VERSION "Generated from PQ35_46 ACAN KMatrix"

NS_ :

BS_:

BU_: XXX AFS Airbag Allrad AppGW_SK BAP_Tester BMS_Hybrid Bremse_ESP_AU714 Bremse_ESP_EPB_EBC460Vi Bremse_MK100_ESC Bremse_MK60EC Bremse_MK70MABS Bremse_TRW_EBC450M Bremse_TRW_ESP Daempfer EPB_TRW EPB_TRW_VW411CS ESP_AU316 FLA Gateway_PQ35 Getriebe_AG6 Getriebe_DL800_R8 Getriebe_DL800_ZSG_R8 Getriebe_DQ Getriebe_DQ_Hyb Getriebe_Sele Gurtmikro_PQ35 HCA LEH_Hybrid LH_EPS_APA LH_EPS_ZF_2G LH_EPS_ZF_3G LPG_Interface_Box LWR LWS Magne_Ride Motor_Diesel Motor_Hybrid Motor_Otto Motor_Slave PDC_PLA Quersperre_VAQ RKA_Plus SAK Waehlhebel Waehlhebel_Sele

BO_ 1494 mPLA_Status: 5 XXX
 SG_ PLS_Bremsleuchte : 30|1@1+ (1,0) [0|1] "" Bremse_MK60EC,Bremse_TRW_ESP,Gateway_PQ35
 SG_ PLS_Anf_Anz : 0|1@1+ (1,0) [0|1] "" Gateway_PQ35
 SG_ PLS_Akustik1 : 1|1@1+ (1,0) [0|1] "" Gateway_PQ35
 SG_ PLS_PL_Exist : 2|1@1+ (1,0) [0|1] "" Gateway_PQ35
 SG_ PLS_Akustik2 : 3|1@1+ (1,0) [0|1] "" Gateway_PQ35
 SG_ PLS_Mehrzg_Aktiv : 4|1@1+ (1,0) [0|1] "" Gateway_PQ35
 SG_ PLS_Pos_OK : 5|1@1+ (1,0) [0|1] "" Gateway_PQ35
 SG_ PLS_PL_Seite : 6|1@1+ (1,0) [0|1] "" Gateway_PQ35
 SG_ PLS_Lenk_Aktiv_Hinweis : 7|1@1+ (1,0) [0|1] "" Gateway_PQ35
 SG_ PLS_Meldungen : 8|5@1+ (1,0) [0|0] "" Gateway_PQ35
 SG_ PLS_Fahrtrichtg_Mehrzg : 13|1@1+ (1,0) [0|1] "" Gateway_PQ35
 SG_ PLS_Text_Multiplexer : 14|2@1+ (1,0) [0|3] "" Gateway_PQ35
 SG_ PLS_Schwellpfeil_rel : 16|4@1+ (1,0) [0|15] "" Gateway_PQ35
 SG_ PLS_Anf_Anz_Schwellpfeil : 20|1@1+ (1,0) [0|1] "" Gateway_PQ35
 SG_ PLS_Laengs_Querluecke : 21|1@1+ (1,0) [0|1] "" Gateway_PQ35
 SG_ PLS_Standby : 22|1@1+ (1,0) [0|1] "" Gateway_PQ35
 SG_ PLS_Bremssymbol : 23|1@1+ (1,0) [0|1] "" Gateway_PQ35
 SG_ PLS_Kurze_Luecke : 24|1@1+ (1,0) [0|1] "" Gateway_PQ35
 SG_ PLS_Schwellpfeil_abs : 25|2@1+ (1,0) [0|3] "" Gateway_PQ35
 SG_ PLS_Akustik : 27|2@1+ (1,0) [0|3] "" Gateway_PQ35
 SG_ PLS_Ausparken_Aktiv : 29|1@1+ (1,0) [0|1] "" Gateway_PQ35
 SG_ PLS_Texte : 31|7@1+ (1,0) [0|32] "" Gateway_PQ35

BO_ 1500 mSoll_Verbauliste_neu: 8 XXX
 SG_ VL1_Motor_SG : 0|1@1+ (1,0) [0|1] "" Bremse_TRW_ESP
 SG_ VL1_Getr_SG : 1|1@1+ (1,0) [0|1] "" Bremse_TRW_ESP
 SG_ VL1_LSM : 4|1@1+ (1,0) [0|1] "" Bremse_TRW_ESP,Motor_Hybrid,Motor_Otto
 SG_ VL1_Airbag : 5|1@1+ (1,0) [0|1] "" Bremse_MK100_ESC,Bremse_TRW_ESP,Motor_Hybrid,Motor_Otto
 SG_ VL1_Allrad : 9|1@1+ (1,0) [0|1] "" Bremse_ESP_EPB_EBC460Vi,Bremse_MK100_ESC,Bremse_MK60EC,Bremse_MK70MABS,Bremse_TRW_EBC450M,Bremse_TRW_ESP,ESP_AU316
 SG_ VL1_ADR : 10|1@1+ (1,0) [0|1] "" Bremse_ESP_EPB_EBC460Vi,Bremse_MK60EC,Bremse_TRW_EBC450M,Bremse_TRW_ESP
 SG_ VL1_Anhaenger : 44|1@1+ (1,0) [0|1] "" Bremse_ESP_EPB_EBC460Vi,Bremse_TRW_EBC450M,Bremse_TRW_ESP,ESP_AU316
 SG_ VL1_ABS : 2|1@1+ (1,0) [0|1] "" Bremse_MK100_ESC,Motor_Hybrid,Motor_Otto
 SG_ VL1_Kombi : 3|1@1+ (1,0) [0|1] "" XXX
 SG_ VL1_Lenkhilfe : 6|1@1+ (1,0) [0|1] "" Bremse_MK60EC
 SG_ VL1_dyn_LWR : 7|1@1+ (1,0) [0|1] "" XXX
 SG_ VL1_res_08 : 8|1@1+ (1,0) [0|1] "" XXX
 SG_ VL1_ADR_getrennt : 11|1@1+ (1,0) [0|1] "" XXX
 SG_ VL1_EPB : 12|1@1+ (1,0) [0|1] "" XXX
 SG_ VL1_res_13 : 13|1@1+ (1,0) [0|1] "" XXX
 SG_ VL1_Daempfer : 14|1@1+ (1,0) [0|1] "" Bremse_MK100_ESC,Bremse_MK60EC
 SG_ VL1_Quersperre : 15|1@1+ (1,0) [0|1] "" Bremse_MK60EC
 SG_ VL1_MotorSlave : 16|1@1+ (1,0) [0|1] "" XXX
 SG_ VL1_SWA : 17|1@1+ (1,0) [0|1] "" XXX
 SG_ VL1_HCA : 18|1@1+ (1,0) [0|1] "" HCA
 SG_ VL1_RKA_Plus : 19|1@1+ (1,0) [0|1] "" XXX
 SG_ VL1_PLA : 20|1@1+ (1,0) [0|1] "" XXX
 SG_ VL1_WFS_KBI : 21|1@1+ (1,0) [0|1] "" XXX
 SG_ VL1_Kombi_KBI : 22|1@1+ (1,0) [0|1] "" XXX
 SG_ VL1_Soll_eq_Ist : 23|1@1+ (1,0) [0|1] "" Bremse_MK60EC,Motor_Hybrid,Motor_Otto
 SG_ VL1_BSG_Komf : 24|1@1+ (1,0) [0|1] "" Motor_Hybrid,Motor_Otto
 SG_ VL1_ZKE : 25|1@1+ (1,0) [0|1] "" XXX
 SG_ VL1_TSG_FT : 26|1@1+ (1,0) [0|1] "" XXX
 SG_ VL1_TSG_BT : 27|1@1+ (1,0) [0|1] "" XXX
 SG_ VL1_TSG_HL : 28|1@1+ (1,0) [0|1] "" XXX
 SG_ VL1_TSG_HR : 29|1@1+ (1,0) [0|1] "" XXX
 SG_ VL1_Memory : 30|1@1+ (1,0) [0|1] "" XXX
 SG_ VL1_Dachmodul_K : 31|1@1+ (1,0) [0|1] "" XXX
 SG_ VL1_Zentralelektrik_II : 32|1@1+ (1,0) [0|1] "" XXX
 SG_ VL1_RDK : 33|1@1+ (1,0) [0|1] "" XXX
 SG_ VL1_Lenksaeule : 34|1@1+ (1,0) [0|1] "" Motor_Hybrid,Motor_Otto
 SG_ VL1_Gateway : 35|1@1+ (1,0) [0|1] "" Motor_Hybrid,Motor_Otto
 SG_ VL1_Clima_Komf : 36|1@1+ (1,0) [0|1] "" Motor_Diesel,Motor_Hybrid,Motor_Otto
 SG_ VL1_Einparkhilfe : 37|1@1+ (1,0) [0|1] "" XXX
 SG_ VL1_PTC_Heizung : 38|1@1+ (1,0) [0|1] "" XXX
 SG_ VL1_Standheiz : 39|1@1+ (1,0) [0|1] "" XXX
 SG_ VL1_Verdeck : 40|1@1+ (1,0) [0|1] "" XXX
 SG_ VL1_RSE_I : 41|1@1+ (1,0) [0|1] "" XXX
 SG_ VL1_res_42 : 42|1@1+ (1,0) [0|1] "" XXX
 SG_ VL1_MDI_I : 43|1@1+ (1,0) [0|1] "" XXX
 SG_ VL1_Memory_BF : 45|1@1+ (1,0) [0|1] "" XXX
 SG_ VL1_Easy_Entry_VF : 46|1@1+ (1,0) [0|1] "" XXX
 SG_ VL1_Easy_Entry_VB : 47|1@1+ (1,0) [0|1] "" XXX
 SG_ VL1_Heckdeckel : 48|1@1+ (1,0) [0|1] "" XXX
 SG_ VL1_Rearview : 49|1@1+ (1,0) [0|1] "" XXX
 SG_ VL1_Sonderfzg_SG : 50|1@1+ (1,0) [0|1] "" XXX
 SG_ VL1_Tastenmodul : 51|1@1+ (1,0) [0|1] "" XXX
 SG_ VL1_Kompass : 52|1@1+ (1,0) [0|1] "" XXX
 SG_ VL1_WFS_K : 53|1@1+ (1,0) [0|1] "" XXX
 SG_ VL1_GSM_Pager : 54|1@1+ (1,0) [0|1] "" XXX
 SG_ VL1_InfoElektronik : 55|1@1+ (1,0) [0|1] "" XXX
 SG_ VL1_DSP : 56|1@1+ (1,0) [0|1] "" XXX
 SG_ VL1_DAB : 57|1@1+ (1,0) [0|1] "" XXX
 SG_ VL1_Telematik : 58|1@1+ (1,0) [0|1] "" XXX
 SG_ VL1_Navigation : 59|1@1+ (1,0) [0|1] "" XXX
 SG_ VL1_TV_Tuner : 60|1@1+ (1,0) [0|1] "" XXX
 SG_ VL1_Neigungsmodul_I : 61|1@1+ (1,0) [0|1] "" XXX
 SG_ VL1_Radio : 62|1@1+ (1,0) [0|1] "" XXX
 SG_ VL1_Telefon : 63|1@1+ (1,0) [0|1] "" XXX

BO_ 1936 mTP_Dyn_ABS_1: 8 XXX
 SG_ TPDyn_ABS_1 : 0|64@1+ (1,0) [0|0] "" Bremse_ESP_AU714,Bremse_MK60EC,Bremse_MK70MABS,Bremse_TRW_EBC450M,Bremse_TRW_ESP,ESP_AU316

BO_ 512 mTP_Er_Tester: 7 XXX
 SG_ Tester_TP_Er : 0|56@1+ (1,0) [0|0] "" AFS,Airbag,Allrad,Bremse_ESP_AU714,Bremse_MK60EC,Bremse_MK70MABS,Bremse_TRW_EBC450M,Bremse_TRW_ESP,Daempfer,EPB_TRW,ESP_AU316,FLA,Getriebe_AG6,Getriebe_DQ,Getriebe_DQ_Hyb,Getriebe_Sele,HCA,LH_EPS_APA,LH_EPS_ZF_2G,LWR,Magne_Ride,Motor_Diesel,Motor_Hybrid,Motor_Otto,Motor_Slave,PDC_PLA,Quersperre_VAQ,RKA_Plus

BO_ 80 mAirbag_1: 4 XXX
 SG_ AB1_Front : 0|1@1+ (1,0) [0|1] "" Bremse_ESP_AU714,Bremse_ESP_EPB_EBC460Vi,Bremse_TRW_EBC450M,Bremse_TRW_ESP,EPB_TRW,ESP_AU316,Gateway_PQ35,HCA,LEH_Hybrid
 SG_ AB1_Heck : 1|1@1+ (1,0) [0|1] "" Bremse_ESP_AU714,Bremse_ESP_EPB_EBC460Vi,Bremse_MK60EC,Bremse_TRW_EBC450M,Bremse_TRW_ESP,EPB_TRW,ESP_AU316,Gateway_PQ35,HCA,LEH_Hybrid
 SG_ AB1_Fa_Seite : 2|1@1+ (1,0) [0|1] "" Bremse_ESP_AU714,Bremse_ESP_EPB_EBC460Vi,Bremse_TRW_EBC450M,Bremse_TRW_ESP,EPB_TRW,ESP_AU316,Gateway_PQ35,HCA,LEH_Hybrid
 SG_ AB1_Bf_Seite : 3|1@1+ (1,0) [0|1] "" Bremse_ESP_AU714,Bremse_ESP_EPB_EBC460Vi,Bremse_TRW_EBC450M,Bremse_TRW_ESP,EPB_TRW,ESP_AU316,Gateway_PQ35,HCA,LEH_Hybrid
 SG_ AB1_Rollover : 4|1@1+ (1,0) [0|1] "" Bremse_ESP_AU714,Bremse_ESP_EPB_EBC460Vi,Bremse_MK100_ESC,Bremse_MK60EC,Bremse_MK70MABS,Bremse_TRW_EBC450M,Bremse_TRW_ESP,EPB_TRW,ESP_AU316,Gateway_PQ35
 SG_ AB1_Gurt_Fa : 12|2@1+ (1,0) [0|3] "" AppGW_SK,Bremse_ESP_AU714,Bremse_ESP_EPB_EBC460Vi,Bremse_MK100_ESC,Bremse_MK60EC,Bremse_TRW_EBC450M,Bremse_TRW_ESP,EPB_TRW,EPB_TRW_VW411CS,ESP_AU316,Gateway_PQ35,Getriebe_DL800_R8,Gurtmikro_PQ35,Motor_Diesel,Motor_Hybrid,Motor_Otto
 SG_ AB1_Zaehler : 20|4@1+ (1,0) [0|15] "" BMS_Hybrid,Bremse_ESP_AU714,Bremse_ESP_EPB_EBC460Vi,Bremse_MK100_ESC,Bremse_MK60EC,Bremse_TRW_EBC450M,Bremse_TRW_ESP,EPB_TRW,EPB_TRW_VW411CS,ESP_AU316,Gateway_PQ35,HCA,LEH_Hybrid,Motor_Diesel,Motor_Hybrid,Motor_Otto
 SG_ AB1_Checksumme : 24|8@1+ (1,0) [0|255] "" BMS_Hybrid,Bremse_ESP_AU714,Bremse_ESP_EPB_EBC460Vi,Bremse_MK100_ESC,Bremse_MK60EC,Bremse_TRW_EBC450M,Bremse_TRW_ESP,EPB_TRW,EPB_TRW_VW411CS,ESP_AU316,Gateway_PQ35,HCA,LEH_Hybrid,Motor_Diesel,Motor_Hybrid,Motor_Otto
 SG_ AB1_Intens : 5|3@1+ (1,0) [0|7] "" BMS_Hybrid,Bremse_ESP_AU714,Bremse_MK100_ESC,Bremse_MK60EC,Bremse_MK70MABS,Gateway_PQ35,Gurtmikro_PQ35,LEH_Hybrid,Motor_Diesel,Motor_Hybrid,Motor_Otto
 SG_ AB1_Lampe : 8|1@1+ (1,0) [0|1] "" AppGW_SK,Gateway_PQ35
 SG_ AB1_Status : 9|1@1+ (1,0) [0|1] "" Gateway_PQ35
 SG_ AB1_Beifahrer : 10|1@1+ (1,0) [0|1] "" Gateway_PQ35
 SG_ AB1_System : 11|1@1+ (1,0) [0|1] "" Bremse_ESP_AU714,Gateway_PQ35,HCA,LEH_Hybrid
 SG_ AB1_Gurt_Bf : 14|2@1+ (1,0) [0|3] "" AppGW_SK,Gateway_PQ35,Gurtmikro_PQ35
 SG_ AB1_Diagnose : 16|1@1+ (1,0) [0|1] "" EPB_TRW,ESP_AU316,Gateway_PQ35
 SG_ AB1_Stellglied : 17|1@1+ (1,0) [0|1] "" BMS_Hybrid,Gateway_PQ35,LEH_Hybrid,Motor_Diesel,Motor_Otto
 SG_ AB1_BF_Warnung : 18|1@1+ (1,0) [0|1] "" Gateway_PQ35
 SG_ AB1_Fehlereintr : 19|1@1+ (1,0) [0|1] "" Gateway_PQ35

BO_ 704 mAllrad_1: 8 XXX
 SG_ AL1_Fehler : 0|1@1+ (1,0) [0|1] "" Bremse_ESP_EPB_EBC460Vi,Bremse_MK60EC,Bremse_TRW_EBC450M,Bremse_TRW_ESP,ESP_AU316,Gateway_PQ35,RKA_Plus
 SG_ AL1_Uebertemp : 1|1@1+ (1,0) [0|1] "" Bremse_ESP_EPB_EBC460Vi,Bremse_TRW_EBC450M,Bremse_TRW_ESP,ESP_AU316,Gateway_PQ35
 SG_ AL1_Sta_Kup : 2|1@1+ (1,0) [0|1] "" Bremse_ESP_EPB_EBC460Vi,Bremse_MK100_ESC,Bremse_MK60EC,Bremse_TRW_EBC450M,Bremse_TRW_ESP,ESP_AU316,Gateway_PQ35
 SG_ AL1_Kup_offen : 3|1@1+ (1,0) [0|1] "" Bremse_ESP_EPB_EBC460Vi,Bremse_TRW_EBC450M,Bremse_TRW_ESP,ESP_AU316,Gateway_PQ35,RKA_Plus
 SG_ AL1_Notlauf : 4|1@1+ (1,0) [0|1] "" Bremse_ESP_EPB_EBC460Vi,Bremse_TRW_EBC450M,Bremse_TRW_ESP,ESP_AU316,Gateway_PQ35
 SG_ AL1_Warnlampe : 5|1@1+ (1,0) [0|1] "" Bremse_ESP_EPB_EBC460Vi,Bremse_TRW_EBC450M,Bremse_TRW_ESP,ESP_AU316,Gateway_PQ35
 SG_ AL1_Einheit : 7|1@1+ (1,0) [0|1] "" Bremse_ESP_EPB_EBC460Vi,Bremse_MK60EC,Bremse_TRW_EBC450M,Bremse_TRW_ESP,ESP_AU316,Gateway_PQ35,RKA_Plus
 SG_ AL1_Ist_Nm : 8|8@1+ (7,-896) [-896|882] "Unit_NewtoMeter" Bremse_ESP_EPB_EBC460Vi,Bremse_MK100_ESC,Bremse_MK60EC,Bremse_TRW_EBC450M,Bremse_TRW_ESP,ESP_AU316,Gateway_PQ35,RKA_Plus
 SG_ AL1_Ist_Proz : 8|8@1+ (0.794,-101.632) [0|100.044] "Unit_PerCent" Bremse_ESP_EPB_EBC460Vi,Bremse_MK100_ESC,Bremse_MK60EC,Bremse_TRW_EBC450M,Bremse_TRW_ESP,ESP_AU316,Gateway_PQ35,RKA_Plus
 SG_ AL1_Zaehler : 60|4@1+ (1,0) [0|15] "" Bremse_ESP_EPB_EBC460Vi,Bremse_MK100_ESC,Bremse_MK60EC,Bremse_TRW_EBC450M,Bremse_TRW_ESP,ESP_AU316,Gateway_PQ35
 SG_ AL1_Limiter : 6|1@1+ (1,0) [0|1] "" Gateway_PQ35
 SG_ AL1_Sta_PNG : 16|3@1+ (1,0) [0|7] "" Bremse_MK100_ESC,Bremse_MK60EC,Gateway_PQ35,Getriebe_DL800_R8,Getriebe_DQ,Getriebe_DQ_Hyb
 SG_ AL1_Anz_blinken : 19|1@1+ (1,0) [0|1] "" Gateway_PQ35
 SG_ AL1_Sta_Laengssp : 20|2@1+ (1,0) [0|3] "" Gateway_PQ35
 SG_ AL1_Sta_Quersp : 22|2@1+ (1,0) [0|3] "" Gateway_PQ35
 SG_ AL1_Schalten : 24|1@1+ (1,0) [0|1] "" Gateway_PQ35
 SG_ AL1_Vorwarnung : 25|1@1+ (1,0) [0|1] "" Gateway_PQ35,Getriebe_DL800_R8,Getriebe_DQ,Getriebe_DQ_Hyb
 SG_ AL1_Stellung_Getr : 26|1@1+ (1,0) [0|1] "" Bremse_MK100_ESC,Bremse_MK60EC,Gateway_PQ35
 SG_ AL1_AnfVerteiler : 27|1@1+ (1,0) [0|1] "" Bremse_MK100_ESC,Gateway_PQ35
 SG_ AL1_Sta_VA : 28|2@1+ (1,0) [0|3] "" Gateway_PQ35
 SG_ AL1_KupSteifig_F : 30|1@1+ (1,0) [0|1] "" Gateway_PQ35
 SG_ AL1_Fehlereintr : 31|1@1+ (1,0) [0|1] "" Gateway_PQ35
 SG_ AL1_KupplTemp : 32|8@1+ (1,-60) [-60|193] "Unit_DegreCelsi" Bremse_MK100_ESC,Gateway_PQ35
 SG_ AL1_FaWu_Laengs : 40|2@1+ (1,0) [0|3] "" Gateway_PQ35
 SG_ AL1_FaWu_HA : 42|2@1+ (1,0) [0|3] "" Gateway_PQ35
 SG_ AL1_FaWu_VA : 44|2@1+ (1,0) [0|3] "" Gateway_PQ35
 SG_ AL1_Quersp_Sta : 46|2@1+ (1,0) [0|3] "" Gateway_PQ35
 SG_ AL1_Limit_maxkmh : 48|8@1+ (1,0) [0|254] "" Gateway_PQ35
 SG_ AL1_Diff_Verbau : 56|1@1+ (1,0) [0|1] "" Gateway_PQ35
 SG_ AL1_Diff_Lampe : 57|1@1+ (1,0) [0|1] "" Gateway_PQ35
 SG_ AL1_Diff_Gong : 58|1@1+ (1,0) [0|1] "" Gateway_PQ35
 SG_ AL1_Warnton : 59|1@1+ (1,0) [0|1] "" Gateway_PQ35

BO_ 870 mAWV: 8 XXX
 SG_ AWV_Checksumme : 0|8@1+ (1,0) [0|255] "" Bremse_ESP_EPB_EBC460Vi,Bremse_MK100_ESC,Bremse_MK60EC,Bremse_TRW_EBC450M,Bremse_TRW_ESP,Daempfer,HCA
 SG_ AWV_Zaehler : 8|4@1+ (1,0) [0|15] "" Bremse_ESP_EPB_EBC460Vi,Bremse_MK100_ESC,Bremse_MK60EC,Bremse_TRW_EBC450M,Bremse_TRW_ESP,Daempfer,HCA
 SG_ AWV_1_Freigabe : 16|1@1+ (1,0) [0|1] "" Bremse_ESP_EPB_EBC460Vi,Bremse_MK100_ESC,Bremse_MK60EC,Bremse_TRW_EBC450M,Bremse_TRW_ESP
 SG_ AWV_1_Prefill : 17|1@1+ (1,0) [0|1] "" Bremse_ESP_EPB_EBC460Vi,Bremse_MK100_ESC,Bremse_MK60EC,Bremse_TRW_EBC450M,Bremse_TRW_ESP
 SG_ AWV_1_Parameter : 18|2@1+ (1,0) [0|3] "" Bremse_ESP_EPB_EBC460Vi,Bremse_MK100_ESC,Bremse_MK60EC,Bremse_TRW_EBC450M,Bremse_TRW_ESP
 SG_ AWV_2_Freigabe : 32|1@1+ (1,0) [0|1] "" Bremse_ESP_EPB_EBC460Vi,Bremse_MK100_ESC,Bremse_MK60EC,Bremse_TRW_EBC450M,Bremse_TRW_ESP,HCA
 SG_ AWV_2_Ruckprofil : 33|3@1+ (1,0) [0|7] "" Bremse_ESP_EPB_EBC460Vi,Bremse_MK100_ESC,Bremse_MK60EC,Bremse_TRW_EBC450M,Bremse_TRW_ESP
 SG_ AWV_Text : 12|4@1+ (1,0) [0|14] "" XXX
 SG_ AWV_CityANB_Auspraegung : 21|1@1+ (1,0) [0|1] "" XXX
 SG_ AWV_2_Status : 24|1@1+ (1,0) [0|1] "" XXX
 SG_ AWV_2_Fehler : 25|1@1+ (1,0) [0|1] "" XXX
 SG_ AWV_2_SU_Warnzeit : 26|2@1+ (1,0) [0|3] "" XXX
 SG_ AWV_2_SU_Bremsruck : 28|1@1+ (1,0) [0|1] "" XXX
 SG_ AWV_2_SU_Gong : 29|1@1+ (1,0) [0|1] "" XXX
 SG_ AWV_2_SU_Lampe : 30|1@1+ (1,0) [0|1] "" XXX
 SG_ AWV_2_Umfeldwarn : 31|1@1+ (1,0) [0|1] "" XXX
 SG_ AWV_2_Warnton : 36|1@1+ (1,0) [0|1] "" XXX
 SG_ AWV_2_Warnsymbol : 37|1@1+ (1,0) [0|1] "" XXX
 SG_ AWV_Infoton : 38|1@1+ (1,0) [0|1] "" XXX
 SG_ AWV_2_Gurtstraffer : 39|1@1+ (1,0) [0|1] "" XXX
 SG_ AWV_Konfiguration_Menueanf : 40|1@1+ (1,0) [0|1] "" XXX
 SG_ AWV_Konfiguration_Vorw_Menueanf : 41|1@1+ (1,0) [0|1] "" XXX
 SG_ AWV_Konfiguration_Status : 42|1@1+ (1,0) [0|1] "" XXX
 SG_ AWV_Konfiguration_Vorw_Status : 43|1@1+ (1,0) [0|1] "" XXX
 SG_ AWV_2_Abstandswarnung : 51|1@1+ (1,0) [0|1] "" XXX
 SG_ AWV_only : 20|1@1+ (1,0) [0|1] "" Bremse_ESP_EPB_EBC460Vi,Bremse_MK100_ESC,Bremse_MK60EC
 SG_ AWV_Halten : 22|1@1+ (1,0) [0|1] "" Bremse_ESP_EPB_EBC460Vi,Bremse_MK100_ESC,Bremse_MK60EC,Bremse_TRW_EBC450M
 SG_ ANB_Teilbremsung_Freigabe : 23|1@1+ (1,0) [0|1] "" Bremse_ESP_EPB_EBC460Vi,Bremse_MK100_ESC,Bremse_MK60EC,Bremse_TRW_EBC450M,Daempfer
 SG_ ANB_Zielbremsung_Freigabe : 52|1@1+ (1,0) [0|1] "" Bremse_ESP_EPB_EBC460Vi,Bremse_MK100_ESC,Bremse_MK60EC,Bremse_TRW_EBC450M,Daempfer
 SG_ ANB_CM_Anforderung : 53|1@1+ (1,0) [0|1] "" Bremse_ESP_EPB_EBC460Vi,Bremse_MK100_ESC,Bremse_MK60EC,Bremse_TRW_EBC450M
 SG_ ANB_Ziel_Teilbrems_Verz_Anf : 54|10@1+ (0.024,-20.016) [-20.016|4.536] "Unit_MeterPerSeconSquar" Bremse_ESP_EPB_EBC460Vi,Bremse_MK100_ESC,Bremse_MK60EC,Bremse_TRW_EBC450M,Daempfer

BO_ 1392 mBSG_Last: 5 XXX
 SG_ BSL_ZAS_Kl_15 : 1|1@1+ (1,0) [0|1] "" Airbag,AppGW_SK,BMS_Hybrid,Bremse_ESP_EPB_EBC460Vi,Bremse_MK60EC,Bremse_TRW_EBC450M,Bremse_TRW_ESP,EPB_TRW,EPB_TRW_VW411CS,ESP_AU316,FLA,Gurtmikro_PQ35,Motor_Diesel,Motor_Hybrid,Motor_Otto,PDC_PLA
 SG_ BSL_BSG_3_alt : 33|1@1+ (1,0) [0|1] "" Airbag,BMS_Hybrid,Bremse_ESP_EPB_EBC460Vi,Bremse_MK60EC,Bremse_TRW_EBC450M,Bremse_TRW_ESP,EPB_TRW_VW411CS,ESP_AU316,FLA,Gurtmikro_PQ35,HCA,LH_EPS_APA,Motor_Diesel,Motor_Hybrid,Motor_Otto,PDC_PLA
 SG_ BSL_Starterlaubnis : 39|1@1+ (1,0) [0|1] "" Bremse_ESP_EPB_EBC460Vi,Bremse_MK60EC,Bremse_TRW_EBC450M,Bremse_TRW_ESP,ESP_AU316,Motor_Diesel,Motor_Otto
 SG_ BSL_Parklicht : 4|1@1+ (1,0) [0|1] "" AppGW_SK
 SG_ BSL_LL_Anheb2 : 5|1@1+ (1,0) [0|1] "" Motor_Diesel,Motor_Hybrid,Motor_Otto
 SG_ BSL_Kl_15_Motor : 6|1@1+ (1,0) [0|1] "" XXX
 SG_ BSL_Kl_L : 7|1@1+ (1,0) [0|1] "" XXX
 SG_ BSL_LL_Anheb : 8|1@1+ (1,0) [0|1] "" Motor_Diesel,Motor_Hybrid,Motor_Otto
 SG_ BSL_Sta_StBat : 11|2@1+ (1,0) [0|3] "" XXX
 SG_ BSL_Fehlereintr : 13|1@1+ (1,0) [0|1] "" XXX
 SG_ BSL_Sta_LWR : 14|1@1+ (1,0) [0|1] "" XXX
 SG_ BSL_Motor_Haube : 15|1@1+ (1,0) [0|1] "" Motor_Diesel,Motor_Hybrid,Motor_Otto
 SG_ BSL_Hecksch : 24|1@1+ (1,0) [0|1] "" XXX
 SG_ BSL_Frontsch : 25|1@1+ (1,0) [0|1] "" XXX
 SG_ BSL_Aussensp : 26|1@1+ (1,0) [0|1] "" XXX
 SG_ BSL_Sitzheiz : 27|1@1+ (1,0) [0|1] "" XXX
 SG_ BSL_Lenkradheiz : 28|1@1+ (1,0) [0|1] "" XXX
 SG_ BSL_Wasserheiz : 29|1@1+ (1,0) [0|1] "" XXX
 SG_ BSL_Sitzbelueft : 30|1@1+ (1,0) [0|1] "" XXX
 SG_ BSL_Clima : 31|1@1+ (1,0) [0|1] "" Motor_Diesel,Motor_Hybrid,Motor_Otto
 SG_ BSL_BSG_2_alt : 32|1@1+ (1,0) [0|1] "" Motor_Diesel,Motor_Hybrid,Motor_Otto
 SG_ BSL_Kuehlerlueft : 34|1@1+ (1,0) [0|1] "" LH_EPS_ZF_2G,LH_EPS_ZF_3G,Motor_Diesel,Motor_Hybrid,Motor_Otto
 SG_ BSL_Ab_Batterie : 35|1@1+ (1,0) [0|1] "" LH_EPS_APA,LH_EPS_ZF_2G,LH_EPS_ZF_3G,Motor_Diesel,Motor_Hybrid,Motor_Otto
 SG_ BSL_Weckursache_ACAN : 36|2@1+ (1,0) [0|3] "" Motor_Hybrid,Motor_Otto
 SG_ BSL_Wake_Up_ACAN : 38|1@1+ (1,0) [0|1] "" Motor_Hybrid,Motor_Otto
 SG_ BSL_ZAS_Kl_S : 0|1@1+ (1,0) [0|1] "" AppGW_SK,Bremse_ESP_EPB_EBC460Vi,EPB_TRW,EPB_TRW_VW411CS,ESP_AU316,Gurtmikro_PQ35
 SG_ BSL_ZAS_Kl_X : 2|1@1+ (1,0) [0|1] "" AFS,Bremse_ESP_EPB_EBC460Vi,EPB_TRW,EPB_TRW_VW411CS,ESP_AU316,FLA,Getriebe_AG6,HCA,LWR,Motor_Diesel,Motor_Hybrid,Motor_Otto,PDC_PLA
 SG_ BSL_ZAS_Kl_50 : 3|1@1+ (1,0) [0|1] "" AFS,Bremse_ESP_EPB_EBC460Vi,Bremse_TRW_EBC450M,EPB_TRW,EPB_TRW_VW411CS,ESP_AU316,LH_EPS_APA,LWR,Magne_Ride,Motor_Diesel,Motor_Hybrid,Motor_Otto
 SG_ BSL_Sta_UBat : 9|2@1+ (1,0) [0|3] "" Bremse_ESP_EPB_EBC460Vi,EPB_TRW,ESP_AU316
 SG_ BSL_UBat : 16|8@1+ (0.05,5) [5|17.7] "Unit_Volt" AppGW_SK,Bremse_ESP_EPB_EBC460Vi,EPB_TRW,ESP_AU316

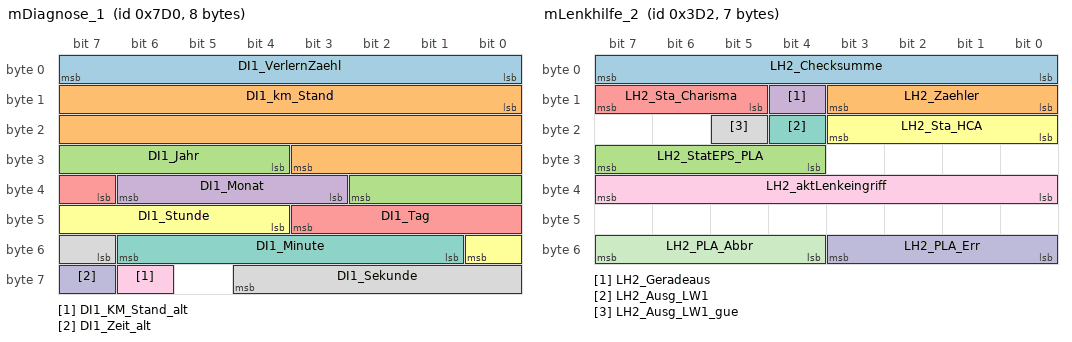
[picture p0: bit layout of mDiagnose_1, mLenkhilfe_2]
BO_ 2000 mDiagnose_1: 8 XXX
 SG_ DI1_VerlernZaehl : 0|8@1+ (1,0) [0|254] "" AFS,Airbag,Allrad,BMS_Hybrid,Bremse_ESP_AU714,Bremse_ESP_EPB_EBC460Vi,Bremse_MK100_ESC,Bremse_MK60EC,Bremse_TRW_EBC450M,Bremse_TRW_ESP,Daempfer,EPB_TRW,EPB_TRW_VW411CS,ESP_AU316,FLA,Getriebe_AG6,Getriebe_DL800_R8,Getriebe_DL800_ZSG_R8,Getriebe_DQ,Getriebe_DQ_Hyb,Gurtmikro_PQ35,HCA,LEH_Hybrid,LH_EPS_APA,LWR,Magne_Ride,PDC_PLA,Quersperre_VAQ,RKA_Plus
 SG_ DI1_km_Stand : 8|20@1+ (1,0) [0|1048575] "Unit_KiloMeter" AFS,Airbag,Allrad,BMS_Hybrid,Bremse_ESP_AU714,Bremse_ESP_EPB_EBC460Vi,Bremse_MK100_ESC,Bremse_TRW_EBC450M,Bremse_TRW_ESP,Daempfer,EPB_TRW,EPB_TRW_VW411CS,ESP_AU316,FLA,Getriebe_AG6,Getriebe_DL800_R8,Getriebe_DL800_ZSG_R8,Getriebe_DQ,Getriebe_DQ_Hyb,Gurtmikro_PQ35,HCA,LEH_Hybrid,LH_EPS_APA,LWR,Magne_Ride,Motor_Diesel,Motor_Hybrid,Motor_Otto,PDC_PLA,Quersperre_VAQ,RKA_Plus
 SG_ DI1_Jahr : 28|7@1+ (1,2000) [2000|2127] "Unit_Year" AFS,Airbag,Allrad,BMS_Hybrid,Bremse_ESP_AU714,Bremse_ESP_EPB_EBC460Vi,Bremse_MK100_ESC,Bremse_MK60EC,Bremse_MK70MABS,Bremse_TRW_EBC450M,Bremse_TRW_ESP,Daempfer,EPB_TRW,EPB_TRW_VW411CS,ESP_AU316,FLA,Getriebe_AG6,Getriebe_DL800_R8,Getriebe_DL800_ZSG_R8,Getriebe_DQ,Getriebe_DQ_Hyb,Gurtmikro_PQ35,HCA,LEH_Hybrid,LH_EPS_APA,LH_EPS_ZF_2G,LH_EPS_ZF_3G,LWR,Magne_Ride,Motor_Diesel,Motor_Hybrid,Motor_Otto,PDC_PLA,Quersperre_VAQ,RKA_Plus
 SG_ DI1_Monat : 35|4@1+ (1,0) [1|12] "Unit_Month" AFS,Airbag,Allrad,BMS_Hybrid,Bremse_ESP_AU714,Bremse_ESP_EPB_EBC460Vi,Bremse_MK100_ESC,Bremse_MK60EC,Bremse_MK70MABS,Bremse_TRW_EBC450M,Bremse_TRW_ESP,Daempfer,EPB_TRW,EPB_TRW_VW411CS,ESP_AU316,FLA,Getriebe_AG6,Getriebe_DL800_R8,Getriebe_DL800_ZSG_R8,Getriebe_DQ,Getriebe_DQ_Hyb,Gurtmikro_PQ35,HCA,LEH_Hybrid,LH_EPS_APA,LH_EPS_ZF_2G,LH_EPS_ZF_3G,LWR,Magne_Ride,Motor_Diesel,Motor_Hybrid,Motor_Otto,PDC_PLA,Quersperre_VAQ,RKA_Plus
 SG_ DI1_Tag : 39|5@1+ (1,0) [0|31] "Unit_Day" AFS,Airbag,Allrad,BMS_Hybrid,Bremse_ESP_AU714,Bremse_ESP_EPB_EBC460Vi,Bremse_MK100_ESC,Bremse_MK60EC,Bremse_MK70MABS,Bremse_TRW_EBC450M,Bremse_TRW_ESP,Daempfer,EPB_TRW,EPB_TRW_VW411CS,ESP_AU316,FLA,Getriebe_AG6,Getriebe_DL800_R8,Getriebe_DL800_ZSG_R8,Getriebe_DQ,Getriebe_DQ_Hyb,Gurtmikro_PQ35,HCA,LEH_Hybrid,LH_EPS_APA,LH_EPS_ZF_2G,LH_EPS_ZF_3G,LWR,Magne_Ride,Motor_Diesel,Motor_Hybrid,Motor_Otto,PDC_PLA,Quersperre_VAQ,RKA_Plus
 SG_ DI1_Stunde : 44|5@1+ (1,0) [0|23] "Unit_Hours" AFS,Airbag,Allrad,BMS_Hybrid,Bremse_ESP_AU714,Bremse_ESP_EPB_EBC460Vi,Bremse_MK100_ESC,Bremse_MK60EC,Bremse_TRW_EBC450M,Bremse_TRW_ESP,Daempfer,EPB_TRW,EPB_TRW_VW411CS,ESP_AU316,FLA,Getriebe_AG6,Getriebe_DL800_R8,Getriebe_DL800_ZSG_R8,Getriebe_DQ,Getriebe_DQ_Hyb,Gurtmikro_PQ35,HCA,LEH_Hybrid,LH_EPS_APA,LH_EPS_ZF_2G,LH_EPS_ZF_3G,LWR,Magne_Ride,Motor_Diesel,Motor_Hybrid,Motor_Otto,PDC_PLA,Quersperre_VAQ,RKA_Plus
 SG_ DI1_Minute : 49|6@1+ (1,0) [0|59] "Unit_Minut" AFS,Airbag,Allrad,BMS_Hybrid,Bremse_ESP_AU714,Bremse_ESP_EPB_EBC460Vi,Bremse_MK100_ESC,Bremse_MK60EC,Bremse_TRW_EBC450M,Bremse_TRW_ESP,Daempfer,EPB_TRW,EPB_TRW_VW411CS,ESP_AU316,FLA,Getriebe_AG6,Getriebe_DL800_R8,Getriebe_DL800_ZSG_R8,Getriebe_DQ,Getriebe_DQ_Hyb,Gurtmikro_PQ35,HCA,LEH_Hybrid,LH_EPS_APA,LH_EPS_ZF_2G,LH_EPS_ZF_3G,LWR,Magne_Ride,Motor_Diesel,Motor_Hybrid,Motor_Otto,PDC_PLA,Quersperre_VAQ,RKA_Plus
 SG_ DI1_Sekunde : 55|6@1+ (1,0) [0|59] "Unit_Secon" AFS,Airbag,Allrad,BMS_Hybrid,Bremse_ESP_AU714,Bremse_ESP_EPB_EBC460Vi,Bremse_MK100_ESC,Bremse_MK60EC,Bremse_TRW_EBC450M,Bremse_TRW_ESP,Daempfer,EPB_TRW,EPB_TRW_VW411CS,ESP_AU316,FLA,Getriebe_AG6,Getriebe_DL800_R8,Getriebe_DL800_ZSG_R8,Getriebe_DQ,Getriebe_DQ_Hyb,Gurtmikro_PQ35,HCA,LEH_Hybrid,LH_EPS_APA,LH_EPS_ZF_2G,LH_EPS_ZF_3G,LWR,Magne_Ride,Motor_Diesel,Motor_Hybrid,Motor_Otto,PDC_PLA,Quersperre_VAQ,RKA_Plus
 SG_ DI1_KM_Stand_alt : 62|1@1+ (1,0) [0|1] "" AFS,Airbag,Allrad,BMS_Hybrid,Bremse_ESP_AU714,Bremse_MK100_ESC,Daempfer,EPB_TRW_VW411CS,FLA,Getriebe_DL800_R8,Getriebe_DL800_ZSG_R8,Gurtmikro_PQ35,HCA,LEH_Hybrid,LH_EPS_APA,LWR,Magne_Ride,Motor_Diesel,Motor_Hybrid,Motor_Otto,PDC_PLA,Quersperre_VAQ,RKA_Plus
 SG_ DI1_Zeit_alt : 63|1@1+ (1,0) [0|1] "" AFS,Airbag,Allrad,BMS_Hybrid,Bremse_ESP_AU714,Bremse_MK100_ESC,Bremse_MK60EC,Daempfer,EPB_TRW_VW411CS,FLA,Getriebe_DL800_R8,Getriebe_DL800_ZSG_R8,Gurtmikro_PQ35,HCA,LEH_Hybrid,LH_EPS_APA,LH_EPS_ZF_2G,LH_EPS_ZF_3G,LWR,Magne_Ride,Motor_Diesel,Motor_Hybrid,Motor_Otto,PDC_PLA,Quersperre_VAQ,RKA_Plus

BO_ 1088 mGetriebe_1: 8 XXX
 SG_ GE1_Schaltung : 0|1@1+ (1,0) [0|1] "" Bremse_ESP_AU714,Bremse_ESP_EPB_EBC460Vi,Bremse_MK100_ESC,Bremse_MK60EC,Bremse_MK70MABS,Bremse_TRW_EBC450M,Bremse_TRW_ESP,ESP_AU316,Gateway_PQ35,Motor_Diesel,Motor_Hybrid,Motor_Otto,RKA_Plus
 SG_ GE1_Zielgang : 8|4@1+ (1,0) [0|15] "" Allrad,Bremse_ESP_AU714,Bremse_ESP_EPB_EBC460Vi,Bremse_MK100_ESC,Bremse_MK60EC,Bremse_MK70MABS,Bremse_TRW_EBC450M,Bremse_TRW_ESP,ESP_AU316,Gateway_PQ35,Motor_Diesel,Motor_Hybrid,Motor_Otto,RKA_Plus
 SG_ GE1_Wahl_Pos : 12|4@1+ (1,0) [0|15] "" AppGW_SK,Bremse_ESP_AU714,Bremse_ESP_EPB_EBC460Vi,Bremse_MK100_ESC,Bremse_MK60EC,Bremse_MK70MABS,Bremse_TRW_EBC450M,Bremse_TRW_ESP,EPB_TRW,EPB_TRW_VW411CS,ESP_AU316,Gateway_PQ35,Motor_Diesel,Motor_Hybrid,Motor_Otto,PDC_PLA,RKA_Plus
 SG_ GE1_Mrad_Mkurb : 16|8@1+ (0.1,0) [0|25.4] "" Bremse_ESP_EPB_EBC460Vi,Bremse_MK100_ESC,Bremse_MK60EC,Bremse_MK70MABS,Bremse_TRW_EBC450M,Bremse_TRW_ESP,EPB_TRW,EPB_TRW_VW411CS,ESP_AU316,Gateway_PQ35,Motor_Diesel,Motor_Hybrid,Motor_Otto
 SG_ GE1_Notlauf : 40|4@1+ (1,0) [1|15] "" Bremse_ESP_EPB_EBC460Vi,Bremse_TRW_EBC450M,Bremse_TRW_ESP,Gateway_PQ35,Motor_Diesel,Motor_Hybrid,Motor_Otto
 SG_ GE1_Zaehler : 51|4@1+ (1,0) [0|15] "" Bremse_ESP_AU714,Bremse_ESP_EPB_EBC460Vi,Bremse_MK100_ESC,Bremse_MK60EC,Bremse_TRW_EBC450M,Bremse_TRW_ESP,EPB_TRW,EPB_TRW_VW411CS,ESP_AU316,Gateway_PQ35,Motor_Diesel,Motor_Hybrid,Motor_Otto
 SG_ GE1_Sta_Schutz : 1|1@1+ (1,0) [0|1] "" Gateway_PQ35,Motor_Diesel,Motor_Hybrid,Motor_Otto
 SG_ GE1_Klimakompr : 2|1@1+ (1,0) [0|1] "" Gateway_PQ35,Motor_Diesel,Motor_Hybrid,Motor_Otto
 SG_ GE1_WK : 3|2@1+ (1,0) [0|3] "" Allrad,Gateway_PQ35,Motor_Diesel,Motor_Hybrid,Motor_Otto,RKA_Plus
 SG_ GE1_StSt_Info : 5|2@1+ (1,0) [0|3] "" Bremse_ESP_AU714,Gateway_PQ35,Motor_Diesel,Motor_Otto
 SG_ GE1_EGS_Anf : 7|1@1+ (1,0) [0|1] "" Gateway_PQ35,Motor_Diesel,Motor_Hybrid,Motor_Otto
 SG_ GE1_Soll_Mo : 24|8@1+ (0.39,0) [0|99.06] "Unit_PerCent" Gateway_PQ35,Motor_Diesel,Motor_Hybrid,Motor_Otto
 SG_ GE1_Fahrwistd : 32|8@1+ (0.249,-31.623) [-31.623|31.623] "" Gateway_PQ35,Motor_Diesel,Motor_Hybrid,Motor_Otto
 SG_ GE1_Kuehlung : 44|2@1+ (1,0) [0|3] "" Gateway_PQ35,Motor_Diesel,Motor_Hybrid,Motor_Otto
 SG_ GE1_Sta_OBD : 47|1@1+ (1,0) [0|1] "" Gateway_PQ35,Motor_Diesel,Motor_Hybrid,Motor_Otto
 SG_ GE1_LaunchControl : 48|1@1+ (1,0) [0|1] "" Bremse_ESP_AU714,Bremse_MK100_ESC,Bremse_MK60EC,Bremse_MK70MABS,Gateway_PQ35,Motor_Diesel,Motor_Hybrid,Motor_Otto
 SG_ GE1_Infobit : 49|1@1+ (1,0) [0|1] "" Gateway_PQ35
 SG_ GE1_SleepInd : 50|1@1+ (1,0) [0|1] "" Gateway_PQ35
 SG_ GE1_Fehlereintr : 55|1@1+ (1,0) [0|1] "" Gateway_PQ35
 SG_ GE1_WaVerl_Mo : 56|8@1+ (0.39,0) [0|99.06] "Unit_PerCent" Gateway_PQ35,Motor_Diesel,Motor_Hybrid,Motor_Otto

BO_ 1490 mIdent: 8 XXX
 SG_ IDT_Mux : 0|2@1+ (1,0) [0|2] "" Airbag,AppGW_SK,Bremse_ESP_EPB_EBC460Vi,Bremse_MK100_ESC,Bremse_MK60EC,Bremse_MK70MABS,Bremse_TRW_EBC450M,Bremse_TRW_ESP,Daempfer,EPB_TRW,EPB_TRW_VW411CS,ESP_AU316,LH_EPS_APA,LH_EPS_ZF_2G,LH_EPS_ZF_3G,LWS,Magne_Ride
 SG_ IDT_VIN_13 : 24|8@1+ (1,0) [0|255] "" Airbag,AppGW_SK,Bremse_ESP_EPB_EBC460Vi,Bremse_MK100_ESC,Bremse_MK60EC,Bremse_TRW_EBC450M,Bremse_TRW_ESP,Daempfer,EPB_TRW,EPB_TRW_VW411CS,ESP_AU316,LWS,Magne_Ride
 SG_ IDT_VIN_14 : 32|8@1+ (1,0) [0|255] "" Airbag,AppGW_SK,Bremse_ESP_EPB_EBC460Vi,Bremse_MK100_ESC,Bremse_MK60EC,Bremse_MK70MABS,Bremse_TRW_EBC450M,Bremse_TRW_ESP,Daempfer,EPB_TRW,EPB_TRW_VW411CS,ESP_AU316,LH_EPS_APA,LH_EPS_ZF_2G,LH_EPS_ZF_3G,LWS,Magne_Ride
 SG_ IDT_VIN_15 : 40|8@1+ (1,0) [0|255] "" Airbag,AppGW_SK,Bremse_ESP_EPB_EBC460Vi,Bremse_MK100_ESC,Bremse_MK60EC,Bremse_MK70MABS,Bremse_TRW_EBC450M,Bremse_TRW_ESP,Daempfer,EPB_TRW,EPB_TRW_VW411CS,ESP_AU316,LH_EPS_APA,LH_EPS_ZF_2G,LH_EPS_ZF_3G,LWS,Magne_Ride
 SG_ IDT_VIN_16 : 48|8@1+ (1,0) [0|255] "" Airbag,AppGW_SK,Bremse_ESP_EPB_EBC460Vi,Bremse_MK100_ESC,Bremse_MK60EC,Bremse_MK70MABS,Bremse_TRW_EBC450M,Bremse_TRW_ESP,Daempfer,EPB_TRW,EPB_TRW_VW411CS,ESP_AU316,LH_EPS_APA,LH_EPS_ZF_2G,LH_EPS_ZF_3G,LWS,Magne_Ride
 SG_ IDT_VIN_17 : 56|8@1+ (1,0) [0|255] "" Airbag,AppGW_SK,Bremse_ESP_EPB_EBC460Vi,Bremse_MK100_ESC,Bremse_MK60EC,Bremse_MK70MABS,Bremse_TRW_EBC450M,Bremse_TRW_ESP,Daempfer,EPB_TRW,EPB_TRW_VW411CS,ESP_AU316,LH_EPS_APA,LH_EPS_ZF_2G,LH_EPS_ZF_3G,LWS,Magne_Ride
 SG_ IDT_Geheimnis_1 : 8|8@1+ (1,0) [0|255] "" XXX
 SG_ IDT_VIN_4 : 8|8@1+ (1,0) [0|255] "" Airbag,AppGW_SK,Daempfer,LWS,Magne_Ride
 SG_ IDT_VIN_11 : 8|8@1+ (1,0) [0|255] "" Airbag,AppGW_SK,Daempfer,LWS,Magne_Ride
 SG_ IDT_Geheimnis_2 : 16|8@1+ (1,0) [0|255] "" XXX
 SG_ IDT_VIN_5 : 16|8@1+ (1,0) [0|255] "" Airbag,AppGW_SK,Daempfer,LWS,Magne_Ride
 SG_ IDT_VIN_12 : 16|8@1+ (1,0) [0|255] "" Airbag,AppGW_SK,Daempfer,LWS,Magne_Ride
 SG_ IDT_Geheimnis_3 : 24|8@1+ (1,0) [0|255] "" XXX
 SG_ IDT_VIN_6 : 24|8@1+ (1,0) [0|255] "" Airbag,AppGW_SK,Daempfer,LWS,Magne_Ride
 SG_ IDT_Geheimnis_4 : 32|8@1+ (1,0) [0|255] "" XXX
 SG_ IDT_VIN_1 : 40|8@1+ (1,0) [0|255] "" Airbag,AppGW_SK,Daempfer,LWS,Magne_Ride
 SG_ IDT_VIN_2 : 48|8@1+ (1,0) [0|255] "" Airbag,AppGW_SK,Daempfer,LWS,Magne_Ride
 SG_ IDT_VIN_9 : 48|8@1+ (1,0) [0|255] "" Airbag,AppGW_SK,Daempfer,LWS,Magne_Ride
 SG_ IDT_VIN_3 : 56|8@1+ (1,0) [0|255] "" Airbag,AppGW_SK,Daempfer,LWS,Magne_Ride
 SG_ IDT_VIN_10 : 56|8@1+ (1,0) [0|255] "" Airbag,AppGW_SK,Daempfer,LWS,Magne_Ride
 SG_ IDT_VIN_7 : 32|8@1+ (1,0) [0|255] "" Airbag,AppGW_SK,Bremse_ESP_EPB_EBC460Vi,Bremse_MK100_ESC,Bremse_MK60EC,Bremse_TRW_EBC450M,Daempfer,EPB_TRW,EPB_TRW_VW411CS,ESP_AU316,LWS,Magne_Ride
 SG_ IDT_VIN_8 : 40|8@1+ (1,0) [0|255] "" Airbag,AppGW_SK,Bremse_ESP_EPB_EBC460Vi,Bremse_MK100_ESC,Bremse_MK60EC,Bremse_TRW_EBC450M,Daempfer,EPB_TRW,EPB_TRW_VW411CS,ESP_AU316,LWS,Magne_Ride

BO_ 1056 mKombi_2: 8 XXX
 SG_ KO2_gef_Auss_T : 8|8@1+ (0.5,-50) [-50|77] "Unit_DegreCelsi" AFS,BMS_Hybrid,Bremse_ESP_AU714,Bremse_ESP_EPB_EBC460Vi,Bremse_MK100_ESC,Bremse_MK60EC,Bremse_TRW_EBC450M,Bremse_TRW_ESP,EPB_TRW_VW411CS,ESP_AU316,Getriebe_DL800_R8,Getriebe_DQ,Getriebe_DQ_Hyb,Getriebe_Sele,HCA,LWR,Magne_Ride,Motor_Hybrid,Motor_Otto,PDC_PLA,RKA_Plus
 SG_ KO2_Verb_TOG : 1|1@1+ (1,0) [0|1] "" Motor_Diesel,Motor_Hybrid,Motor_Otto
 SG_ KO2_Oelwarn : 2|1@1+ (1,0) [0|1] "" XXX
 SG_ KO2_GRA_High : 3|1@1+ (1,0) [0|1] "" Motor_Diesel,Motor_Otto
 SG_ KO2_Temp_Einheit : 4|1@1+ (1,0) [0|1] "" XXX
 SG_ KO2_Wischwasser : 5|1@1+ (1,0) [0|1] "" XXX
 SG_ KO2_PLA_Displaystatus : 6|1@1+ (1,0) [0|1] "" PDC_PLA
 SG_ KO2_Fehlereintr : 7|1@1+ (1,0) [0|1] "" XXX
 SG_ KO2_Aussen_T : 16|8@1+ (0.5,-50) [-50|77] "Unit_DegreCelsi" BMS_Hybrid,Bremse_MK60EC,Bremse_MK70MABS,Magne_Ride,Motor_Diesel,Motor_Otto,PDC_PLA
 SG_ KBI_Anzeigestatus_LIM : 24|2@1+ (1,0) [0|3] "" Motor_Diesel,Motor_Otto
 SG_ KO_AWV_Zustandswechsel : 26|1@1+ (1,0) [0|1] "" XXX
 SG_ KO_AWV_Vorw_Zustandswechsel : 27|1@1+ (1,0) [0|1] "" XXX
 SG_ KO_Aussensound_Zustandswechsel : 33|1@1+ (1,0) [0|1] "" XXX
 SG_ KB2_EasyEntry : 34|1@1+ (1,0) [0|1] "" XXX
 SG_ KO_Segeln_Menuestatus : 36|1@1+ (1,0) [0|1] "" Getriebe_AG6,Getriebe_DL800_R8,Getriebe_DQ
 SG_ KO_Segeln_Zustandswechsel : 37|1@1+ (1,0) [0|1] "" Getriebe_AG6,Getriebe_DL800_R8,Getriebe_DQ
 SG_ KB2_Auto_eKiSi : 38|1@1+ (1,0) [0|1] "" XXX
 SG_ KO2_Bel_Displ : 40|7@1+ (1,0) [0|100] "Unit_PerCent" Airbag,Daempfer,FLA,Magne_Ride,PDC_PLA,Waehlhebel_Sele
 SG_ KO2_Sta_Displ : 47|1@1+ (1,0) [0|1] "" Airbag,Daempfer,Magne_Ride,PDC_PLA,Waehlhebel_Sele
 SG_ KO2_Bel_Schalt : 48|7@1+ (1,0) [0|100] "Unit_PerCent" XXX
 SG_ KO2_Sta_Schalt : 55|1@1+ (1,0) [0|1] "" XXX
 SG_ KO2_MFA_v_Einheit : 56|1@1+ (1,0) [0|1] "" Motor_Diesel,Motor_Hybrid,Motor_Otto
 SG_ KO2_Passiv_Autolock : 57|1@1+ (1,0) [0|1] "" XXX
 SG_ KO2_WFS_Schl_Ort : 58|1@1+ (1,0) [0|1] "" XXX
 SG_ KB2_MFA_Strecke_Einheit : 59|1@1+ (1,0) [0|1] "" XXX
 SG_ KO2_OBD_Nib_Temp : 60|4@1+ (1,0) [0|15] "" BMS_Hybrid,Motor_Diesel,Motor_Hybrid,Motor_Otto
 SG_ KO2_Sta_Auss_T : 0|1@1+ (1,0) [0|1] "" Bremse_ESP_AU714,Bremse_ESP_EPB_EBC460Vi,Bremse_MK100_ESC,Bremse_MK60EC,Bremse_MK70MABS,EPB_TRW_VW411CS,HCA,Magne_Ride,Motor_Diesel,Motor_Hybrid,Motor_Otto,RKA_Plus
 SG_ KBI_rotes_P_verbaut : 35|1@1+ (1,0) [0|1] "" Bremse_ESP_EPB_EBC460Vi,Bremse_TRW_EBC450M,EPB_TRW_VW411CS
 SG_ KB2_Req_IstZu_Solldruecke : 39|1@1+ (1,0) [0|1] "" Bremse_ESP_EPB_EBC460Vi,Bremse_MK100_ESC,Bremse_MK60EC,Bremse_TRW_EBC450M,RKA_Plus

BO_ 1312 mKombi_3: 8 XXX
 SG_ KO3_Radumfang : 0|12@1+ (1,0) [0|4095] "" Allrad,AppGW_SK,Bremse_ESP_AU714,Bremse_ESP_EPB_EBC460Vi,Bremse_MK100_ESC,Bremse_MK60EC,Bremse_MK70MABS,Bremse_TRW_EBC450M,Bremse_TRW_ESP,ESP_AU316,Getriebe_DL800_R8,Getriebe_DQ,Getriebe_DQ_Hyb,Motor_Diesel,Motor_Hybrid,Motor_Otto,PDC_PLA
 SG_ KO3_Land : 8|6@1+ (1,0) [0|7] "" Bremse_ESP_EPB_EBC460Vi,Bremse_TRW_EBC450M,Bremse_TRW_ESP,ESP_AU316
 SG_ KO3_Mp_Code : 14|2@1+ (1,0) [0|3] "" Airbag,Allrad,AppGW_SK,Bremse_ESP_AU714,Bremse_ESP_EPB_EBC460Vi,Bremse_MK100_ESC,Bremse_MK60EC,Bremse_MK70MABS,Bremse_TRW_EBC450M,Bremse_TRW_ESP,ESP_AU316,Getriebe_DL800_R8,Getriebe_DQ,Getriebe_DQ_Hyb,Motor_Diesel,Motor_Hybrid,Motor_Otto,PDC_PLA
 SG_ KO3_Um_AutoHold : 22|1@1+ (1,0) [0|1] "" Bremse_ESP_EPB_EBC460Vi,Bremse_TRW_EBC450M,Bremse_TRW_ESP
 SG_ KO3_Standzeit : 24|15@1+ (4,0) [0|131068] "Unit_Secon" AFS,Allrad,Bremse_ESP_AU714,Bremse_ESP_EPB_EBC460Vi,Bremse_MK100_ESC,Bremse_MK60EC,Bremse_TRW_EBC450M,Bremse_TRW_ESP,ESP_AU316,Getriebe_DL800_R8,Getriebe_DQ,Getriebe_DQ_Hyb,Magne_Ride,Motor_Diesel,Motor_Hybrid,Motor_Otto
 SG_ KO3_Sprache : 0|8@1+ (1,0) [0|39] "" XXX
 SG_ KO3_Derivat : 0|4@1+ (1,0) [0|9] "" Allrad,Bremse_MK60EC
 SG_ KO3_Verbau_Mot : 0|1@1+ (1,0) [0|1] "" XXX
 SG_ KO3_Verbau_Get : 1|1@1+ (1,0) [0|1] "" XXX
 SG_ KO3_Verbau_Br : 2|1@1+ (1,0) [0|1] "" Bremse_MK100_ESC,Bremse_MK60EC
 SG_ KO3_Verbau_Kl : 3|1@1+ (1,0) [0|1] "" XXX
 SG_ KO3_Generation : 4|4@1+ (1,0) [0|15] "" Allrad,Bremse_MK60EC
 SG_ KO3_Verbau_Air : 4|1@1+ (1,0) [0|1] "" Airbag
 SG_ KO3_Verbau_ADR : 5|1@1+ (1,0) [0|1] "" XXX
 SG_ KO3_Verbau_BN : 6|1@1+ (1,0) [0|1] "" XXX
 SG_ KO3_Verbau_Syn : 7|1@1+ (1,0) [0|1] "" XXX
 SG_ KO3_Baureihe : 8|3@1+ (1,0) [0|7] "" Allrad,Bremse_MK60EC
 SG_ KO3_Verbau_LWS : 8|1@1+ (1,0) [0|1] "" XXX
 SG_ KO3_Verbau_DP : 9|1@1+ (1,0) [0|1] "" XXX
 SG_ KO3_Verbau_LH : 10|1@1+ (1,0) [0|1] "" XXX
 SG_ KO3_Marke : 11|3@1+ (1,0) [0|7] "" Allrad,Bremse_ESP_AU714,Bremse_MK100_ESC,Bremse_MK60EC
 SG_ KO3_Verbau_Niveau : 11|1@1+ (1,0) [0|1] "" XXX
 SG_ KBI_Oelwechsel_durchgefuehrt : 13|1@1+ (1,0) [0|1] "" Motor_Otto
 SG_ KO3_Schluessel : 16|4@1+ (1,0) [0|0] "" XXX
 SG_ KO3_Um_AFS2 : 20|1@1+ (1,0) [0|1] "" AFS
 SG_ KO3_Um_Tourist : 21|1@1+ (1,0) [0|1] "" AFS,LWR
 SG_ KO3_SWA_AnzFeh : 23|1@1+ (1,0) [0|1] "" XXX
 SG_ KO3_Sta_Standz : 39|1@1+ (1,0) [0|1] "" AFS,Bremse_ESP_AU714,Bremse_MK100_ESC,Bremse_MK60EC,Getriebe_DL800_R8,Getriebe_DQ,Getriebe_DQ_Hyb,Magne_Ride,Motor_Diesel,Motor_Hybrid,Motor_Otto
 SG_ KO3_Kilometer : 40|20@1+ (1,0) [0|1048575] "Unit_KiloMeter" AppGW_SK,Bremse_MK60EC,Bremse_MK70MABS,Getriebe_AG6,LH_EPS_ZF_2G,LH_EPS_ZF_3G

BO_ 978 mLenkhilfe_2: 7 XXX
 SG_ LH2_Checksumme : 0|8@1+ (1,0) [0|255] "" Bremse_ESP_EPB_EBC460Vi,Bremse_MK100_ESC,Bremse_MK60EC,Bremse_TRW_EBC450M,Bremse_TRW_ESP,Gateway_PQ35,HCA,PDC_PLA
 SG_ LH2_Zaehler : 8|4@1+ (1,0) [0|15] "" Bremse_ESP_EPB_EBC460Vi,Bremse_MK100_ESC,Bremse_MK60EC,Bremse_TRW_EBC450M,Bremse_TRW_ESP,Gateway_PQ35,HCA,PDC_PLA
 SG_ LH2_StatEPS_PLA : 28|4@1+ (1,0) [0|15] "" Bremse_ESP_EPB_EBC460Vi,Bremse_MK100_ESC,Bremse_MK60EC,Bremse_TRW_EBC450M,Bremse_TRW_ESP,Gateway_PQ35,PDC_PLA
 SG_ LH2_Geradeaus : 12|1@1+ (1,0) [0|1] "" Gateway_PQ35,LWS,Magne_Ride
 SG_ LH2_Sta_Charisma : 13|3@1+ (1,0) [0|3] "" Gateway_PQ35
 SG_ LH2_Sta_HCA : 16|4@1+ (1,0) [0|7] "" Gateway_PQ35,HCA
 SG_ LH2_Ausg_LW1 : 20|1@1+ (1,0) [0|1] "" Gateway_PQ35
 SG_ LH2_Ausg_LW1_gue : 21|1@1+ (1,0) [0|1] "" Gateway_PQ35
 SG_ LH2_aktLenkeingriff : 32|8@1+ (1,0) [0|64] "" Gateway_PQ35,PDC_PLA
 SG_ LH2_PLA_Err : 48|4@1+ (1,0) [0|15] "" Gateway_PQ35,PDC_PLA
 SG_ LH2_PLA_Abbr : 52|4@1+ (1,0) [0|15] "" Gateway_PQ35,PDC_PLA

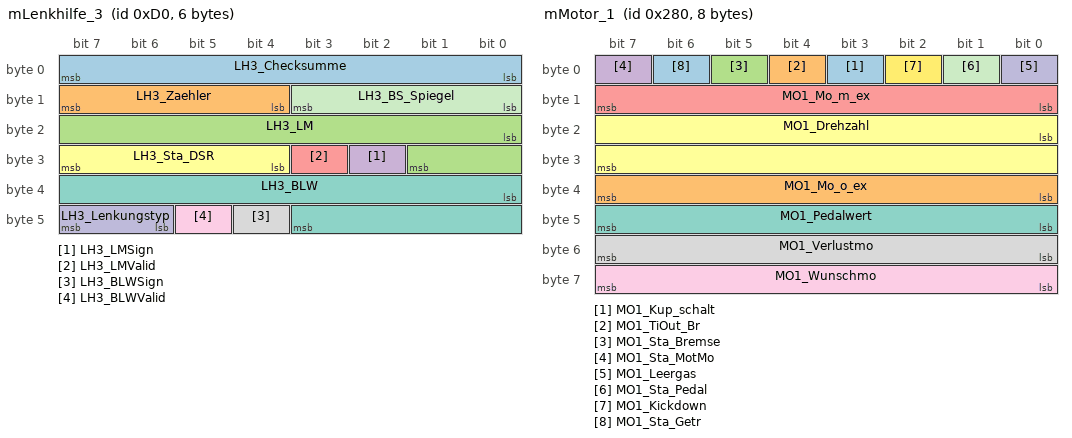
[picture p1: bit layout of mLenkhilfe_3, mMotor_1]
BO_ 208 mLenkhilfe_3: 6 XXX
 SG_ LH3_Checksumme : 0|8@1+ (1,0) [0|255] "" Bremse_ESP_EPB_EBC460Vi,Bremse_MK100_ESC,Bremse_MK60EC,Bremse_MK70MABS,Bremse_TRW_EBC450M,Bremse_TRW_ESP,ESP_AU316,Gateway_PQ35,HCA,PDC_PLA
 SG_ LH3_Zaehler : 12|4@1+ (1,0) [0|15] "" Bremse_ESP_EPB_EBC460Vi,Bremse_MK100_ESC,Bremse_MK60EC,Bremse_MK70MABS,Bremse_TRW_EBC450M,Bremse_TRW_ESP,ESP_AU316,Gateway_PQ35,HCA,PDC_PLA
 SG_ LH3_LM : 16|10@1+ (0.0147,0) [0|15.0381] "Unit_NewtoMeter" Bremse_ESP_EPB_EBC460Vi,Bremse_MK100_ESC,Bremse_MK60EC,Bremse_MK70MABS,Bremse_TRW_EBC450M,Bremse_TRW_ESP,ESP_AU316,Gateway_PQ35,HCA,Motor_Diesel,Motor_Otto,PDC_PLA
 SG_ LH3_LMSign : 26|1@1+ (1,0) [0|1] "" Bremse_ESP_EPB_EBC460Vi,Bremse_MK100_ESC,Bremse_MK60EC,Bremse_MK70MABS,Bremse_TRW_EBC450M,Bremse_TRW_ESP,ESP_AU316,Gateway_PQ35,HCA,Motor_Diesel,Motor_Otto,PDC_PLA
 SG_ LH3_LMValid : 27|1@1+ (1,0) [0|1] "" Bremse_ESP_EPB_EBC460Vi,Bremse_MK100_ESC,Bremse_MK60EC,Bremse_MK70MABS,Bremse_TRW_EBC450M,Bremse_TRW_ESP,ESP_AU316,Gateway_PQ35,HCA,Motor_Diesel,Motor_Otto,PDC_PLA
 SG_ LH3_Sta_DSR : 28|4@1+ (1,0) [0|7] "" Bremse_ESP_EPB_EBC460Vi,Bremse_MK100_ESC,Bremse_MK60EC,Bremse_MK70MABS,Bremse_TRW_EBC450M,Bremse_TRW_ESP,ESP_AU316,Gateway_PQ35
 SG_ LH3_BLW : 32|12@1+ (0.15,0) [0|614.25] "Unit_DegreOfArc" Bremse_ESP_EPB_EBC460Vi,Bremse_MK100_ESC,Bremse_MK60EC,Bremse_MK70MABS,Bremse_TRW_EBC450M,Bremse_TRW_ESP,ESP_AU316,Gateway_PQ35,HCA,PDC_PLA
 SG_ LH3_BLWSign : 44|1@1+ (1,0) [0|1] "" Bremse_ESP_EPB_EBC460Vi,Bremse_MK100_ESC,Bremse_MK60EC,Bremse_MK70MABS,Bremse_TRW_EBC450M,Bremse_TRW_ESP,ESP_AU316,Gateway_PQ35,HCA,PDC_PLA
 SG_ LH3_BLWValid : 45|1@1+ (1,0) [0|1] "" Bremse_ESP_EPB_EBC460Vi,Bremse_MK100_ESC,Bremse_MK60EC,Bremse_MK70MABS,Bremse_TRW_EBC450M,Bremse_TRW_ESP,ESP_AU316,Gateway_PQ35,HCA,PDC_PLA
 SG_ LH3_Lenkungstyp : 46|2@1+ (1,0) [0|3] "" Bremse_ESP_EPB_EBC460Vi,Bremse_MK100_ESC,Bremse_MK60EC,Bremse_MK70MABS,Bremse_TRW_EBC450M,Bremse_TRW_ESP,ESP_AU316,Gateway_PQ35,HCA,PDC_PLA
 SG_ LH3_BS_Spiegel : 8|4@1+ (1,0) [0|15] "" Bremse_MK100_ESC,Gateway_PQ35

BO_ 640 mMotor_1: 8 XXX
 SG_ MO1_Kup_schalt : 3|1@1+ (1,0) [0|1] "" Allrad,Bremse_ESP_AU714,Bremse_ESP_EPB_EBC460Vi,Bremse_MK100_ESC,Bremse_MK60EC,Bremse_MK70MABS,Bremse_TRW_EBC450M,Bremse_TRW_ESP,ESP_AU316,Gateway_PQ35,PDC_PLA,RKA_Plus
 SG_ MO1_TiOut_Br : 4|1@1+ (1,0) [0|1] "" Bremse_ESP_AU714,Bremse_ESP_EPB_EBC460Vi,Bremse_MK60EC,Bremse_TRW_EBC450M,Bremse_TRW_ESP,ESP_AU316,Gateway_PQ35
 SG_ MO1_Sta_Bremse : 5|1@1+ (1,0) [0|1] "" Bremse_ESP_EPB_EBC460Vi,Bremse_MK100_ESC,Bremse_MK60EC,Bremse_MK70MABS,Bremse_TRW_EBC450M,Bremse_TRW_ESP,EPB_TRW,ESP_AU316,Gateway_PQ35
 SG_ MO1_Sta_MotMo : 7|1@1+ (1,0) [0|1] "" Bremse_ESP_AU714,Bremse_ESP_EPB_EBC460Vi,Bremse_MK100_ESC,Bremse_MK60EC,Bremse_MK70MABS,Bremse_TRW_EBC450M,Bremse_TRW_ESP,ESP_AU316,Gateway_PQ35,Getriebe_AG6,Getriebe_DL800_R8,Getriebe_DQ,Getriebe_DQ_Hyb,Getriebe_Sele,RKA_Plus
 SG_ MO1_Mo_m_ex : 8|8@1+ (0.39,0) [0|99.06] "Unit_PerCent" Allrad,Bremse_ESP_AU714,Bremse_ESP_EPB_EBC460Vi,Bremse_MK100_ESC,Bremse_MK60EC,Bremse_MK70MABS,Bremse_TRW_EBC450M,Bremse_TRW_ESP,EPB_TRW_VW411CS,ESP_AU316,Gateway_PQ35,Getriebe_AG6,Getriebe_DL800_R8,Getriebe_DL800_ZSG_R8,Getriebe_DQ,Getriebe_DQ_Hyb,Getriebe_Sele,Magne_Ride,RKA_Plus,SAK
 SG_ MO1_Drehzahl : 16|16@1+ (0.25,0) [0|16256] "Unit_MinutInver" AFS,Airbag,Allrad,Bremse_ESP_AU714,Bremse_ESP_EPB_EBC460Vi,Bremse_MK100_ESC,Bremse_MK60EC,Bremse_MK70MABS,Bremse_TRW_EBC450M,Bremse_TRW_ESP,EPB_TRW,EPB_TRW_VW411CS,ESP_AU316,Gateway_PQ35,Getriebe_AG6,Getriebe_DL800_R8,Getriebe_DL800_ZSG_R8,Getriebe_DQ,Getriebe_DQ_Hyb,Getriebe_Sele,HCA,LEH_Hybrid,LH_EPS_APA,LH_EPS_ZF_2G,LH_EPS_ZF_3G,LWR,Magne_Ride,PDC_PLA,RKA_Plus,SAK
 SG_ MO1_Pedalwert : 40|8@1+ (0.4,0) [0|101.6] "Unit_PerCent" AFS,Allrad,AppGW_SK,Bremse_ESP_AU714,Bremse_ESP_EPB_EBC460Vi,Bremse_MK100_ESC,Bremse_MK60EC,Bremse_MK70MABS,Bremse_TRW_EBC450M,Bremse_TRW_ESP,ESP_AU316,Gateway_PQ35,Getriebe_AG6,Getriebe_DL800_R8,Getriebe_DL800_ZSG_R8,Getriebe_DQ,Getriebe_DQ_Hyb,Getriebe_Sele,LH_EPS_APA,LH_EPS_ZF_2G,LH_EPS_ZF_3G,LWR
 SG_ MO1_Verlustmo : 48|8@1+ (0.39,0) [0|99.06] "Unit_PerCent" Allrad,Bremse_ESP_AU714,Bremse_ESP_EPB_EBC460Vi,Bremse_MK100_ESC,Bremse_MK60EC,Bremse_MK70MABS,Bremse_TRW_EBC450M,Bremse_TRW_ESP,EPB_TRW,EPB_TRW_VW411CS,ESP_AU316,Gateway_PQ35,Getriebe_AG6,Getriebe_DL800_R8,Getriebe_DQ,Getriebe_DQ_Hyb,Getriebe_Sele,Magne_Ride,RKA_Plus,SAK
 SG_ MO1_Wunschmo : 56|8@1+ (0.39,0) [0|99.06] "Unit_PerCent" Allrad,Bremse_ESP_AU714,Bremse_ESP_EPB_EBC460Vi,Bremse_MK100_ESC,Bremse_MK60EC,Bremse_MK70MABS,Bremse_TRW_EBC450M,Bremse_TRW_ESP,Daempfer,ESP_AU316,Gateway_PQ35,Getriebe_AG6,Getriebe_DL800_R8,Getriebe_DQ,Getriebe_DQ_Hyb,Getriebe_Sele,Magne_Ride
 SG_ MO1_Leergas : 0|1@1+ (1,0) [0|1] "" Bremse_ESP_AU714,Bremse_MK100_ESC,Bremse_MK60EC,Bremse_MK70MABS,Gateway_PQ35,Getriebe_AG6,Getriebe_DL800_R8,Getriebe_DQ,Getriebe_DQ_Hyb
 SG_ MO1_Sta_Pedal : 1|1@1+ (1,0) [0|1] "" Bremse_ESP_AU714,Bremse_MK100_ESC,Bremse_MK60EC,Bremse_MK70MABS,Gateway_PQ35,Getriebe_AG6,LH_EPS_APA
 SG_ MO1_Kickdown : 2|1@1+ (1,0) [0|1] "" Gateway_PQ35,Getriebe_AG6,Getriebe_DL800_R8,Getriebe_DQ,Getriebe_DQ_Hyb,Getriebe_Sele
 SG_ MO1_Sta_Getr : 6|1@1+ (1,0) [0|1] "" Gateway_PQ35,Getriebe_AG6,Getriebe_DL800_R8,Getriebe_DQ,Getriebe_DQ_Hyb
 SG_ MO1_Mo_o_ex : 32|8@1+ (0.39,0) [0|99.06] "Unit_PerCent" Bremse_ESP_AU714,Bremse_MK100_ESC,Bremse_MK60EC,Bremse_MK70MABS,Gateway_PQ35,Getriebe_AG6,Getriebe_DL800_R8,Getriebe_DQ,Getriebe_DQ_Hyb

BO_ 648 mMotor_2: 8 XXX
 SG_ MO2_Getr_Code : 0|6@1+ (1,0) [0|17] "" Bremse_ESP_AU714,Bremse_ESP_EPB_EBC460Vi,Bremse_MK100_ESC,Bremse_MK60EC,Bremse_MK70MABS,Bremse_TRW_EBC450M,Bremse_TRW_ESP,EPB_TRW,EPB_TRW_VW411CS,ESP_AU316,Gateway_PQ35,Getriebe_AG6,Getriebe_DL800_R8,Getriebe_DQ,Getriebe_DQ_Hyb,Getriebe_Sele,RKA_Plus
 SG_ MO2_max_Mo : 0|6@1+ (10,0) [0|630] "Unit_NewtoMeter" Allrad,Bremse_ESP_AU714,Bremse_ESP_EPB_EBC460Vi,Bremse_MK100_ESC,Bremse_MK60EC,Bremse_TRW_EBC450M,Bremse_TRW_ESP,EPB_TRW,EPB_TRW_VW411CS,ESP_AU316,Gateway_PQ35,Getriebe_AG6,Getriebe_DL800_R8,Getriebe_DQ,Getriebe_DQ_Hyb,Getriebe_Sele,RKA_Plus
 SG_ MO2_Mp_Code : 6|2@1+ (1,0) [0|3] "" Allrad,Bremse_ESP_AU714,Bremse_ESP_EPB_EBC460Vi,Bremse_MK100_ESC,Bremse_MK60EC,Bremse_MK70MABS,Bremse_TRW_EBC450M,Bremse_TRW_ESP,EPB_TRW,EPB_TRW_VW411CS,ESP_AU316,Gateway_PQ35,Getriebe_AG6,Getriebe_DL800_R8,Getriebe_DQ,Getriebe_DQ_Hyb,Getriebe_Sele,RKA_Plus,SAK
 SG_ MO2_BLS : 16|1@1+ (1,0) [0|1] "" Airbag,Allrad,AppGW_SK,Bremse_ESP_AU714,Bremse_ESP_EPB_EBC460Vi,Bremse_TRW_EBC450M,Bremse_TRW_ESP,Daempfer,EPB_TRW,EPB_TRW_VW411CS,ESP_AU316,Gateway_PQ35,Getriebe_AG6,Getriebe_DL800_R8,Getriebe_DQ,Getriebe_DQ_Hyb,Getriebe_Sele,Magne_Ride,PDC_PLA
 SG_ MO2_Sta_No_Bet : 20|1@1+ (1,0) [0|1] "" Allrad,Bremse_ESP_AU714,Bremse_ESP_EPB_EBC460Vi,Bremse_MK100_ESC,Bremse_MK60EC,Bremse_MK70MABS,Bremse_TRW_EBC450M,Bremse_TRW_ESP,ESP_AU316,Gateway_PQ35,Getriebe_AG6,Getriebe_DL800_R8,Getriebe_DL800_ZSG_R8,Getriebe_DQ,Getriebe_DQ_Hyb
 SG_ MO2_Sta_GRA : 22|2@1+ (1,0) [0|3] "" Bremse_ESP_EPB_EBC460Vi,Bremse_MK100_ESC,Bremse_MK60EC,Bremse_TRW_EBC450M,Bremse_TRW_ESP,ESP_AU316,Gateway_PQ35,Getriebe_AG6,Getriebe_DL800_R8,Getriebe_DQ,Getriebe_DQ_Hyb,Getriebe_Sele,RKA_Plus
 SG_ MO2_OffRoad : 28|1@1+ (1,0) [0|1] "" Bremse_ESP_EPB_EBC460Vi,Bremse_MK100_ESC,Bremse_TRW_EBC450M,Bremse_TRW_ESP,ESP_AU316,Gateway_PQ35,Getriebe_AG6,Getriebe_DL800_R8,Getriebe_DQ,Getriebe_DQ_Hyb
 SG_ MO2_LL_Solldz : 40|8@1+ (10,0) [0|2540] "Unit_MinutInver" Bremse_ESP_EPB_EBC460Vi,Bremse_MK100_ESC,Bremse_TRW_EBC450M,Bremse_TRW_ESP,ESP_AU316,Gateway_PQ35,Getriebe_AG6,Getriebe_DL800_R8,Getriebe_DQ,Getriebe_DQ_Hyb,Getriebe_Sele
 SG_ MO2_CAN_Vers : 0|6@1+ (1,0) [17|54] "" Gateway_PQ35,Getriebe_DL800_R8,Getriebe_DQ,Getriebe_DQ_Hyb,Getriebe_Sele
 SG_ MO2_Kuehlm_T : 8|8@1+ (0.75,-48) [-47.25|142.5] "Unit_DegreCelsi" Gateway_PQ35,Getriebe_AG6,Getriebe_DL800_R8,Getriebe_DQ,Getriebe_DQ_Hyb,Getriebe_Sele,LEH_Hybrid,Magne_Ride,RKA_Plus
 SG_ MO2_BTS : 17|1@1+ (1,0) [0|1] "" Airbag,Allrad,Bremse_ESP_AU714,Bremse_MK100_ESC,Gateway_PQ35,Getriebe_AG6,Getriebe_DL800_R8,Getriebe_DQ,Getriebe_DQ_Hyb,Getriebe_Sele,Magne_Ride,PDC_PLA
 SG_ MO2_Sta_Kuehlm : 18|1@1+ (1,0) [0|1] "" Gateway_PQ35,Getriebe_AG6,Getriebe_DL800_R8,Getriebe_DQ,Getriebe_DQ_Hyb,LEH_Hybrid
 SG_ MO2_Sta_Klima : 19|1@1+ (1,0) [0|1] "" Gateway_PQ35,Getriebe_AG6,Getriebe_DL800_R8,Getriebe_DQ,Getriebe_DQ_Hyb
 SG_ MO2_Status_TSK : 21|1@1+ (1,0) [0|1] "" Gateway_PQ35,Getriebe_DL800_R8,Getriebe_DQ
 SG_ TSK_Limiter_ausgewaehlt : 25|1@1+ (1,0) [0|1] "" Gateway_PQ35
 SG_ MO2_GRAregelt : 26|1@1+ (1,0) [0|1] "" Gateway_PQ35,Getriebe_DL800_R8,Getriebe_DQ,Getriebe_DQ_Hyb
 SG_ MO2_Sport_Error : 27|1@1+ (1,0) [0|1] "" Gateway_PQ35
 SG_ MO2_RME_Gehalt : 29|3@1+ (12.5,0) [0|75] "Unit_PerCent" Gateway_PQ35
 SG_ MO2_GRA_Soll : 32|8@1+ (1.28,0) [0|325.12] "Unit_KiloMeterPerHour" Gateway_PQ35,Getriebe_AG6,Getriebe_DL800_R8,Getriebe_DQ,Getriebe_DQ_Hyb
 SG_ MO2_Begr_Mo : 48|8@1+ (0.39,0) [0|99.06] "Unit_PerCent" Gateway_PQ35,Getriebe_AG6,Getriebe_DL800_R8,Getriebe_DQ,Getriebe_DQ_Hyb
 SG_ MO2_Mo_ZWR : 56|8@1+ (0.39,0) [0|99.06] "Unit_PerCent" Bremse_ESP_AU714,Gateway_PQ35,Getriebe_DL800_R8,Getriebe_DQ,Getriebe_DQ_Hyb
 SG_ MO2_Motor_Code : 0|6@1+ (1,0) [0|63] "" Bremse_ESP_EPB_EBC460Vi,Bremse_MK100_ESC,Bremse_MK60EC,Bremse_MK70MABS,EPB_TRW,EPB_TRW_VW411CS,ESP_AU316,Gateway_PQ35,Getriebe_DL800_R8,Getriebe_DQ,Getriebe_DQ_Hyb,Getriebe_Sele,SAK

BO_ 896 mMotor_3: 8 XXX
 SG_ MO3_Pedalwert : 16|8@1+ (0.4,0) [0|101.6] "Unit_PerCent" Airbag,Bremse_ESP_EPB_EBC460Vi,Bremse_MK100_ESC,Bremse_MK60EC,Bremse_TRW_EBC450M,Bremse_TRW_ESP,EPB_TRW,EPB_TRW_VW411CS,ESP_AU316,Gateway_PQ35,Getriebe_AG6,Getriebe_DL800_R8,Getriebe_DQ,Getriebe_DQ_Hyb,HCA,Magne_Ride,PDC_PLA
 SG_ MO3_Vorgluehen : 0|1@1+ (1,0) [0|1] "" Gateway_PQ35,Getriebe_DL800_R8,Getriebe_DQ,Getriebe_DQ_Hyb
 SG_ MO3_Prio_Dz : 1|1@1+ (1,0) [0|1] "" Gateway_PQ35,Getriebe_AG6,Getriebe_DL800_R8,Getriebe_DQ,Getriebe_DQ_Hyb
 SG_ MO_Schalter_StartStopp : 2|1@1+ (1,0) [0|1] "" Gateway_PQ35,Getriebe_DL800_R8,Getriebe_DQ,Getriebe_DQ_Hyb
 SG_ MO3_Winterprg : 3|1@1+ (1,0) [0|1] "" Gateway_PQ35,Getriebe_DL800_R8,Getriebe_DQ,Getriebe_DQ_Hyb
 SG_ MO3_Sta_FPG : 5|1@1+ (1,0) [0|1] "" Bremse_MK100_ESC,Bremse_MK60EC,Gateway_PQ35
 SG_ MO3_Sign_FPG : 6|1@1+ (1,0) [0|1] "" Bremse_MK100_ESC,Bremse_MK60EC,Gateway_PQ35
 SG_ MO3_Sta_Temp : 7|1@1+ (1,0) [0|1] "" Gateway_PQ35,Getriebe_DL800_R8,Getriebe_DQ,Getriebe_DQ_Hyb
 SG_ MO3_Aussentemp : 8|8@1+ (0.75,-48) [-48|142.5] "Unit_DegreCelsi" Gateway_PQ35,Getriebe_AG6,Getriebe_DL800_R8,Getriebe_DQ,Getriebe_DQ_Hyb,Magne_Ride
 SG_ MO3_Rad_Wu_Mo : 24|12@1+ (0.39,0) [0|1596.66] "Unit_PerCent" Gateway_PQ35,Getriebe_AG6,Getriebe_DL800_R8
 SG_ MO3_Vorz_RadWu : 36|1@1+ (1,0) [0|1] "" Gateway_PQ35,Getriebe_AG6,Getriebe_DL800_R8
 SG_ MO3_Freigabe_Segeln : 37|1@1+ (1,0) [0|1] "" Gateway_PQ35,Getriebe_AG6,Getriebe_DL800_R8,Getriebe_DQ,Getriebe_DQ_Hyb
 SG_ MO_StartStopp_StoppVorbereitung : 38|1@1+ (1,0) [0|1] "" Gateway_PQ35,Getriebe_DQ
 SG_ MO3_Dz_Beeinfl : 40|8@1+ (0.39,0) [0|99.45] "Unit_PerCent" Gateway_PQ35
 SG_ MO3_WunschDz : 48|8@1+ (25,0) [0|6350] "Unit_MinutInver" Gateway_PQ35,Getriebe_AG6,Getriebe_DL800_R8,Getriebe_DQ,Getriebe_DQ_Hyb
 SG_ MO3_DKW : 56|8@1+ (0.4,0) [0|101.6] "Unit_PerCent" Gateway_PQ35
 SG_ MO3_FPGradient : 56|8@1+ (25,0) [0|6350] "Unit_PerCentPerSecon" Bremse_MK100_ESC,Bremse_MK60EC,Gateway_PQ35
 SG_ MO3_Sta_Pedal : 4|1@1+ (1,0) [0|1] "" Bremse_ESP_EPB_EBC460Vi,Bremse_MK60EC,EPB_TRW,EPB_TRW_VW411CS,ESP_AU316,Gateway_PQ35,Getriebe_DL800_R8,Getriebe_DQ,Getriebe_DQ_Hyb

CM_ SG_ 1494 PLS_Bremsleuchte "Bei einer durch PLA initiierten Bremsung des Fahrzeugs muss Bremsleuchte angesteuert werden. Dieses Signal ist der Befehl, die Bremsleuchte einzuschalten, an dasjenige Steuergeraet, das sie schaltet.";
CM_ SG_ 1494 PLS_Anf_Anz "Anforderung der Anzeige entsprechender Symbolik gem. HMI-Spezifikation im Kombiinstrument in Abhaengigkeit des Signals \"Parkluecke links/rechts\", nachdem die PLA-Funktion ueber Tastendruck aktiviert wurde. | Alle weiteren Signale des Bytes 1 werden nur zur Anzeige gebracht, wenn dieses Signal gesetzt ist.";
CM_ SG_ 1494 PLS_Akustik1 "Ausgabe bei Funktionsdeaktivierung oder Systemstoerung";
CM_ SG_ 1494 PLS_PL_Exist "Anzeige entsprechender Symbolik gem. HMI-Spezifikation im Kombiinstrument";
CM_ SG_ 1494 PLS_Akustik2 "Nur Audi: Das Signal dient der akustischen Signalisierung von PLA-Fehlerinformationen";
CM_ SG_ 1494 PLS_Mehrzg_Aktiv "Anzeige der Bedienbildschirme 'Mehrzuegiges Einparken' | Mehrzuegiges Einparken aktiv";
CM_ SG_ 1494 PLS_Pos_OK "Anzeige der Parklueckeninformationen gemaess HMI-Spezifikation. | Position Egofahrzeug";
CM_ SG_ 1494 PLS_PL_Seite "Anzeige der Parklueckeninformationen gemaess HMI-Spezifikation. | Parkluecke links/rechts";
CM_ SG_ 1494 PLS_Lenk_Aktiv_Hinweis "Anzeige des Symbols, das fuer Aktiv-Lenkung verwendet wird. Das Signal steuert den Anzeigebildschirm fuer den Hinweis und liegt nicht waehrend des gesammten aktiven automatischen Lenkeigriffs an.";
CM_ SG_ 1494 PLS_Meldungen "Anzeige gemaess HMI-Spezifikation | Meldungen PLA. Textmeldung ist abhaengig vom Text-Multiplexer-Bit.";
CM_ SG_ 1494 PLS_Fahrtrichtg_Mehrzg "In Kombination mit Bit \"Mehrzuegiges Einparken aktiv\" und Bit \"Parkluecke links/rechts\" | Auswahl des Bildschirms | Fahrtrichtung mehrzuegig";
CM_ SG_ 1494 PLS_Text_Multiplexer "Dient als Multiplexer-Bit fuer zusaetzliche Textmeldungen gemaess HMI-Spezifikation (PLS_Meldungen). | | Anmerkung: Jeder Anzeigewunsch eines Piktogramms oder einer Meldung ist mit diesem Bit verknuepft. Bei Wert gleich 0 ist keine Anzeige einer Textmeldung moeglich. | | Alter Signalname: PLS_Anzeige_Prio";
CM_ SG_ 1494 PLS_Schwellpfeil_rel "Anzeige eines Schwellpfeils waehrend Vorwaerts- oder Rueckwaertsfahrt in einer Parkluecke, der den relativen Abstand in gewuenschter Richtung bis zum tatsaechlichen Wendepunkt anzeigt. Der Pfeil laeuft bis zur Aufforderung zum Fahrtrichtungswechsel leer.";
CM_ SG_ 1494 PLS_Anf_Anz_Schwellpfeil "Schalter, mit dem die Anzeige eines Schwellpfeiles ein- bzw. ausgeschaltet wird.";
CM_ SG_ 1494 PLS_Laengs_Querluecke "Anzeige gemaess Auswahl der Parkfunktion fuer Laengs- oder Querparkluecke.";
CM_ SG_ 1494 PLS_Standby "Anzeige des Symbols, das fuer Standby-Anzeige verwendet wird. Standby-Zustand zeigt an, dass die Fzg.-Geschwindigkeit zu hoch zum Vermessen von Parkluecken ist, das System sich bei Unterschreiten einer Geschwindigkeitsschwelle wieder selbstaendig zur Anzeige bringt. Signal wird ist in Verbindung mit PLS_PL_Seite und PLS_Laengs_Querluecke auszuwerten.";
CM_ SG_ 1494 PLS_Bremssymbol "Dient der Anzeige zur Aufforderung, das Bremspedal getreten zu halten, solange im Stillstand die Raeder eingelenkt werden.";
CM_ SG_ 1494 PLS_Kurze_Luecke "Schalter, mit dem eine kurze Luecke erkannt wird, damit die Anzeige eines Schwellpfeiles ein- bzw. ausgeschaltet wird.";
CM_ SG_ 1494 PLS_Schwellpfeil_abs "Anzeige eines Schwellpfeils waehrend Vorwaerts- oder Rueckwaertsfahrt in einer Parkluecke, der den absoluten Abstand in gewuenschter Richtung bis zum tatsaechlichen Wendepunkt anzeigt. (Pfeil laeuft leer).";
CM_ SG_ 1494 PLS_Akustik "Dient der akustischen Signalisierung von PLA-Funktionsdeaktivierungen oder Funktionsstoerungen";
CM_ SG_ 1494 PLS_Ausparken_Aktiv "Vorhalt fuer moegliche Unterscheidungen in der Anzeige. Kennzeichnet einen aktiven Ausparkvorgang und dient der Anzeige geeigneter Informationen im Kombiinstrument, die sich von der Anzeige waehrende des Einparkvorganges unterscheiden.";
CM_ SG_ 1494 PLS_Texte "Anzeige gemaess HMI-Spezifikation | Nur Audi: neue Texte ersetzen Textmultiplexer und Meldungen";
CM_ SG_ 1500 VL1_Motor_SG "immer 1! (Motorsteuergeraet immer verbaut)";
CM_ SG_ 1500 VL1_Getr_SG "Sollverbau Getriebesteuergeraet";
CM_ SG_ 1500 VL1_LSM "Sollverbau Lenkwinkel";
CM_ SG_ 1500 VL1_Airbag "Airbag-Steuergeraet im CAN-Antrieb-Netzwerk | Anmerkungen: Bit auf 0 heisst nicht verbaut (Sollzustand) | Initwert 'const' bedeutet, dass der kodierte Zustand gesendet wird";
CM_ SG_ 1500 VL1_Allrad "Sollverbau Allrad";
CM_ SG_ 1500 VL1_ADR "Sollverbau ADR-Steuergeraet";
CM_ SG_ 1500 VL1_Anhaenger "Sollverbau Anhaengermodul";
CM_ SG_ 1500 VL1_ABS "Sollverbau ABS fuer Schlechtweginformation";
CM_ SG_ 1500 VL1_Kombi "1 = Kombi am Antriebs-CAN verbaut";
CM_ SG_ 1500 VL1_Lenkhilfe "Lenkhilfe (Elektrohydraulische Servolenkung) im CAN-Antrieb-Netzwerk | Anmerkungen: Bit auf 0 heisst nicht verbaut (Sollzustand) | Initwert 'alt' bedeutet, dass der letzte erkannte Zustand gesendet wird (ggfs. 0 nach Klemme 30 Reset) | Clima_VW: Zur Unterscheidung von Lenkhilfe und hydraulischer Lenkung im VN357 zur Ansteuerung eines ext. geregelten Kompressors bei verbauter Lenkhilfe u. int. geregeltem Kompressor durch Climatic/Climatronic bei hydraulischer Lenkung.";
CM_ SG_ 1500 VL1_dyn_LWR "Dynamische Leuchtweitenregulierung / AFS";
CM_ SG_ 1500 VL1_res_08 "Niveauregulierung am CAN Antrieb";
CM_ SG_ 1500 VL1_ADR_getrennt "ADR-Sensor kann vom CAN-Antrieb abgetrennt werden: | aktueller Zustand dieses Relais wird uebertragen | T5 GP mit Rekuperation / Start-Stopp: Bei einmal erkanntem Bus Off wird das Bit gesetzt u. nach 5 Sek stabilem Bus wieder zurueckgesetzt. | Initwert 0: Hardware ohne Abtrennmoeglichkeit (z. Zt. PQ35, VW47x) | Initwert 1: Hardware mit bestueckbarer Abtrennmoeglichkeit (z. Zt. alle PQ46)";
CM_ SG_ 1500 VL1_EPB "Parkbremse am CAN-Antrieb, bzw. Bremsen-SUB-CAN";
CM_ SG_ 1500 VL1_res_13 "EZS Steuergeraet";
CM_ SG_ 1500 VL1_Daempfer "Daempfer-SG am CAN Antrieb";
CM_ SG_ 1500 VL1_Quersperre "Quersperre im CAN-Antrieb-Netzwerk";
CM_ SG_ 1500 VL1_MotorSlave "Motor Slave im CAN-Antrieb-Netzwerk";
CM_ SG_ 1500 VL1_SWA "SWA Spurwechselassistent oder Heckradar-Entry";
CM_ SG_ 1500 VL1_HCA "LDW / Heading Control am Antriebs-CAN oder Kamera am Extended-CAN verbaut";
CM_ SG_ 1500 VL1_RKA_Plus "RKA-SG (RKA_Plus) am CAN Antrieb | oder RKA-Plus-Funktion (Senden der CAN-ID 0x443 durch die Bremse!) im Bremsen-SG umgesetzt.";
CM_ SG_ 1500 VL1_PLA "PDC / Park Lenk Assistent am Antiebsstrang";
CM_ SG_ 1500 VL1_WFS_KBI "1 = Wegfahrsperre am Kombi-CAN oder Antriebs-CAN";
CM_ SG_ 1500 VL1_Kombi_KBI "1 = Kombi am Kombi-CAN verbaut";
CM_ SG_ 1500 VL1_Soll_eq_Ist "1 = Sollverbau = Istverbau | 0 = Sollverbau ungleich Istverbau";
CM_ SG_ 1500 VL1_BSG_Komf "Sollverbau BSG_Komfort bzw. ILM_Komfort";
CM_ SG_ 1500 VL1_ZKE "Sollverbau ZKE";
CM_ SG_ 1500 VL1_TSG_FT "Sollverbau TSG_FT";
CM_ SG_ 1500 VL1_TSG_BT "Sollverbau TSG_BT";
CM_ SG_ 1500 VL1_TSG_HL "Sollverbau TSG_HL, in der PQ25/T5GP elektrische Schiebetuer HL";
CM_ SG_ 1500 VL1_TSG_HR "Sollverbau TSG_HR, in der PQ25/T5GP elektrische Schiebetuer HR";
CM_ SG_ 1500 VL1_Memory "Sollverbau Memory";
CM_ SG_ 1500 VL1_Dachmodul_K "Reserviert fuer Dachmodul / Dachdisplay im CAN-Komfort-Netzwerk | Anmerkungen: Bit auf 0 heisst nicht verbaut (Sollzustand) | Initwert 'const' bedeutet, dass der kodierte Zustand gesendet wird";
CM_ SG_ 1500 VL1_Zentralelektrik_II "Sollverbau Zentralelektrik 2 am CAN-Komfort";
CM_ SG_ 1500 VL1_RDK "Sollverbau Reifendruck";
CM_ SG_ 1500 VL1_Lenksaeule "Sollverbau Lenksaeulenmodul/Multifunktionslenkrad";
CM_ SG_ 1500 VL1_Gateway "Sollverbau Gatewaymodul am CAN-Komfort";
CM_ SG_ 1500 VL1_Clima_Komf "Sollverbau Climasteuerung am CAN-Komfort";
CM_ SG_ 1500 VL1_Einparkhilfe "Sollverbau Einparkhilfe";
CM_ SG_ 1500 VL1_PTC_Heizung "1 = PTC-Heizung verbaut";
CM_ SG_ 1500 VL1_Standheiz "Sollverbau, Standheizung am Komfort oder Infotainment";
CM_ SG_ 1500 VL1_Verdeck "Sollverbau Verdecksteuergeraet";
CM_ SG_ 1500 VL1_RSE_I "Sollverbau Rearseatentertainment";
CM_ SG_ 1500 VL1_res_42 "Reserviert fuer Wischermodul im CAN-Komfort / CAN-Infotainment-Netzwerk | Anmerkungen: Bit auf 0 heisst nicht verbaut (Sollzustand) | Initwert 'const' bedeutet, dass der kodierte Zustand gesendet wird";
CM_ SG_ 1500 VL1_MDI_I "Sollverbau Mobil Device Interface";
CM_ SG_ 1500 VL1_Memory_BF "Sollverbau Sitzmemory_BF";
CM_ SG_ 1500 VL1_Easy_Entry_VF "Sollverbau Easy Entry Fahrer";
CM_ SG_ 1500 VL1_Easy_Entry_VB "Easy Entry Beifahrer";
CM_ SG_ 1500 VL1_Heckdeckel "Verbau des Heckdeckel-Steuergeraetes";
CM_ SG_ 1500 VL1_Rearview "Sollverbau, Rearview am Infotainment";
CM_ SG_ 1500 VL1_Sonderfzg_SG "Sonderfahrzeug-SG";
CM_ SG_ 1500 VL1_Tastenmodul "Sollverbau 10-er Tastatur am CAN-Infotainment";
CM_ SG_ 1500 VL1_Kompass "Sollverbau Kompass am CAN-Infotainment";
CM_ SG_ 1500 VL1_WFS_K "1 = Wegfahrsperre am CAN-Komfort verbaut";
CM_ SG_ 1500 VL1_GSM_Pager "Sollverbau GSM-Pager am CAN-Infotainment";
CM_ SG_ 1500 VL1_InfoElektronik "Sollverbau Informationselektronik";
CM_ SG_ 1500 VL1_DSP "Sollverbau DSP am CAN-Infotainment";
CM_ SG_ 1500 VL1_DAB "Sollverbau auch fuer SDARS Tuner";
CM_ SG_ 1500 VL1_Telematik "Sollverbau Telematik am CAN-Infotainment";
CM_ SG_ 1500 VL1_Navigation "Sollverbau; Fuer RNS werden die BITs Radio und Navigation gesetzt (Logische Komponenten) | Navigation am CAN-Infotainment";
CM_ SG_ 1500 VL1_TV_Tuner "Sollverbau TV_Tuner am CAN-Infotainment";
CM_ SG_ 1500 VL1_Neigungsmodul_I "Sollverbau Neigungsmodul am CAN-Infotainment";
CM_ SG_ 1500 VL1_Radio "Sollverbau; Fuer RNS werden die BITs Radio und Navigation gesetzt (Logische Komponenten) | Radio am CAN-Infotainment";
CM_ SG_ 1500 VL1_Telefon "Sollverbau Telefon am CAN-Infotainment";
CM_ SG_ 1936 TPDyn_ABS_1 "ABS | TP 2.0 Empfangskanal 1 fuer ABS_SG";
CM_ SG_ 512 Tester_TP_Er "Transportkanaleroeffnung vom Tester zu allen Steuergeraeten mit CAN-Diagnose; TP 2.0 | TP 2.0 Eroeffnungskanal";
CM_ SG_ 80 AB1_Front "Bit wird bei Ueberschreitung der Gurtstraffer, US-Schwelle und RDW-Schwelle gesetzt | Front-Crash";
CM_ SG_ 80 AB1_Heck "wird fuer neu anlaufende Projekte umgesetzt: AB8.4, Audi8/VW8 | Heck-Crash";
CM_ SG_ 80 AB1_Fa_Seite "z. Zt. Nur in Verbindung mit Crash-Intensitaet 100b (Kraftstoffpumpenabsch.) verwendet | Seiten-Crash Fahrer";
CM_ SG_ 80 AB1_Bf_Seite "z. Zt. Nur in Verbindung mit Crash-Intensitaet 100b (Kraftstoffpumpenabsch.) verwendet | Seiten-Crash Beifahrer";
CM_ SG_ 80 AB1_Rollover "wird im B6 Cabrio und New Beetle Cabrio, Touareg GP und VW465 bedient | Rollover";
CM_ SG_ 80 AB1_Gurt_Fa "ueber Schalter im Gurtschloss | Gurtschlossabfrage Fahrer";
CM_ SG_ 80 AB1_Zaehler "ueberlaufender Botschaftszaehler zur Lebenderkennung";
CM_ SG_ 80 AB1_Checksumme "Pruefsumme mit Endwert 0x0, Definition im CAN Lastenheft (HS-CAN V4.2a, LS-CAN V1.42)";
CM_ SG_ 80 AB1_Intens "Die folgende Auswertung ist bei VW geplant: ; >= 001: ZV auf, Innenlicht u. Warnblinker ein ; >= 010: Notruf ausgeloest ; >= 100: Kraftstoffabschaltung (mit RDW-Schwelle aktiviert, d.h.Bit 7 = 1); ; Information bleibt bei jeder Schwellwert-ueberschreitung fuer ca. 10 sec bestehen;(Achtung: Energiereserve bei abgetrennter Batterie reicht worstcase nur fuer 150 msec);Anmerkung: Bosch gibt bei Ueberschreitung der RDW-Schwelle 111b aus | Crash-Intensitaet (Airbag 1)";
CM_ SG_ 80 AB1_Lampe "Sicherheitswarnlampe im Kombi wird vom Airbag-SG angesteuert; Zustand der Lampe wird auf dem CAN-Bus ausgegeben (auch Blinkinformation) | Airbag-Lampe";
CM_ SG_ 80 AB1_Status "Airbag oder Gurtstraffer wurden per Anpassung deaktiviert: Aktualisierung erst nach Selbsttest | Airbag deaktiviert";
CM_ SG_ 80 AB1_Beifahrer "Als Option vorgehalten, Beifahrerairbag wurden per Schluesselschalter oder Insassenerkennung deaktiviert | Beifahrerairbag deaktiviert";
CM_ SG_ 80 AB1_System "Warnlampe (Byte 2, Bit 0) wird dauernd angeschaltet | Airbag-Systemfehler";
CM_ SG_ 80 AB1_Gurt_Bf "ueber Schalter im Gurtschloss | Gurtschlossabfrage Beifahrer";
CM_ SG_ 80 AB1_Diagnose "Bei Diagnose ueber UDS nicht mehr bedient | Airbag in Diagnose";
CM_ SG_ 80 AB1_Stellglied "zur Unterdrueckung einer Notrufausloesung | Airbag im Stellgliedtest";
CM_ SG_ 80 AB1_BF_Warnung "im Kombi wird eine Gurtwarnung fuer den Beifahrer ausgeloest (z. B. Beifahrersitz belegt, Gurt nicht angelegt) | Gurtwarnung Beifahrer";
CM_ SG_ 80 AB1_Fehlereintr "Bei gesetztem Bit ist mindestens ein Kundendienstfehler eingetragen";
CM_ SG_ 704 AL1_Fehler "Systemfehler (Sammelmeldung fuer alle statischen Fehlerzustaende) | Fehler Allrad-Kupplung";
CM_ SG_ 704 AL1_Uebertemp "Kupplung wegen Uebertemperatur geoeffnet (Elektronikschutz) | Uebertemperaturschutz (Allrad 1)";
CM_ SG_ 704 AL1_Sta_Kup "Vorgabe des ABS-Steuergeraetes ist zur Zeit nicht ausfuehrbar, weil ein Fehler vorliegt oder die aktuelle Vorgabe nicht moeglich ist:;wird gesetzt, wenn Kupplung fehlerhaft nicht oeffnet (nur dann) oder Bremse 4-Botschaft nicht empfangen wird | Fehlerstatus Kupplungssteifigkeit";
CM_ SG_ 704 AL1_Kup_offen "Ventil ist vollstaendig geoeffnet | Kupplung komplett offen";
CM_ SG_ 704 AL1_Notlauf "Bit wird gesetzt, wenn Irgendein Problem erkannt wurde (auch Time Out-Fehler) | Notlauf";
CM_ SG_ 704 AL1_Warnlampe "Vorhalt fuer zukuenftige Projekte (auch fuer PNG);RPU: Als Kontroll-Symbol Laengssperre genutzt | Allrad-Warnlampe";
CM_ SG_ 704 AL1_Einheit "Kupplungsmoment in Byte 2 erhaelt eine andere Einheit | Hinweis: Statischer (konstanter) Wert abhaengig vom Fahrzeugprojekt! | Einheit des Kupplungs-Wertes";
CM_ SG_ 704 AL1_Ist_Nm "Ist-Moment berechnet aus der Drucksensorinformation; 'Kupplung schnell offen` heisst, dass der Befehl vom Bremsen-Steuergeraet ausgefuehrt wird (d.h. Sollzustand, kein Istwert !), ; der Arbeitsbereich geht von 0 (=80H) Nm (Kupplung gesteuert offen) bis 882 (=FEH) Nm (gant geschlossen); ; negativer Wertebereich praktisch nicht moeglich;ACHTUNG im T5GP noch alte Aufloesung: aus der Radgeschwindigkeitsdifferenz Vorder- zu Hinterachse, der Ventilspannung und der Temperatur errechneter Wert; 'Kupplung schnell offen` heisst, dass der Befehl vom Bremsen-Steuergeraet ausgefuehrt wird (d.h. Sollzustand, kein Istwert !), ; der Arbeitsbereich geht von 0 (=80H) Nm/min-1 (Kupplung gesteuert offen) bis 378 (=FEH) Nm/min-1 (z.Zt. praktisch bei Haldex bis 220 Nm/min-1); ; negativer Wertebereich praktisch nicht moeglich | Kupplungsmoment (Ist-Wert)";
CM_ SG_ 704 AL1_Ist_Proz "nur wenn Einheit der Kupplungssteifigkeit in Prozente | Kupplungssteifigkeit Mitte (Ist-Wert)";
CM_ SG_ 704 AL1_Zaehler "Botschaftszaehler, Definition im CAN-Lastenheft";
CM_ SG_ 704 AL1_Limiter "Begrenzung der Fahrzeuggeschwindigkeit durch das Motor-SG (Wert muss im MSG appliziert sein). ; Grund kann z.B. verringerte Fahrzeugstabilitaet bei Gelaendeuntersetzung sein (nicht PQ35/46) | Geschwindigkeitsbegrenzung";
CM_ SG_ 704 AL1_Sta_PNG "Als Info fuer andere Systeme (ADR, 4CL, ...) ob die Gelaendeuntersetzung aktiv ist. | PNG-Status";
CM_ SG_ 704 AL1_Anz_blinken "Vorhalt fuer PNG;RPU: Laengssperren-Symbole blinken | PNG-Anzeige blinkend";
CM_ SG_ 704 AL1_Sta_Laengssp "Gibt den Status der Laengssperre fuer andere Systeme an (z.B. ESP, ACC,..) | Laengssperren Status";
CM_ SG_ 704 AL1_Sta_Quersp "Gibt den Status der Hinterachs-Quersperre fuer andere Systeme an (z.B. ESP, ACC,..) | Hinterachs Status";
CM_ SG_ 704 AL1_Schalten "Aktion wird ausgefuehrt (nicht bei Audi) | Schaltung aktiv (Allrad 1)";
CM_ SG_ 704 AL1_Vorwarnung "Schaltung wird demnaechst eingeleitet; Bit bleibt bis zum Ende der Schaltung gesetzt (nicht bei Audi) | Schaltung Vorwarnung";
CM_ SG_ 704 AL1_Stellung_Getr "Neutralinformation wird vom Verteilergetriebe eingelesen | Schaltung Neutralstellung";
CM_ SG_ 704 AL1_AnfVerteiler "Im PQ35/46 mit 0 belegt, wenn in Byte 5 die Kupplungstemperatur gesendet wird.;Wenn dieses Bit gesetzt ist, soll das Motormoment auf den im Byte 5 gesendeten Wert reduziert werden. | Verteiler-Anforderung";
CM_ SG_ 704 AL1_Sta_VA "Gibt den Status der Vorderachs-Quersperre fuer andere Systeme an (z.B. ESP, ACC,..);(zur Zeit nur Vorhalt) | Vorderachs Status";
CM_ SG_ 704 AL1_KupSteifig_F "Zusatzinfo, falls im Byte 2 der Fehlerwert FFhex gesendet wird (nur bei Colorado) | Kupplungssteifigkeit im Fehlerzustand";
CM_ SG_ 704 AL1_Fehlereintr "Bei gesetztem Bit ist mindestens ein Kundendienstfehler eingetragen";
CM_ SG_ 704 AL1_KupplTemp "Sensorwert Kupplungsoeltemperatur (AL1_KupplTemp): Der Wert ist gueltig, wenn das Bit 'Verteiler-Anforderung' (Byte 4, Bit 3) mit 0 belegt ist. (Haldex) | | Doppelte Signalbelegung in Altprojekten (VW756): | Verteiler Begrenzungsmoment (AL1_Begrenzungsmo): Der Wert ist gueltig, wenn das Bit 'Verteiler-Anforderung' (Byte 4, Bit 3) mit 1 belegt ist: Zum Schutz des VA-Getriebes gibt dieser Wert das max. zulaessige Motormoment vor. Diese Momentenvorgabe soll analog zum Motoreingriff durch ESP oder Getriebe in die Min-Auswertung der Motorsteuerung einfliessen. | Aufloesung 0,39; Wertebereich 0 bis 99,06 %MDI (Rohwert 1 bis 254); 0xFE = Init; 0xFF = Fehler";
CM_ SG_ 704 AL1_FaWu_Laengs "Waehrend im Laengssperren Status (Byte 3) der tatsaechliche Sperrenzustand angegeben wird, werden diese Bits gesetzt, sobald der Fahrwerksschalter entsprechend bedient wird. | Fahrerwunsch Laengssperre";
CM_ SG_ 704 AL1_FaWu_HA "Waehrend im Hinterachs Status (Byte 3) der tatsaechliche Sperrenzustand angegeben wird, werden diese Bits gesetzt, sobald der Fahrwerksschalter entsprechend bedient wird. | Fahrerwunsch Hinterachssperre";
CM_ SG_ 704 AL1_FaWu_VA "Waehrend im Vorderachs Status (Byte 4) der tatsaechliche Sperrenzustand angegeben wird, werden diese Bits gesetzt, sobald der Fahrwerksschalter entsprechend bedient wird. | Fahrerwunsch Vorderachssperre";
CM_ SG_ 704 AL1_Quersp_Sta "Quersperre nur im Haldex T5 an Allrad angeschlossen (Init im T5/PQ35/PQ46: 3) | Quersperren-Status";
CM_ SG_ 704 AL1_Limit_maxkmh "Hoechstgeschwindigkeitsbegrenzung im Motorsteuergeraet, aktiviert durch Bit 6 in Byte 1;(Signalbeschreibung muss nachgereicht werden) | Zulaessige Geschwindigkeit bei Begrenzung";
CM_ SG_ 704 AL1_Diff_Verbau "Nur im T5: Differentialsperre ist an Allrad-SG angeschlossen (Init im T5/PQ35/PQ46: 1) | Differentialsperre verbaut";
CM_ SG_ 704 AL1_Diff_Lampe "Nur im T5 (Init im T5/PQ35/PQ46: 1) | Differentialsperren-Lampe";
CM_ SG_ 704 AL1_Diff_Gong "Bei v > 45 km/h wird Gong angesteuert, wenn Differentialsperre eingelegt ist | Differentialsperren-Gong";
CM_ SG_ 704 AL1_Warnton "Warnton Laengssperre im RPU | 0 = kein Warnton | 1 = Warnton (Summer 2 bzw. Gong1000 als Dauerton)";
CM_ SG_ 870 AWV_Checksumme "Pruefsumme mit Endwert 0x0, Definition im CAN Lastenheft (HS-CAN V4.2a, LS-CAN V1.42)";
CM_ SG_ 870 AWV_Zaehler "Freilaufender Botschaftszaehler";
CM_ SG_ 870 AWV_1_Freigabe "Das Freigabebit muss gesetzt sein, um die Anforderungen 'Prefill' oder 'adaptiver HBA' freizugeben. (HBA = hydraulischer Bremsassistent)";
CM_ SG_ 870 AWV_1_Prefill "Anforderung an ESP, dass Prefill-Funktion aktiviert werden soll. | (PQ46 mit mAWV ID 0x366: Umsetzung der Prefill-Anforderung im ESP nur in Verbindung mit gesetztem Bit 'AWV1_Freigabe')";
CM_ SG_ 870 AWV_1_Parameter "Anforderung an ESP, welcher HBA-Parametersatz verwendet werden soll. (Die Festlegung der Empfindlichkeitsschwellen der verschiedenen Parametersaetze erfolgt mit der Applikation des Gesamtsystems ESP/ACC bzw. des HBA.) | (PQ46 mit mAWV ID 0x366: Umsetzung der Anforderung im ESP nur in Verbindung mit gesetztem Bit 'AWV1_Freigabe')";
CM_ SG_ 870 AWV_2_Freigabe "Freigabe eines Ruckes - Auswertung des 'AWV2 Ruckprofil' bzw. Abbruch eines aktiven Bremsrucks";
CM_ SG_ 870 AWV_2_Ruckprofil "Anforderung an ESP / Boostersteuergeraet, welcher Ruck verwendet werden soll. Die Festlegung der Parameter der verschiedenen Ruckprofile erfolgt mit der Applikation des Gesamtsystems ESP/Boostersteuergeraet/ACC. Die Umsetzung der Anforderung im ESP/Boostersteuergeraet erfolgt nur mit gesetztem Bit 'AWV2 Freigabe'.";
CM_ SG_ 870 AWV_Text "Anforderung an das Kombiinstrument, den ausgewaehlten Text anzuzeigen | 0000 kein Text | 0001 \"Front Assist aus\" | 0010 \"Front Assist startet\" | 0011 \"Front Assist nicht verfuegbar\" bis 22/11 -> ab 22/11 \"Front Assist Warnung\" | 0100 \"Front Assist Sensor reinigen\" | 0101 \"Front Assist Fehler\" | 0110 \"Front Assist Warnung\" bis 22/11 -> ab 22/11 \"Front Assist Demo\" | 0111 Vorhalt | 1000 - 1101 CV-Sensor-Texte";
CM_ SG_ 870 AWV_CityANB_Auspraegung "Plausibilisierung der Codierung der CityANB-Auspraegung im ESP.";
CM_ SG_ 870 AWV_2_Status "Ansteuerung der Statusanzeige (gruene Lampe) im Kombiinstrument";
CM_ SG_ 870 AWV_2_Fehler "Ansteuerung der Fehleranzeige (gelbe Lampe) im Kombiinstrument";
CM_ SG_ 870 AWV_2_SU_Warnzeit "Eingestellter Warnzeitpunkt | (Empfang nur, wenn kein BAP umgesetzt) | AWV2 Setup Warnzeitpunkt";
CM_ SG_ 870 AWV_2_SU_Bremsruck "Einstellung, ob der Fahrer einen Bremsruck erlaubt | (Empfang nur, wenn kein BAP umgesetzt) | AWV2 Setup Bremsruck";
CM_ SG_ 870 AWV_2_SU_Gong "Einstellung, ob der Fahrer eine akustische Warnung erlaubt | (Empfang nur, wenn kein BAP umgesetzt) | AWV2 Setup Gong";
CM_ SG_ 870 AWV_2_SU_Lampe "Einstellung, ob der Fahrer eine optische Warnung erlaubt | (Empfang nur, wenn kein BAP umgesetzt) | AWV2 Setup Lampe";
CM_ SG_ 870 AWV_2_Umfeldwarn "Anforderung fuer eine Warnung des Umfeldes / anderer Verkehrsteilnehmer (z. B. Warnblinken) bei extremen Fahrmanoevern";
CM_ SG_ 870 AWV_2_Warnton "Anforderung an das Kombiinstrument eine akustische Fahrerwarnung (Summer) durchzufuehren";
CM_ SG_ 870 AWV_2_Warnsymbol "Anforderung an das Kombiinstrument eine optische Fahrerwarnung mit hoher Prioritaet (rote Lampe/Pictogramm) im Mitteldisplay durchzufuehren | Empfaenger: Kombi";
CM_ SG_ 870 AWV_Infoton "Anforderung an das Kombiinstrument, die Anzeige des ausgwaehlten Textes (AWV Textindex) mit einer Akustik zu koppeln";
CM_ SG_ 870 AWV_2_Gurtstraffer "Anforderung an den reversiblen Gurtstraffer, den Gurt zu straffen (z.B. Warnaktuator, Precrash) | Geplante Empfaenger: rev. Gurtstraffer";
CM_ SG_ 870 AWV_Konfiguration_Menueanf "Aktivierung/Deaktivierung Kombi-Menue AWV (zur Darstellung im Low-Line Kombi ohne BAP)";
CM_ SG_ 870 AWV_Konfiguration_Vorw_Menueanf "Aktivierung/Deaktivierung Kombi-Menue AWV Vorwarnung (zur Darstellung im Low-Line Kombi ohne BAP)";
CM_ SG_ 870 AWV_Konfiguration_Status "AWV inaktiv/aktiv (zur Darstellung im Low-Line Kombi ohne BAP)";
CM_ SG_ 870 AWV_Konfiguration_Vorw_Status "AWV Vorwarnung inaktiv/aktiv (zur Darstellung im Low-Line Kombi ohne BAP)";
CM_ SG_ 870 AWV_2_Abstandswarnung "Ansteuerung der Abstandswarnung im Kombiinstrument";
CM_ SG_ 870 AWV_only "Signal zur Unterscheidung der freigeschalteten Kundenfunktion";
CM_ SG_ 870 AWV_Halten "Anforderung an das ESP, das Fahrzeug nach erfolgter automatischer Bremsung bis in den Stillstand im Stillstand zu halten und eine Fahrer-Ueberwachung zu aktivieren.";
CM_ SG_ 870 ANB_Teilbremsung_Freigabe "Freigabe-Bit der Teilbremsung an das ESP";
CM_ SG_ 870 ANB_Zielbremsung_Freigabe "Freigabe-Bit der Zielbremsung an das ESP";
CM_ SG_ 870 ANB_CM_Anforderung "ANB_CM-Anforderungsbit an das ESP | Geplanter Empfaenger: ESP";
CM_ SG_ 870 ANB_Ziel_Teilbrems_Verz_Anf "Verzoegerungsanforderung der Funktionen Zielbremsung und Teibremsung an das ESP";
CM_ SG_ 1392 BSL_ZAS_Kl_15 "1 = Klemme 15 Innenraum ist eingeschaltet";
CM_ SG_ 1392 BSL_BSG_3_alt "mBSG_3 Botschaft nicht empfangen (400 msec) | Das integrierte Gateway (BCM) sendet dauerhaft \"0\", da es ggf. fuer die genannten Signale Originalsender ist! | | Zykluszeit der Quellbotschaft [ms]: 200 | | Veraltet Bit fuer die Signale: | | Botschaft mBSG_Last: | Byte 1, Bit 0 BSL_ZAS_Kl_S | Byte 1, Bit 1 BSL_ZAS_Kl_15 | Byte 1, Bit 2 BSL_ZAS_Kl_X | Byte 1, Bit 3 BSL_ZAS_Kl_50 | Byte 1, Bit 4 BSL_Parklicht | Byte 1, Bit 5 BSL_LL_Anheb2 | Byte 1, Bit 6 BSL_Kl_15_Motor | Byte 1, Bit 7 BSL_Kl_L | Byte 2, Bit 0 BSL_LL_Anheb | Byte 2, Bit 1..2 BSL_Sta_UBat | Byte 2, Bit 3..4 BSL_Sta_StBat | Byte 2, Bit 5 BSL_Fehlereintr | Byte 2, Bit 6 BSL_Sta_LWR | Byte 2, Bit 7 BSL_Motor_Haube | Byte 5, Bit 2 BSL_Kuehlerlueft | Byte 5, Bit 3 BSL_Ab_Batterie | Byte 5, Bit 7 BSL_Starterlaubnis";
CM_ SG_ 1392 BSL_Starterlaubnis "Bit wird gesetzt, wenn der Start vom Bordnetz-SG bei folgenden Begebenheiten erlaubt wird: | - PN-verriegelt, - Interlock (Kupplung bei Handschalter-Fzg.) betaetigt (Kupplungschalter tief) | Als Reaktion auf deises Bit zeigt das Kessy Texte im Kombi an. | Starterlaubnis durch BSG";
CM_ SG_ 1392 BSL_Parklicht "1 = Klemme P ein (Parklicht)";
CM_ SG_ 1392 BSL_LL_Anheb2 "1 = Anforderung der Drehzahlanhebung 2 Stufe | Drehzahlanhebung 2. Stufe (s. BSG_Last)";
CM_ SG_ 1392 BSL_Kl_15_Motor "1 = Klemme 15 Motorraum ist eingeschaltet (Klemme 14)";
CM_ SG_ 1392 BSL_Kl_L "1 = mangelnde Batterieladung | Ladekontrollampe(Klemme L)";
CM_ SG_ 1392 BSL_LL_Anheb "1 = Anforderung der Drehzahlanhebung (bei nur einer Stufe) oder Anhebung auf 1. Stufe (s. Antrieb BSG_Last)";
CM_ SG_ 1392 BSL_Sta_StBat "Zeigt den Zustand der Starterbatterie an (00=i.O., 01=kritisch, 10=entladen, 11=Fehler)";
CM_ SG_ 1392 BSL_Fehlereintr "1 = mindestens ein Fehler ist im Kundendienstfehlerspeicher eingetragen";
CM_ SG_ 1392 BSL_Sta_LWR "1 = Fehler in der Leuchtweitenregulierung | 0 = i.O.";
CM_ SG_ 1392 BSL_Motor_Haube "1 = Haube geoeffnet | 0 = Haube geschlossen";
CM_ SG_ 1392 BSL_Hecksch "1 = Abschalten der Heckscheibenheizung ist gefordert | Heizbare_Heckscheibe abschalten (s. BSG_Last)";
CM_ SG_ 1392 BSL_Frontsch "1 = Abschalten der Frontscheibenheizung ist gefordert | Heizbare_Frontscheibe abschalten (s. BSG_Last)";
CM_ SG_ 1392 BSL_Aussensp "1 = Abschalten der Aussenspiegelheizung ist gefordert | Heizbare_Aussenspiegel abschalten (s. BSG_Last)";
CM_ SG_ 1392 BSL_Sitzheiz "1 = Abschalten der Sitzheizung ist gefordert | Heizbare_Sitze abschalten (s. BSG_Last)";
CM_ SG_ 1392 BSL_Lenkradheiz "1 = Abschalten der Lenkradheizung ist gefordert | Lenkradheizung abschalten (s. BSG_Last)";
CM_ SG_ 1392 BSL_Wasserheiz "1 = Abschalten der Wischwasserheizung ist gefordert | Wischwasserheizung abschalten (s. BSG_Last)";
CM_ SG_ 1392 BSL_Sitzbelueft "1 = Abschalten der Sitzbelueftung ist gefordert";
CM_ SG_ 1392 BSL_Clima "1 = Reduzierung der Klimaleistung ist gefordert | Klimaanlage abschalt. / reduzieren (s. BSG_Last)";
CM_ SG_ 1392 BSL_BSG_2_alt "mBSG_2 Botschaft nicht empfangen (1 Sekunde) | Das integrierte Gateway (BCM) sendet dauerhaft \"0\", da es ggf. fuer die genannten Signale Originalsender ist! | | Zykluszeit der Quellbotschaft [ms]: 500 | | Veraltet Bit fuer die Signale: | | Botschaft mBSG_Last: | Byte 3, Bit 0..7 BSL_UBat | Byte 4, Bit 0 BSL_Hecksch | Byte 4, Bit 1 BSL_Frontsch | Byte 4, Bit 2 BSL_Aussensp | Byte 4, Bit 3 BSL_Sitzheiz | Byte 4, Bit 4 BSL_Lenkradheiz | Byte 4, Bit 5 BSL_Wasserheiz | Byte 4, Bit 6 BSL_Sitzbelueft | Byte 4, Bit 7 BSL_Clima | Byte 5, Bit 4..5 BSL_Weckursache_ACAN | Byte 5, Bit 6 BSL_Wake_Up_ACAN";
CM_ SG_ 1392 BSL_Kuehlerlueft "1 = Kuehlerluefer einschalten zur Glaettung der Bordnetzspannung bei defekter Batterie | Kuehlerluefter einschalten (s. BSG_Last)";
CM_ SG_ 1392 BSL_Ab_Batterie "1 = Batterie ab erkannt | 0 = Batterie am Bordnetz | Batterie ab Erkennung";
CM_ SG_ 1392 BSL_Weckursache_ACAN "00 = keine Weckursache | 01 = Weckursache Tanken (Drucktank) | 10 = Weckursache Standheizung | 11 = Weckursache Tuerkontakt | abhaengig von der genannten Weckursache wird eine Kraftstoffpumpen-Vorfoerderung angesteuert oder beim Hybrid-Drucktank der Tankwunsch dem MSG mitgeteilt. | Wake-Up-Anforderung durch das BSG";
CM_ SG_ 1392 BSL_Wake_Up_ACAN "0 = kein Wake-Up (z.B. KL15-Normalbetrieb) | 1 = Anforderung zum Wecken des Antriebs-CAN | Das BSG lernt anhand von MO7_Mot_weckfaehig, ob es das Bit setzen muss. | Wake-Up des Antriebs-CAN";
CM_ SG_ 1392 BSL_ZAS_Kl_S "1 = S-Kontakt geschlossen, Schluessel steckt | S-Kontakt (Schluessel steckt)";
CM_ SG_ 1392 BSL_ZAS_Kl_X "1 = Klemme X aktiv | Klemme X oeffnet beim Motorstart und ist invers zu Klemme 50. | Bei Fahrzeugen mit Start/Stop-Systemen wird die Klemme X nur beim Erststart ausgeschaltet.";
CM_ SG_ 1392 BSL_ZAS_Kl_50 "1 = Klemme 50 ist eingeschaltet | Klemme 50 geschaltet (Starten)";
CM_ SG_ 1392 BSL_Sta_UBat "Zeigt den Zustand der Bordnetzbatterie an (00=i.O., 01=kritisch, 10=entladen, 11=Fehler)";
CM_ SG_ 1392 BSL_UBat "FF = Fehler | Bordnetz_Batterie_Spannung (s. BSG_Last)";
CM_ SG_ 2000 DI1_VerlernZaehl "FFh = Fehler, ungueltiger Zaehlerstand bzw. kein gueltiger Fahrzyklus | Binaer wrap around";
CM_ SG_ 2000 DI1_km_Stand "Kilometerstand";
CM_ SG_ 2000 DI1_Jahr "0 fuer Datum unbekannt (z.B. keine Funkuhr) | (bei relativem Datum ist auch der Wert 0 gueltig siehe Spezifikation_Tageszaehler_Kombi_01.doc)";
CM_ SG_ 2000 DI1_Monat "0 = Monat unbekannt | Dh = ungueltig | Eh = siehe \"Querschnittslastenheft Diagnosefunktion Relatives Datum\" | Fh = Keine Funkuhrinformation vorhanden und 12 h Anzeige (Monat, Tag, Jahr fehlen)";
CM_ SG_ 2000 DI1_Tag "0 fuer Datum unbekannt (z.B. keine Funkuhr) | (bei relativem Datum ist auch der Wert 0 gueltig siehe Spezifikation_Tageszaehler_Kombi_01.doc)";
CM_ SG_ 2000 DI1_Stunde "18h - 1Fh ungueltig";
CM_ SG_ 2000 DI1_Minute "3Ch - 3Fh ungueltig";
CM_ SG_ 2000 DI1_Sekunde "3Ch - 3Fh ungueltig";
CM_ SG_ 2000 DI1_KM_Stand_alt "0 = Kilometerstand aktuell (vor < als 2 Sec vom Kombi empfangen) | 1 = Kilometerstand veraltet";
CM_ SG_ 2000 DI1_Zeit_alt "0 = Zeit aktuell vom Kombi empfangen (< 2 sec) | 1 = Zeit veraltet";
CM_ SG_ 1088 GE1_Schaltung "Schaltung aktiv (Getriebe 1)";
CM_ SG_ 1088 GE1_Zielgang "Zielgang, wenn Schaltung aktiv | Zielgang oder eingelegter Gang";
CM_ SG_ 1088 GE1_Wahl_Pos "Waehlhebelposition / Fahrprogramm | | Bei Selespeed Bedeutung \"Fahrprogramm\", da keine Waehlhebelgasse vorhanden ist. | Empfaenger erwartet \"P\" wegen Zuendschluesselabzugsperre. Das Selespeed-Getriebe (automatisierter Handschalter) hat den Zustand \"P\" nicht, bedient aber den Wert (08H), wenn sich das Getriebe nach Kl. 15 aus in sicherem Zustand befindet. | | Nur AQ160 : Die Ausgabe des Wertes Zwischenstellung erfolgt um 250ms verzoegert, wenn bis dahin keine regulaere Waehlhebelposition erreicht wurde.";
CM_ SG_ 1088 GE1_Mrad_Mkurb "Mrad / Mkurbelwelle | Uebertragungsfunktion";
CM_ SG_ 1088 GE1_Notlauf "Notlauf: | 0000B kein Notlauf; Gangwechsel=0; Zielgang erreicht=0 | 0001B kein Schalten | 0010B Schalten nach n | 0011B 50% Schalten | 0100B Fahren ohne UeK | 0101B kein Notlauf; Gangwechsel=0; Zielgang erreicht=1 | 0110B kein Notlauf; Gangwechsel=1; Zielgang erreicht=0 | 0111B kein Notlauf; Gangwechsel=1; Zielgang erreicht=1 | 1xxxB reduziertes Anfahrmoment gefordert, Fehler muss im Getriebesteuergeraet abgelegt sein! | 1111B Totalausfall | Kodierung fuer Gangwechsel / Zielgang erreicht ist vorerst speziell fuer ZF-Getriebe eingefuehrt | Porsche Cayenne: Fehler liegt fuer den Sport-Modus vor, wenn Notlauf > 0.";
CM_ SG_ 1088 GE1_Zaehler "Zaehler laeuft synchron mit dem Zaehler in der Getriebe 2 Botschaft (zur Sicherstellung der Synchronitaet) | Botschaftszaehler (Getriebe 1)";
CM_ SG_ 1088 GE1_Sta_Schutz "Umschaltung permanente Leistungsreduzierung (Ein-spritzausblendung) oder Zuendwinkelverstellung (Otto) | | Hybrid: Langsamer Eingriff soll fuer Hybrid implementiert werden. | Status Getriebe und Wandlerschutz";
CM_ SG_ 1088 GE1_Klimakompr "Weiterleiten an Motor, der Klima ausschaltet | Klimakompressor aus (Getriebe 1)";
CM_ SG_ 1088 GE1_WK "auch fuer Anfahrkupplung beim VL30 und Kupplung beim Ecodrive (geregelt bedeutet in diesem Fall die Kupplung ist nicht vollstaendig getrennt bzw hat Schlupf) genutzt; bei starken Verstellwegen wird geoeffnet gesendet (VQ250) | Wandlerkupplung";
CM_ SG_ 1088 GE1_StSt_Info "Stopp-Freigabe/Start-Anforderung fuer den Start-Stopp-Koordinator | (Verriegelt ueber Systemstatus Start/Stopp wegen ESP8 bei AUDI und ggf. alter Motoren: Getriebe darf nur einen Wert ungleich 0 senden, wenn mMotor_10 empfangen wurde und der \"Systemstatus Start Stopp\" ungleich 0 ist.) | [falls Position in mGetriebe_1: | Bit 5 war: \"Leerlaufsolldrehzahl-Anhebung\" (z.B. Erhoehung des Pumpendrucks beim CVT-Getriebe) | Bit 6 war: \"Kodierung im MSG\" (Getriebe-Kodierung im Motor-Steuergeraet ist in Ordnung)] | [falls Position in mGetriebe_6: nur im AU716!]";
CM_ SG_ 1088 GE1_EGS_Anf "Byte 4 wird damit gueltig | EGS-Anforderung";
CM_ SG_ 1088 GE1_Soll_Mo "Getriebeeingriff an den Motor | | Hybrid: Getriebeeingriff auf indiziertes Moment (Absolutwert) | Inneres Soll-Motormoment";
CM_ SG_ 1088 GE1_Fahrwistd "auf % Steigung am Berg normiert | Fahrwiderstandsindex";
CM_ SG_ 1088 GE1_Kuehlung "00: keine zusaetzliche Kuehlleistung | 01: Luefterleistung um 20% erhoehen | 10: Luefterleistung um 40% erhoehen, Wassertemp. 10 | 11: maximale Luefterleistung; Wassertemp. Senken (max) | Kuehlleistung";
CM_ SG_ 1088 GE1_Sta_OBD "Bit 7 steuert (nicht mehr Bit 6) die MIL-Lampe an (Motor-SG reicht diese Info an Kombi weiter) | OBD Status";
CM_ SG_ 1088 GE1_LaunchControl "Waehrend einer LaunchControl-Anfahrt sendet das Getriebesteuergeraet das Bit LaunchControl aktiv. | Die Bremse wertet dieses Bit aus, um waehrend einer solchen Anfahrt die Regelgrenzen der Schlupfregelung zu erweitern. | Im Motor Nutzung zur Verbesserung des Anfahrverhaltens durch EGR-Abschaltung (nach Absprache mit dem Motor-Projekt aktivierbar).";
CM_ SG_ 1088 GE1_Infobit "CVT-Getriebe (VL30,..) setzen Bit auf 1 | Sonstige Getriebe (z. B. Stufenautomat) geben 0 aus | Getriebeinfobit";
CM_ SG_ 1088 GE1_SleepInd "Die Sleep-Bereitschaft wird nach Klemme 15 aus durch Setzen dieses Bits signalisiert | NMHigh-Teilnehmer der PQ35/46 muessen das Signal nach Kl.-15 aus weiterhin bedienen oder dauerhaft auf 1 = 'Sleep bereit' setzen!";
CM_ SG_ 1088 GE1_Fehlereintr "Bei gesetztem Bit ist mindestens ein Kundendienstfehler eingetragen | Fehlerspeichereintrag (Getriebe 1)";
CM_ SG_ 1088 GE1_WaVerl_Mo "Kupplungsmoment bei ASG / DQ-Getriebe; wird als Vorsteuermoment fuer LFR genutzt | Gesamtes Aufnahmemoment des Getriebes | Hybrid: Kriechvorsteuerung soll bei Hybrid PL71 und PQ35 implementiert sein. | PL71H: im Low-Speed-Modus (elektrisch mit geschlossenem Triebstrang) ist das uebermittelte Moment als Fahrmoment umzusetzen. | Getriebeverlustmoment";
CM_ SG_ 1490 IDT_Mux "Multiplexbyte zur Berechnung der folgenden Datenbytes | Schaltet die naechsten 7 Byte um. | VW756/VW611: Reihenfolge der Inhalte fuer schnelle Initialisierung anderer Steuergeraete ueber Ident-Wert 0 folgendermassen definiert 0, 1, 0, 2, 0, 1, 0, ...";
CM_ SG_ 1490 IDT_VIN_13 "Multiplex = 2 | 13. Stelle der Fahrgestellnummer | WFS nicht angelernt: Ausgabe 'X' (0x58) oder '-' (0x2D)";
CM_ SG_ 1490 IDT_VIN_14 "Multiplex = 2 | 14. Stelle der Fahrgestellnummer | WFS nicht angelernt: Ausgabe 'X' (0x58) oder '-' (0x2D)";
CM_ SG_ 1490 IDT_VIN_15 "Multiplex = 2 | 15. Stelle der Fahrgestellnummer | WFS nicht angelernt: Ausgabe 'X' (0x58) oder '-' (0x2D)";
CM_ SG_ 1490 IDT_VIN_16 "Multiplex = 2 | 16. Stelle der Fahrgestellnummer | WFS nicht angelernt: Ausgabe 'X' (0x58) oder '-' (0x2D)";
CM_ SG_ 1490 IDT_VIN_17 "Multiplex = 2 | 17. Stelle der Fahrgestellnummer | WFS nicht angelernt: Ausgabe 'X' (0x58) oder '-' (0x2D)";
CM_ SG_ 1490 IDT_Geheimnis_1 "Multiplex = 0 | 1. Byte Fahrzeuggeheimnis (nicht PQ35/46)";
CM_ SG_ 1490 IDT_VIN_4 "Multiplex = 1 | 4. Stelle der Fahrgestellnummer | WFS nicht angelernt: Ausgabe 'X' (0x58) oder '-' (0x2D)";
CM_ SG_ 1490 IDT_VIN_11 "Multiplex = 2 | 11. Stelle der Fahrgestellnummer | WFS nicht angelernt: Ausgabe 'X' (0x58) oder '-' (0x2D)";
CM_ SG_ 1490 IDT_Geheimnis_2 "Multiplex = 0 | 2. Byte Fahrzeuggeheimnis (nicht PQ35/46)";
CM_ SG_ 1490 IDT_VIN_5 "Multiplex = 1 | 5. Stelle der Fahrgestellnummer | WFS nicht angelernt: Ausgabe 'X' (0x58) oder '-' (0x2D)";
CM_ SG_ 1490 IDT_VIN_12 "Multiplex = 2 | 12. Stelle der Fahrgestellnummer | WFS nicht angelernt: Ausgabe 'X' (0x58) oder '-' (0x2D)";
CM_ SG_ 1490 IDT_Geheimnis_3 "Multiplex = 0 | 3. Byte Fahrzeuggeheimnis (nicht PQ35/46)";
CM_ SG_ 1490 IDT_VIN_6 "Multiplex = 1 | 6. Stelle der Fahrgestellnummer | WFS nicht angelernt: Ausgabe 'X' (0x58) oder '-' (0x2D)";
CM_ SG_ 1490 IDT_Geheimnis_4 "Multiplex = 0 | 4. Byte Fahrzeuggeheimnis (nicht PQ35/46)";
CM_ SG_ 1490 IDT_VIN_1 "Multiplex = 0 | 1. Stelle der Fahrgestellnummer | WFS nicht angelernt: Ausgabe 'X' (0x58) oder '-' (0x2D)";
CM_ SG_ 1490 IDT_VIN_2 "Multiplex = 0 | 2. Stelle der Fahrgestellnummer | WFS nicht angelernt: Ausgabe 'X' (0x58) oder '-' (0x2D)";
CM_ SG_ 1490 IDT_VIN_9 "Multiplex = 1 | 9. Stelle der Fahrgestellnummer | WFS nicht angelernt: Ausgabe 'X' (0x58) oder '-' (0x2D)";
CM_ SG_ 1490 IDT_VIN_3 "Multiplex = 0 | 3. Stelle der Fahrgestellnummer | WFS nicht angelernt: Ausgabe 'X' (0x58) oder '-' (0x2D)";
CM_ SG_ 1490 IDT_VIN_10 "Multiplex = 1 | 10. Stelle der Fahrgestellnummer | WFS nicht angelernt: Ausgabe 'X' (0x58) oder '-' (0x2D)";
CM_ SG_ 1490 IDT_VIN_7 "Multiplex = 1 | 7. Stelle der Fahrgestellnummer | WFS nicht angelernt: Ausgabe 'X' (0x58) oder '-' (0x2D)";
CM_ SG_ 1490 IDT_VIN_8 "Multiplex = 1 | 8. Stelle der Fahrgestellnummer | WFS nicht angelernt: Ausgabe 'X' (0x58) oder '-' (0x2D)";
CM_ SG_ 1056 KO2_gef_Auss_T "realer Messbereich z. Zt. ca. -45..58 Grad | 0 fuer nicht verbaut | | im Fehlerfall (FFH) ggf. auf Byte 8, Bit 7..4 achten | Aussentemperatur gefiltert";
CM_ SG_ 1056 KO2_Verb_TOG "\"TOG nicht verbaut\": TOG nicht am Kombi angeschlossen | TOG-Botschaft wird nicht vom Kombi gesendet (Bit wird bei Audi nicht unterstuetzt)";
CM_ SG_ 1056 KO2_Oelwarn "Oelwarnschwelle plus Offset ueberschritten | (wird in mKombi_2 verwendet, falls bei WIV3.2 der TOG-Sensor nicht direkt am Kombi angeschlossen ist, siehe mKombi_2, Byte 1, Bit 1)";
CM_ SG_ 1056 KO2_GRA_High "Kombi unterstuetzt die 'GRA High' (Sollgeschwindigkeit wird angezeigt) | GRA-High-Anzeige im Display wird unterstuetzt";
CM_ SG_ 1056 KO2_Temp_Einheit "Aussentemperatur Anzeige im Kombi wird in Grad Celsius oder Fahrenheit gemacht | Temperatureinheit";
CM_ SG_ 1056 KO2_Wischwasser "Zusatzinfo zur Scheinwerferreinigungsanlage (z. Zt. nur Audi D3) | Wischwasserwarnung";
CM_ SG_ 1056 KO2_PLA_Displaystatus "Das Signal wird als aktive Rueckmeldung genutzt, ob die Info des PLA im Kombi angezeigt wird. Wenn nach Anforderung des Displays das Signal zweimal auf 0 ist, wird der Parkvorgang abgebrochen. | Ein Kombi, dass PLA Anzeige nicht unterstuetzt, schickt dauerhaft 0.";
CM_ SG_ 1056 KO2_Fehlereintr "Bei gesetztem Bit ist mindestens ein Kundendienstfehler eingetragen | Fehlerspeichereintrag (Kombi 2)";
CM_ SG_ 1056 KO2_Aussen_T "Klima-Steuergeraet kann aus dem Rohsignal eigene Plausibilitaeten berechnen | 0 fuer nicht verbaut | im Hochlauf alter abgespeicherter Wert bis neuer vorliegt | | Besonderheit Initwerte Temperaturen (bei VW und Audi ???): | 0: es liegt kein alter Wert vor (Kl.30 reset) | alt: der letzte bei Kl.15 aus abgespeicherte Wert (bei Audi-Kombis wird hier 01H ausgegeben) | | im Fehlerfall (FFH) ggf. auf Byte 8, Bit 7..4 achten | Aussentemperatur ungefiltert (Kombi 2)";
CM_ SG_ 1056 KBI_Anzeigestatus_LIM "Anzeigestatus der Speedlimiter Wunschgeschwindigkeitsanzeige im Kombiinstrument (permanenter Anzeigebereich) | 0 = nicht vorhanden | 1 = Wunschgeschwindigkeits-Anzeigemoeglichkeit vorhanden | 2 = reserviert | 3 = Fehler (Botschaftsueberwachung, Timeout, Akustik)";
CM_ SG_ 1056 KO_AWV_Zustandswechsel "Statuswechsel AWV";
CM_ SG_ 1056 KO_AWV_Vorw_Zustandswechsel "Statuswechsel AWV Vorwarnung";
CM_ SG_ 1056 KO_Aussensound_Zustandswechsel "Statuswechsel Aussensound-Aktivitaet durch Anwender";
CM_ SG_ 1056 KB2_EasyEntry "Umschaltanforderung von der MFA des Kombi-SG fuer die Aktivierung/Deaktivierung der Easy-Entry-Funktion im Memorysitz";
CM_ SG_ 1056 KO_Segeln_Menuestatus "Signalisierung ob im Kombi ein Menue fuer die Funktion \"Segeln\"/\"Freilauf\" verfuegbar ist";
CM_ SG_ 1056 KO_Segeln_Zustandswechsel "Statuswechsel Segelwunsch des Fahrers";
CM_ SG_ 1056 KB2_Auto_eKiSi "Umschaltung automatische E-KiSi";
CM_ SG_ 1056 KO2_Bel_Displ "Display-Beleuchtung, Tastverhaeltnis in Prozent | Klemme 58d";
CM_ SG_ 1056 KO2_Sta_Displ "N.i.O. steht fuer nicht verfuegbar oder Ersatzwert in Bit 6..0 wird vorgegeben (Standard) | VW Highline / Mini-DOT und Audi Kombis geben das mit dem Fototransister bewertete Signal aus | Fehlerstatus Kl. 58 d";
CM_ SG_ 1056 KO2_Bel_Schalt "Schalter-Beleuchtung (z.Zt. nur Audi) ,Tastverhaeltnis in Prozent | Klemme 58s (Kombi 2)";
CM_ SG_ 1056 KO2_Sta_Schalt "N.i.O. steht fuer nicht verfuegbar (z. Zt. bei VW) oder Ersatzwert in Bit 6..0 wird vorgegeben | Fehlerstatus Kl. 58 s (Kombi 2)";
CM_ SG_ 1056 KO2_MFA_v_Einheit "Meldung an den Motor, mit welcher Einheit die GRA-Geschwindigkeit dargestellt wird, damit der Motor in der Botschaft Motor_8 die GRA-Wunschgeschwindigkeit anzeigeoptimiert ausgeben kann (Verhinderung von Werten, die keiner Meilengroesse entsprechen). (im Audi B7, C6, D3, AU716, TTNF! Audi steuert mit dem Signal 'Einheit der angezeigten Geschwindigkeit' in Kombi_1, Byte 8, Bit 0 Hardwarevarianten des Kombis! Daher die Notwendigkeit dieses Signals 'MFA v Einheit')";
CM_ SG_ 1056 KO2_Passiv_Autolock "1 = Umschaltanforderung vom Kombi: \"Passiv Autolock / Autounlock\"";
CM_ SG_ 1056 KO2_WFS_Schl_Ort "Schluesselerkennung via Lesespule oder Keyless";
CM_ SG_ 1056 KB2_MFA_Strecke_Einheit "reserviert fuer SCR-Reststreckeneinheit (nur AU716!)";
CM_ SG_ 1056 KO2_OBD_Nib_Temp "Die Motorsteuerung muss bei einem Sensorfehler Fehlerarten unterscheiden koennen (CARB-Forderung) | (PQ35/46 geplant zu KW 22/07, Touareg GP 22/08) | 0000 = kein Fehler | 0001 = KS- | 0010 = KS+ | 0011 = OC | 0100 = OOR+ | 0101 = OOR- | 0110 = RC+ | 0111 = RC- | 1000 = KS+/OC | 1001 = KS-/OC | 1010 = KS-/KS+ | 1011 = KS-/KS+/OC | 1100 = frei | 1101 = fre | 1110 = frei | 1111 = frei | Fehler-Nibble Aussentemperatur";
CM_ SG_ 1056 KO2_Sta_Auss_T "Diese Botschaft wird mit der Botschaft mKombi_1 zeitlich verzahnt gesendet!!! | n.i.O. steht fuer Fehlerwert, ausserhalb des Messbereichs (ungenau), nicht verbaut oder noch kein aktueller Wert | | Besonderheit Initwerte Temperaturen (bei VW und Audi ???): | 0: Klemme 30 Reset | 1: Klemme 15 Hochlauf | | Fehlerstatus Aussentemperatur";
CM_ SG_ 1056 KBI_rotes_P_verbaut "Das Signal dient der EPB zur Unterscheidung, ob das Kombi das \"rote P\" unterstuetzt.";
CM_ SG_ 1056 KB2_Req_IstZu_Solldruecke "Anforderung fuer RKA/RDK die Istdruecke als neue Solldruecke zu uebernehmen fuer Systeme mit Menuebedienung im Kombi";
CM_ SG_ 1312 KO3_Radumfang "Code 10: mittlerer Reifenumfang in Millimeter (Byte 2 Bit 5,4 reserviert, Byte 2 Bit 3..0 und Byte 1 Bit 7..0; Wertebereich 0..4096 mm) | Kombi Multiplex Info (Radumfang)";
CM_ SG_ 1312 KO3_Land "Code 00: Laender- und Sprachvariante werden nur ausgegeben, wenn Sie im Kombi vorliegen (z.B. Highline) | Kombi Multiplex Info (Laendervariante)";
CM_ SG_ 1312 KO3_Mp_Code "Code 00 Laendervariante, Sprachvariante: Land, Sprache (nur Highline) | Code 01 Plattform: Plattforminfo, die im Kombi vorliegt | Code 10 Radumfang: mittlerer Radumfang (aus der K-Zahl gerechnet) | Code 11 Verbauliste: Verbauliste nach Kenntnisstand des Kombis | Muxinhalte zu Code \"01\" und \"11\" werden im Kombi Audi C6 nicht mehr unterstuetzt!!! | Kombi Multiplex Code";
CM_ SG_ 1312 KO3_Um_AutoHold "Umstellung der 'Auto Hold'-Funktion im MFA-Display als Rueckmeldung fuer die EPB (PQ46 ab 22/08, VW469) | Gedrueckter Taster bewirkt Umschaltung im EPB-Steuergeraet (siehe mEPB_1, Byte 5, Bit 2,3) | Auto Hold umschalten";
CM_ SG_ 1312 KO3_Standzeit "(0...36,4 h) Standzeit in 4 Sekunden Aufloesung | mit diesen 15 Bits laesst sich eine Zeit bis 36 Stunden, 24 Minuten und 28 Sekunden darstellen | Der Standzeitzaehler wird mit 'Klemme 15 aus' gestartet, er bleibt 2 Minuten vor einem Ueberlauf stehen, dieser alte Wert fuer den es keinen Ueberlauf geben darf, wird erst mit Motorstart und 2 Sekunden Motorlauf aktualisiert | | Beispiel fuer Standzeitzaehler: alter Zaehlerstand 343H, 'Klemme 15' 3 Minuten aus (45 x 4 Sekunden), | Zaehlerstand 370H (343H + 2DH), 'Klemme 15' 2 Tage (> 36 Stunden) aus, | Zaehlerstand 352H (370H - 1EH): dieser Zaehlerstand wuerde sich jetzt erst, nach einem erfolgreichen Motorstart (2 Sekunden Motorlauf) aendern | Anmerkung: Es wird der Wert aus dem letzten Zuendungslauf gesendet. Eine Aktualisierung erfolgt erst nach 'Kl.15 ein'";
CM_ SG_ 1312 KO3_Sprache "Code 00: Laender- und Sprachvariante werden nur ausgegeben, wenn Sie im Kombi vorliegen (z.B. Highline) | Kombi Multiplex Info (Sprachvariante)";
CM_ SG_ 1312 KO3_Derivat "Code 01: Plattforminformation entspricht dem Kenntnisstand des Kombis; als Derivat wird 0 (Kurzheck) ausgegeben, wenn es keine Besonderheiten abhaengig vom Derivat gibt | Kombi Multiplex Info (Plattform/Derivat)";
CM_ SG_ 1312 KO3_Verbau_Mot "Code 11: Verbauliste nach Kenntnisstand des Kombis | Verbauliste Motor";
CM_ SG_ 1312 KO3_Verbau_Get "Code 11: Verbauliste nach Kenntnisstand des Kombis | Verbauliste Getriebe";
CM_ SG_ 1312 KO3_Verbau_Br "Code 11: Verbauliste nach Kenntnisstand des Kombis | Verbauliste Bremse";
CM_ SG_ 1312 KO3_Verbau_Kl "Code 11: Verbauliste nach Kenntnisstand des Kombis | Verbauliste Klima";
CM_ SG_ 1312 KO3_Generation "Code 01: Plattforminformation entspricht dem Kenntnisstand des Kombis | Kombi Multiplex Info (Plattform/Generation)";
CM_ SG_ 1312 KO3_Verbau_Air "Code 11: Verbauliste nach Kenntnisstand des Kombis | Verbauliste Airbag";
CM_ SG_ 1312 KO3_Verbau_ADR "Code 11: Verbauliste nach Kenntnisstand des Kombis | Verbauliste ADR";
CM_ SG_ 1312 KO3_Verbau_BN "Code 11: Verbauliste nach Kenntnisstand des Kombis | Verbauliste Bordnetz";
CM_ SG_ 1312 KO3_Verbau_Syn "Code 11: Verbauliste nach Kenntnisstand des Kombis | Verbauliste Allrad";
CM_ SG_ 1312 KO3_Baureihe "Code 01: Plattforminformation entspricht dem Kenntnisstand des Kombis | Kombi Multiplex Info (Plattform/Baureihe)";
CM_ SG_ 1312 KO3_Verbau_LWS "Code 11: Verbauliste nach Kenntnisstand des Kombis | Verbauliste Lenkwinkel";
CM_ SG_ 1312 KO3_Verbau_DP "Code 11: Verbauliste nach Kenntnisstand des Kombis | Verbauliste Dieselpumpe";
CM_ SG_ 1312 KO3_Verbau_LH "Code 11: Verbauliste nach Kenntnisstand des Kombis | Verbauliste Lenkhilfe";
CM_ SG_ 1312 KO3_Marke "Code 01: Plattforminformation entspricht dem Kenntnisstand des Kombis | Kombi Multiplex Info (Plattform/Marke)";
CM_ SG_ 1312 KO3_Verbau_Niveau "Code 11: Verbauliste nach Kenntnisstand des Kombis | Verbauliste Niveauregulierung";
CM_ SG_ 1312 KBI_Oelwechsel_durchgefuehrt "Nach einen Oelwechsel(Service) ist die Ethanol Warmfahrwarnung zu unterdruecken.";
CM_ SG_ 1312 KO3_Schluessel "0 = ungueltig, xxxx = Schluessel-Nr. | Schluesselinformation (s. Kombi_3)";
CM_ SG_ 1312 KO3_Um_AFS2 "Aufforderung an das AFS. | Funktion auch waehrend der Fahrt bedienbar. | Gedrueckter Taster bewirkt Umschaltung im AFS-Steuergeraet (siehe mLWR_Zustand, LRZ_AFS_Absch & LRZ_AFS_deaktiv) | Umschaltung AFS II";
CM_ SG_ 1312 KO3_Um_Tourist "Aufforderung an das AFS. | Gedrueckter Taster bewirkt Umschaltung im AFS-Steuergeraet (siehe mLWR_Zustand, LRZ_Tourist_Fkt & LRZ_Tourist_aktiv) | Touristenfunktion umschalten";
CM_ SG_ 1312 KO3_SWA_AnzFeh "Kombiinstrument hat Fehler erkannt | SWA Anzeigefehler";
CM_ SG_ 1312 KO3_Sta_Standz "Reset Standzeit";
CM_ SG_ 1312 KO3_Kilometer "Kilometerstand";
CM_ SG_ 978 LH2_Checksumme "Pruefsumme mit Endwert 0x0, Definition im CAN Lastenheft (HS-CAN V4.2a, LS-CAN V1.42)";
CM_ SG_ 978 LH2_Zaehler "Freilaufender Botschaftszaehler, Definition nach CAN-Lastenheft";
CM_ SG_ 978 LH2_StatEPS_PLA "16 Statuswerte (siehe LH PLA/EPS) | Status EPS PLA";
CM_ SG_ 978 LH2_Geradeaus "Geradeausfahrt wird angezeigt, wenn sichergestellt ist, dass sich der Lenkwinkel im Sektor +-180deg befindet (Mittensektoranzeige) | (nur der LWS empfaengt dieses Bit noch)";
CM_ SG_ 978 LH2_Sta_Charisma "Bedeutung der Status-Indices: | 0: Charisma in der EPS deaktiviert | 1: Sonderkennung mit Komfort-Charakteristik | 2: Default: Standardkennung der EPS | 3: Sonderkennung mit Sport-Charakteristik | Status Charisma";
CM_ SG_ 978 LH2_Sta_HCA "Bedeutung der Status-Indizes: | 0: HCA in der EPS deaktiviert | 1: HCA Anforderung nicht ausfuehrbar aufgrund von Init-Phase o.Ae. ohne Fehlerspeichereintrag in der Lenkung (Initialisierung, Ausschaltphase, ) | 2: HCA Anforderung nicht ausfuehrbar aufgrund eines Fehlers mit Fehlerspeichereintrag in der Lenkung (z.B. Kommunikation zum HCA-SG gestoert, ) | 3: EPS bzgl. HCA funktionsbereit | 4: HCA Anforderung abgewiesen | 5: HCA Momenteneingriff aktiv, Active Return aktiv | 7: HCA Momenteneingriff aktiv, Active Return deaktiv | Status HCA";
CM_ SG_ 978 LH2_Ausg_LW1 "Steht dieser Wert auf 1, gibt die Lenkhilfe die Lenkwinkelbotschaft Lenkwinkel1 aus. Die Ausgabe ist ueber den Tester aktivierbar. Dies setzt voraus, dass der Lenkstockschalter diese Botschaft nicht ausgibt.";
CM_ SG_ 978 LH2_Ausg_LW1_gue "Signal Ausgabe LW1 darf nur ausgewertet warden, wenn das Gueltigkeitsbit gesetzt ist. | Gueltigkeit Ausgabe LW1";
CM_ SG_ 978 LH2_aktLenkeingriff "Indikation, welcher Eingriff in die Momentenschnittstelle der EPS in der Umsetzung ist. | Bitfeldreihenfolge entspricht Prioritaet, EPS priorisiert bei zeitgleicher Anforderung | Bit 0: kein Eingriff | Bit 1: DSR | Bit 3: Heading Control | Bit 5: Torque Steer | Bit 6: PLA | Lenkeingriff aktiv";
CM_ SG_ 978 LH2_PLA_Err "Art des Fehlers ohne Eintrag, 16 Werte moeglich (siehe LH EPS/PLA)";
CM_ SG_ 978 LH2_PLA_Abbr "Grund des PLA-Abbruchs, 16 Werte moeglich (siehe LH EPS/PLA)";
CM_ SG_ 208 LH3_Checksumme "Pruefsumme mit Endwert 0x0, Definition im CAN Lastenheft (HS-CAN V4.2a, LS-CAN V1.42)";
CM_ SG_ 208 LH3_Zaehler "Freilaufender Botschaftszaehler, dient als Quelle des Botschaftsspiegels in Lenkhilfe_3 Botschaft | Botschaftszaehler (Lenkhilfe 3)";
CM_ SG_ 208 LH3_LM "Gibt das durch den Momentensensor detektiertes Lenkhandmoment (Absolutmoment) aus";
CM_ SG_ 208 LH3_LMSign "Vorzeichen Lenkhandmoment";
CM_ SG_ 208 LH3_LMValid "Gueltigkeit der Signale Lenkhandmoment und Vorzeichen Lenkhandmoment";
CM_ SG_ 208 LH3_Sta_DSR "0 DSR deaktiviert | 1 DSR Anforderung nicht ausfuehrbar (ESP Fehlerstatus) | 2 Kommunikation zum ESP-SG gestoert | 3 EPS bzgl. DSR funktionsbereit | 4 DSR Anforderung abgewiesen | 5 externer Momenteneingriff aktiv | 6 externer Lenkwinkeleingriff aktiv | 7 externer Momenten und Lenkwinkeleingriff aktiv | 8..15 reserviert | Status DSR";
CM_ SG_ 208 LH3_BLW "Berechneter Lenkradwinkel (BLW) | Ausgabe des berechneten Lenkwinkel mit Geradeauslaufkorrektur aus der Position des Lenkmotors (Absolutwert) | (nur zur festgelegten Nutzung im ABS, ESP, PLA, HCA freigegeben)";
CM_ SG_ 208 LH3_BLWSign "Vorzeichen \"Berechneter Lenkwinkel\"";
CM_ SG_ 208 LH3_BLWValid "Gueltigkeit der Signale \"Berechneter Lenkwinkel\" (BLW und BLW Sign) | Beim Typ CEPS gibt es keinen definierten Zeitraum, in dem das Signal gueltig ist.";
CM_ SG_ 208 LH3_Lenkungstyp "0 Elektrik Power Steering mit DSR1 (Version ab KW22/05) | 1 Achsparalleler Antrieb | 2 Active Dynamik Steering (Audi) / CEPS (VW120) | 3 Elektrik Power Steering mit DSR2 (Version ab KW22/07)";
CM_ SG_ 208 LH3_BS_Spiegel "Der Botschaftsspiegel reflektiert die zuletzt empfangene Botschaft der mBremse_9, d. h. der zuletzt empfangene Wert des Botschaftszaehlers aus der mBremse_9 wird zurueckgesendet";
CM_ SG_ 640 MO1_Kup_schalt "nur Handschalter | aktiv, wenn Schalter verbaut, sonst konstant auf 0 gesetzt | Bit wird gesetzt, wenn Kupplungspedal nicht betaetigt wird (Kupplungsschalter hoch), Triebstrang kann noch eingekuppelt sein | Kupplungsschalter";
CM_ SG_ 640 MO1_TiOut_Br "500 msec Time Out auf Bremsen-Botschaft ist >= 1 mal aufgelaufen, Loeschen des Bits nach Neustart (Kl.15)";
CM_ SG_ 640 MO1_Sta_Bremse "Eingriffswunsch (ASR oder MSR) vom Bremsen-Steuergeraet (ABS) kann nicht ausgefuehrt werden, weil im Motorsteuergeraet ein statischer Fehler vorliegt oder die Funktion durch die Applikation abgeschaltet ist | Fehlerstatus Brems-Momenteneingriff";
CM_ SG_ 640 MO1_Sta_MotMo "ungenaue Momentenangaben, weil die Momente aus Ersatzwerten berechnet wurden (z.B. HFM ausgefallen)";
CM_ SG_ 640 MO1_Mo_m_ex "\"indiziertes Motormoment\", d.h. idealisiertes berechnetes Moment ohne mechanische Verluste, aber mit externen Eingriffen | | Hybrid: | Es sind drei Faelle zu unterscheiden: | 1. offene K0: von positiven EM-Momenten (egal ob Eingriffs- oder Fahrmoment) werden negative EM-Eingriffsmomente abgezogen. | 2. schlupfende K0: von positiven EM-Momenten (egal ob Eingriffs- oder Fahrmoment) werden negative EM-Eingriffsmomente abgezogen; zusaetzlich wird, falls das Vorzeichen der DZ-Differenz von VM und EM positiv ist, die momentane Kapazitaet der K0 addiert. | 3. geschlossene K0: Zum indizierten VM-Moment mE wird ein positives EM-Moment (egal ob Eingriffs- oder Fahrmoment) addiert und ein negatives Eingriffs-EM-Moment abgezogen. | | (Achtung: Negative Fahrmomente der EM (Rekuperationsmomente) werden nicht abgezogen. Diese gehen ins Verlustmoment ein). | (Achtung: Eine negativ schlupfende K0 geht ins Verlustmoment ein). | | Bem. Negative Eingriffsmomente beim Hybrid sind wie bei herkoemmlichen Fzg-Projekten auf das in dieser Zeile dargestellte indizierte Moment beschraenkt. | Synchrone Erfassung von Verbrenner- und E-Maschinenmoment muss gegeben sein. | Es gilt: Kurbelwellen-Moment mE = indiziertes Moment mE - Verlustmoment.";
CM_ SG_ 640 MO1_Drehzahl "Low Byte 3, High Byte 4; es wird der letzte aktuelle Messwert gesendet, d.h. die Zeit fuer das letzte Arbeitsspiel (180 Grad KW beim 4 Zylinder) wird herangezogen; der Fehlerwert wird gesendet, wenn das Motor-steuergeraet keine plausible Drehzahlinformation hat, aber trotzdem noch funktionsfaehig ist. | 0xFF in Byte 4: Fehler | | Hybrid (Signal \"E-Motordrehzahl\"): | E-Maschinendrehzahl, Verwendung als Antriebs-DZ in GSG.";
CM_ SG_ 640 MO1_Pedalwert "Bei E-Gas wird hier der Fahrpedalwert ausgegeben | Maximum aus Rohsignal, gefiltertem Wert (TDI) und virtuellem Wert aus Kennfeld (bei aktiver integrierter GRA), Wert wird bei Doppelpotis auch bei einer defekten Poti-Spur ausgegeben, genutzter Wertebereich 0..100% | Bei aktivem Winterfahrprogramm wird das Signal nach unten korrigiert und entspricht dann nicht mehr dem physikalischen Wert. | Fahrpedalwert oder Drosselklappenpoti";
CM_ SG_ 640 MO1_Verlustmo "konventionell: mechanisches Motor-Verlustmoment, beinhaltet Reibung des Motors und Momente des Klimakompressors und Generators | | Hybrid allgemein (Signal \"Summe negative Momente\"): | negatives E-Maschinenmoment sowie ein negativer Momentenbeitrag durch negativ schlupfende K0 und mechanisches Verlustmoment werden hier addiert. | Diese Zeile aendert sich bei Momenteneingriffen nicht, so dass sie gleichermassen fuer die Berechnung von mE- und oE - Kurbelwellenmomenten nutzbar ist. | | Hybrid PQ35: | Statt des aktuellen E-Maschinenmoments wird das minimal darstellbare E-Maschinenmoment zur Bestimmung des Fusspunktes herangezogen. (Ergibt einen Offset auf Verlustmoment und ind. Motormoment. Dadurch sind reduzierende Eingriffe auch unterhalb des Schubmomentes moeglich.)";
CM_ SG_ 640 MO1_Wunschmo "Moment vor Filter, nutzbar zur Zug- / Schuberkennung beim Getriebe (beim Diesel identisch mit innerem Moment, ohne externe Eingriffe) | | Hybrid: | Moment vor Filter inkl. K0-Beitrag bei negativ schlupfender K0. | Zur Verwendung in Schaltstrategie: Fahrerwunsch sollte nicht durch zB Rauchkennfeld (Diesel) o.Ae. begrenzt werden. | Fahrerwunschmoment";
CM_ SG_ 640 MO1_Leergas "Motorbetriebszustand ist Leerlauf, keine Momentenerhoehung durch Fahrpedal, ACC, GRA+";
CM_ SG_ 640 MO1_Sta_Pedal "Ersatzwert aus Modellrechnung oder Fehlerwert in Byte 6, Leergas- oder Kickdown-Info koennen betroffen sein | Fahrpedalwert ungenau (Motor 1)";
CM_ SG_ 640 MO1_Kickdown "0 kann fuer nicht verbaut stehen, bei Doppelanalogpedalwertgeber ggfs. errechneter Wert | Kickdownschalter";
CM_ SG_ 640 MO1_Sta_Getr "Eingriffswunsch vom Getriebe-Steuergeraet kann ggfs. nicht oder nicht vollstaendig ausgefuehrt werden, weil entweder im Motorsteuergeraet ein statischer (!) Fehler vorliegt oder die Momentenanforderung des Getriebe-Steuergeraetes aus Sicht des Motorsteuergeraetes nicht erfuellt werden darf (z. B. Leerlaufregler fordert hoeheres Moment) (im Colorado) (im PQ35/46 fuer alle Getriebe) | Fehlerstatus Getriebe-Momenteneingriff";
CM_ SG_ 640 MO1_Mo_o_ex "indiziertes Motormoment ohne externe Eingriffe (ASR, MSR, Getriebe,..), aber inklusive integrierter GRA | | Hybrid: | Es sind drei Faelle zu unterscheiden: | 1. offene K0: positive EM-Momente (nur Fahrmomente) | 2. schlupfende K0: zu positiven EM-Momenten (nur Fahrmomente) wird, falls das Vorzeichen der DZ-Differenz von VM und EM positiv ist, die momentane Kapazitaet der K0 addiert. | 3. geschlossene K0: Zum indizierten VM-Moment oE wird ein positives EM-Moment (nur Fahrmoment) addiert. | | Synchrone Erfassung von Verbrenner- und E-Maschinenmoment muss gegeben sein. | Es gilt: Kurbelwellen-Moment oE = inneres Motor-Moment oE Verlustmoment | Bem. Das herkoemmliche indizierte VM-Moment oE ist das indizierte VM-Moment ohne externe Eingriffe (ASR, MSR, Getriebe,..), aber inklusive integrierter GRA.";
CM_ SG_ 648 MO2_Getr_Code "Multiplex-Info (Getriebe-Kodierinfo)";
CM_ SG_ 648 MO2_max_Mo "Multiplex-Info (maximales Moment (Normierwert MDI))";
CM_ SG_ 648 MO2_Mp_Code "Multiplex-Code und Multiplex-Info sind verkettet | der Multiplex-Code wird nach 4 Uebertragungen weitergeschaltet; dieser Mechanismus wiederholt sich somit nach 4 x 4 = 16 Umlaufzeiten";
CM_ SG_ 648 MO2_BLS "Ungefiltertes Rohsignal (Fzg. ohne BLS (z. B. Touareg GP): siehe \"Spezifikation Schnittstelle und Verhalten bei Fahrerbremsung fuer Motorsteuergeraet und Bremsensteuergeraet im Touareg GP\", Autor M. Williges)";
CM_ SG_ 648 MO2_Sta_No_Bet "Normalbetrieb steht fuer Klemme 15 ein, Initialisierungsphase abgeschlossen und kein Motorstartvorgang (aus Sicht des Motorsteuergeraetes)";
CM_ SG_ 648 MO2_Sta_GRA "00 steht auch fuer nicht verbaut und ADR nicht zulaessig | 01 bedeutet eingeschaltet, GRA vom Fahrer aktiviert und z.Zt. im Regelbetrieb oder ADR erlaubt | 10 Fahrer gibt mehr Gas als der Regler | 11 Fehler in Motorsteuerung oder Time out oder CS-Fehler in Botschaft ADR1 oder Anforderung des ADR trotz 00 in diesen beiden Bits";
CM_ SG_ 648 MO2_OffRoad "OffRoad-Modus aktiv (verwendet im VW316; verwendet im VW21x GP mit Motor EA211 in Zusammenhang mit ESC Bosch 9.0) | Zuschaltung folgender Funktionen: Anfahrhilfe, flache Fahrpedalkennung, AQ Gangstufenvorwahl, Hill Descent Control | (Info: Byte 4 war \"Fahrzeuggeschwindigkeit\" teilw. noch im PQ25,T5GP)";
CM_ SG_ 648 MO2_LL_Solldz "statischer Vorgabewert fuer CVT Getriebe | | Hybrid PQ35 und Hybrid PL71: | Verbrennungsmotor-LL-Soll-DZ soll bei KL15 ein immer gesendet werden. | Leerlaufsolldrehzahl (Motor 2)";
CM_ SG_ 648 MO2_CAN_Vers "Multiplex-Info (CAN-Version)";
CM_ SG_ 648 MO2_Kuehlm_T "Motor-Kuehlmitteltemperatur oder Ersatzwert | Initwert 0 ist ausserhalb des Wertebereichs";
CM_ SG_ 648 MO2_BTS "Ein Empfaenger kann BLS und BTS miteinander plausibilisieren (\"0\" fuer nicht verbaut) | Fzg. ohne BTS (z.B. PQ46): Bit aus Bremse 1, Byte 2, Bit 3 Bremsdruckschwelle ueberschritten wird gespiegelt | Touareg GP: siehe \"Spezifikation Schnittstelle und Verhalten bei Fahrerbremsung fuer Motorsteuergeraet und Bremsensteuergeraet im Touareg GP\", Autor M. Williges";
CM_ SG_ 648 MO2_Sta_Kuehlm "n i.O. steht fuer Ersatzwert oder Fehlerwert in Byte 2 | Fehlerstatus Kuehlmitteltemperatur (Motor 2)";
CM_ SG_ 648 MO2_Sta_Klima "Zustand des Klimakompressors, d.h. Rueckmeldung der bidirektionalen Schnittstelle (konventionell oder CAN) | Ansteuerung Klima";
CM_ SG_ 648 MO2_Status_TSK "Status Triebstrangkoordinator (gueltig ab Antrieb-CAN-Version 5.1.x) | (Info: war \"OBD2 freeze frame\")";
CM_ SG_ 648 TSK_Limiter_ausgewaehlt "ACC/GRA-Betrieb nur bei nicht ausgewaehltem Limiter moeglich | (Info: Byte 4 war \"Fahrzeuggeschwindigkeit\" teilw. noch im PQ25,T5GP)";
CM_ SG_ 648 MO2_GRAregelt "GRA regelt auf die im Kombi angezeigte Geschwindigkeit: 'GRA High Funktion' (z.Zt. nur in Fahrzeugen mit neuer Konzern-GRA, z.B. PQ46) | (Info: Byte 4 war \"Fahrzeuggeschwindigkeit\" teilw. noch im PQ25,T5GP)";
CM_ SG_ 648 MO2_Sport_Error "Bit wird gesetzt, wenn die Funktion \"Sport\" durch das Motor SG nicht realisiert werden kann (nur Otto im Porsche Cayenne) | (Info: Byte 4 war \"Fahrzeuggeschwindigkeit\" teilw. noch im PQ24,T5GP)";
CM_ SG_ 648 MO2_RME_Gehalt "Rapsoelmethylester-Gehalt (Diesel) (wird z. Zt. nicht bedient) | (evtl. mit Bio-Ethanol-Gehalt bei Benzinern belegen) | (Info: Byte 4 war \"Fahrzeuggeschwindigkeit\" teilw. noch im PQ25,T5GP)";
CM_ SG_ 648 MO2_GRA_Soll "eingestellte GRA-Sollgeschwindigkeit | Achtung: Nicht fuer neue Projekte verwenden, nachdem neue GRA implementiert ist! | Entfall/Umdefinition geplant. Alternative Groesse in Botschaft ACC_GRA_Anzeige.";
CM_ SG_ 648 MO2_Begr_Mo "inneres maximal moegliches Moment bei einer Drehzahl (z.B. Rauch-begrenzung oder Fehlerfall) | | Hybrid (Signal \"Max. moegl. ind. Moment\"): | Ist ein indiziertes Moment. | Max. moegliches positives E-Maschinen-Moment muss hier aufaddiert werden.;Groesse kann nur >= 0 sein. | Begrenzungsmoment";
CM_ SG_ 648 MO2_Mo_ZWR "Ist ein indiziertes Moment. Beinhaltet ZWR, Einspritz-Ausblendung und minimales EM-Moment. | | konventionell: | Min. Motormoment bei Zuendwinkelruecknahme nur bei Otto-Motoren (Diesel setzt Byte auf 0) | | Hybrid: | Eingriffe auf das Kurbelwellenmoment sind auch mittels E-Maschine moeglich, jedoch nur im Rahmen des ind. Momentes oE aus mMotor_1, => Groesse kann nur >=0 sein.";
CM_ SG_ 648 MO2_Motor_Code "Multiplex-Info (Motor-Kodierinfo)";
CM_ SG_ 896 MO3_Pedalwert "Siehe Fahrpedalspezifikation | Fahrpedal-Rohsignal";
CM_ SG_ 896 MO3_Vorgluehen "Vorgluehmeldung ohne Aufpruefen. Diesel-SG initialisieren mit \"1\" und senden solange den Wert \"1\" bis entweder die Gluehzeitberechnung ergeben hat, dass nicht vorgeglueht werden muss oder der Vorgluehvorgang beendet wurde. Otto-SG senden konstant \"0\".";
CM_ SG_ 896 MO3_Prio_Dz "Wunschdrehzahl in Byte 7 ist als Zwang oder als Wunsch an das Getriebe zu interpretieren | (Info: war \"Uebertemperaturschutz\" teilw. noch im PQ25,T5GP) | Motor Wunschdrehzahl Prioritaet";
CM_ SG_ 896 MO_Schalter_StartStopp "Deaktivierung Start/Stopp durch den Fahrer";
CM_ SG_ 896 MO3_Winterprg "Bei aktivem Winterfahrprogramm wird die Ausgabe des Pedalkennfeldes im Motor modifiziert (PQ35)";
CM_ SG_ 896 MO3_Sta_FPG "Nur wenn das Bit \"Steuerungsbit Fahrpedalgradient\" gesetzt ist werden die beide Signale: \"Fahrpedalgradient\" (Motor 3 Byte 8 Bit 7..0) und \"Vorzeichen Fahrpedalgradient\" (Motor 3 Byte 3 Bit 6) vom ESP-Steuergeraet zur Vorbefuellung der Radbremsen zur Verkuerzung der Anhalteweges genutzt. (AU716, Audi TTNF, T5, C6, D3) | Wenn das Bit nicht gesetzt ist, wird in Byte 8 weiterhin das Signal Drosselklappenpoti uebertragen. | (Info: war \"Drosselklappenwinkel ungenau\")";
CM_ SG_ 896 MO3_Sign_FPG "Kennzeichnet das Vorzeichen des Signals \"Fahrpedalgradient\" (Motor 3 Byte 8 Bit 7...0). Die Ausgabe erfolgt nur bei parallel statisch mit gesendetem Signal: \"Steuerungsbit Fahrpedalgradient\" (Motor 3 Byte 1 Bit 5) (AU716, Audi TTNF, T5, D3, C6)";
CM_ SG_ 896 MO3_Sta_Temp "Ersatzwert oder Fehlerwert | Fehlerstatus Ansauglufttemperatur";
CM_ SG_ 896 MO3_Aussentemp "In Fahrzeugen ohne Aussentemperatur vom Kombi kann aus der Ansauglufttemperatur auf die Aussentemperatur geschlossen werden. Beim SDI ist das mit einer gewissen Genauigkeit gegeben. Genutzt wird es vom ASG. | Ansauglufttemperatur";
CM_ SG_ 896 MO3_Rad_Wu_Mo "Low Byte 4; High Nibble in Byte 5; der Wertebereich geht damit von 0 bis 4094 x 0,39 Prozent MDI (Byte 4 entspricht in der Darstellung den anderen Motormomenten, Nibble in Byte 5 ist die Erweiterung) | Rad-Wunschmoment";
CM_ SG_ 896 MO3_Vorz_RadWu "Vorzeichen-Bit Rad-Wunschmoment";
CM_ SG_ 896 MO3_Freigabe_Segeln "Freigabebit des Segelbetriebs im Getriebe. Bedingt durch bestimmte Diagnosen und Adaptionen des MSGs, die nur im Schub moeglich sind, darf nicht jede Schubphase fuer einen Segelbetrieb genutzt werden. Eine Freigabe bleibt auch ausserhalb einer Schubphase bestehen. D.h. das Signal kennzeichnet nicht die Schubphase sondern sagt nur aus, dass aus Motorsicht nichts gegen einen Segelbetrieb in einer der naechsten Schubphasen spricht.";
CM_ SG_ 896 MO_StartStopp_StoppVorbereitung "Zeigt allen aktiven Start-/Stoppteilnehmern einen moeglichen Motorstopp im Anhaltevorgang an (Empfaenger notwendige Vorbereitungen treffen) | Es liegen keine Vetos vor.";
CM_ SG_ 896 MO3_Dz_Beeinfl "Mit diesem Faktor kann das Motorsteuergeraet die vom VL30-Getriebe einzustellende Sollmotordrehzahl beeinflussen. Im VL30-Steuergeraet ist ein verbrauchsoptimales Kennfeld und ein abgasoptimiertes Kennfeld abgelegt. Mit dem Wert von 0-100% wird zwischen diesen beiden Kennfeldern interpoliert. Dabei bedeutet 0% verbrauchoptimale Motordrehzahl. Solange ein Wert > 0% uebertragen wird, ist die Fahrerbewertung (DSP) deaktiviert. | Motordrehzahlbeeinflussung";
CM_ SG_ 896 MO3_WunschDz "wenn das Bit 'Motor-Wunschdrehzahl Prioritaet' (Byte 1, Bit 1) gesetzt ist, wird hier vom Motor-SG eine wegen Uebertemperaturschutz oder wegen Motor internen Fehlern bedingte Maximal-Motordrehzahl ausgegeben, die das Getriebe-SG durch Rueckschaltungen nicht ueberschreiten darf | wenn das Bit nicht gesetzt ist, wird die Wunschdrehzahl vom Getriebe nicht beruecksichtigt";
CM_ SG_ 896 MO3_DKW "Rohsignal des Drosselklappenpotis bei Otto Motor Steuergeraeten mit E-Gas | Entfall zukuenftig geplant | Die Ausgabe erfolgt nur wenn Signal: \"Steuerungsbit Fahrpedalgradient\" (Motor 3, Byte 1, Bit 5) auf 0";
CM_ SG_ 896 MO3_FPGradient "Das Motorsteuergeraet besitzt 2 analoge Fahrpedalsignale. Diese werden alle 4ms abgetastet. Entsprechend der Steuergeraete spezifischen Zykluszeit (Otto-Motor-Steuergeraete: alle 10ms, Diesel-Motor-Steuergeraete: alle 20ms), dann die einzelnen Gradienten berechnet und der kleinste Fahrpedalgradient des aktuellen Fuehrungs- Fahrpedals ausgegeben. Zuvor erfolgt noch eine Entjitterung des Fahrpedalsignal um Bitschwankungen des A/D-Wandler heraus zu filtern. Bei einem Fehler in einem der beiden Fahrpedalsignale wird der Fahrpedalgradienten des verbleibenden Fahrpedalsignals ausgegeben. Bei einem Totoalausfall von beiden Fahrpedalsignalen wird FFh uebermittelt. Die Ausgabe erfolgt nur bei parallel statisch mit gesendetem Signal: \"Steuerungsbit Fahrpedalgradient\" (Motor 3 Byte 1 Bit 5) | (ESP-Projekte in AU716, Audi TTNF, T5, D3, C6) | (Rohsignal des Drosselklappenpotis kann weiterhin uebertragen werden, wenn Motor 3 Byte 1 Bit 5 nicht gesetzt ist) | Fahrpedalgradient";
CM_ SG_ 896 MO3_Sta_Pedal "Ersatzwert in Byte 3, Leergas- oder Kickdown-Info koennen betroffen sein | Fahrpedalwert ungenau (Motor 3)";
BA_DEF_ BO_ "GenMsgCycleTime" INT 0 65535;
BA_DEF_ BO_ "GenMsgSendType" STRING ;
BA_DEF_ SG_ "GenSigSendType" STRING ;
BA_DEF_DEF_ "GenMsgCycleTime" 0;
BA_DEF_DEF_ "GenMsgSendType" "";
BA_DEF_DEF_ "GenSigSendType" "";
BA_ "GenMsgCycleTime" BO_ 1494 100;
BA_ "GenMsgSendType" BO_ 1494 "Cyclic";
BA_ "GenSigSendType" SG_ 1494 PLS_Bremsleuchte "Cyclic";
BA_ "GenSigSendType" SG_ 1494 PLS_Anf_Anz "Cyclic";
BA_ "GenSigSendType" SG_ 1494 PLS_Akustik1 "Cyclic";
BA_ "GenSigSendType" SG_ 1494 PLS_PL_Exist "Cyclic";
BA_ "GenSigSendType" SG_ 1494 PLS_Akustik2 "Cyclic";
BA_ "GenSigSendType" SG_ 1494 PLS_Mehrzg_Aktiv "Cyclic";
BA_ "GenSigSendType" SG_ 1494 PLS_Pos_OK "Cyclic";
BA_ "GenSigSendType" SG_ 1494 PLS_PL_Seite "Cyclic";
BA_ "GenSigSendType" SG_ 1494 PLS_Lenk_Aktiv_Hinweis "Cyclic";
BA_ "GenSigSendType" SG_ 1494 PLS_Meldungen "Cyclic";
BA_ "GenSigSendType" SG_ 1494 PLS_Fahrtrichtg_Mehrzg "Cyclic";
BA_ "GenSigSendType" SG_ 1494 PLS_Text_Multiplexer "Cyclic";
BA_ "GenSigSendType" SG_ 1494 PLS_Schwellpfeil_rel "Cyclic";
BA_ "GenSigSendType" SG_ 1494 PLS_Anf_Anz_Schwellpfeil "Cyclic";
BA_ "GenSigSendType" SG_ 1494 PLS_Laengs_Querluecke "Cyclic";
BA_ "GenSigSendType" SG_ 1494 PLS_Standby "Cyclic";
BA_ "GenSigSendType" SG_ 1494 PLS_Bremssymbol "Cyclic";
BA_ "GenSigSendType" SG_ 1494 PLS_Kurze_Luecke "Cyclic";
BA_ "GenSigSendType" SG_ 1494 PLS_Schwellpfeil_abs "Cyclic";
BA_ "GenSigSendType" SG_ 1494 PLS_Akustik "Cyclic";
BA_ "GenSigSendType" SG_ 1494 PLS_Ausparken_Aktiv "Cyclic";
BA_ "GenSigSendType" SG_ 1494 PLS_Texte "Cyclic";
BA_ "GenMsgCycleTime" BO_ 1500 100;
BA_ "GenMsgSendType" BO_ 1500 "Cyclic";
BA_ "GenSigSendType" SG_ 1500 VL1_Motor_SG "Cyclic";
BA_ "GenSigSendType" SG_ 1500 VL1_Getr_SG "Cyclic";
BA_ "GenSigSendType" SG_ 1500 VL1_LSM "Cyclic";
BA_ "GenSigSendType" SG_ 1500 VL1_Airbag "Cyclic";
BA_ "GenSigSendType" SG_ 1500 VL1_Allrad "Cyclic";
BA_ "GenSigSendType" SG_ 1500 VL1_ADR "Cyclic";
BA_ "GenSigSendType" SG_ 1500 VL1_Anhaenger "Cyclic";
BA_ "GenSigSendType" SG_ 1500 VL1_ABS "Cyclic";
BA_ "GenSigSendType" SG_ 1500 VL1_Kombi "Cyclic";
BA_ "GenSigSendType" SG_ 1500 VL1_Lenkhilfe "Cyclic";
BA_ "GenSigSendType" SG_ 1500 VL1_dyn_LWR "Cyclic";
BA_ "GenSigSendType" SG_ 1500 VL1_res_08 "Cyclic";
BA_ "GenSigSendType" SG_ 1500 VL1_ADR_getrennt "Cyclic";
BA_ "GenSigSendType" SG_ 1500 VL1_EPB "Cyclic";
BA_ "GenSigSendType" SG_ 1500 VL1_res_13 "Cyclic";
BA_ "GenSigSendType" SG_ 1500 VL1_Daempfer "Cyclic";
BA_ "GenSigSendType" SG_ 1500 VL1_Quersperre "Cyclic";
BA_ "GenSigSendType" SG_ 1500 VL1_MotorSlave "Cyclic";
BA_ "GenSigSendType" SG_ 1500 VL1_SWA "Cyclic";
BA_ "GenSigSendType" SG_ 1500 VL1_HCA "Cyclic";
BA_ "GenSigSendType" SG_ 1500 VL1_RKA_Plus "Cyclic";
BA_ "GenSigSendType" SG_ 1500 VL1_PLA "Cyclic";
BA_ "GenSigSendType" SG_ 1500 VL1_WFS_KBI "Cyclic";
BA_ "GenSigSendType" SG_ 1500 VL1_Kombi_KBI "Cyclic";
BA_ "GenSigSendType" SG_ 1500 VL1_Soll_eq_Ist "Cyclic";
BA_ "GenSigSendType" SG_ 1500 VL1_BSG_Komf "Cyclic";
BA_ "GenSigSendType" SG_ 1500 VL1_ZKE "Cyclic";
BA_ "GenSigSendType" SG_ 1500 VL1_TSG_FT "Cyclic";
BA_ "GenSigSendType" SG_ 1500 VL1_TSG_BT "Cyclic";
BA_ "GenSigSendType" SG_ 1500 VL1_TSG_HL "Cyclic";
BA_ "GenSigSendType" SG_ 1500 VL1_TSG_HR "Cyclic";
BA_ "GenSigSendType" SG_ 1500 VL1_Memory "Cyclic";
BA_ "GenSigSendType" SG_ 1500 VL1_Dachmodul_K "Cyclic";
BA_ "GenSigSendType" SG_ 1500 VL1_Zentralelektrik_II "Cyclic";
BA_ "GenSigSendType" SG_ 1500 VL1_RDK "Cyclic";
BA_ "GenSigSendType" SG_ 1500 VL1_Lenksaeule "Cyclic";
BA_ "GenSigSendType" SG_ 1500 VL1_Gateway "Cyclic";
BA_ "GenSigSendType" SG_ 1500 VL1_Clima_Komf "Cyclic";
BA_ "GenSigSendType" SG_ 1500 VL1_Einparkhilfe "Cyclic";
BA_ "GenSigSendType" SG_ 1500 VL1_PTC_Heizung "Cyclic";
BA_ "GenSigSendType" SG_ 1500 VL1_Standheiz "Cyclic";
BA_ "GenSigSendType" SG_ 1500 VL1_Verdeck "Cyclic";
BA_ "GenSigSendType" SG_ 1500 VL1_RSE_I "Cyclic";
BA_ "GenSigSendType" SG_ 1500 VL1_res_42 "Cyclic";
BA_ "GenSigSendType" SG_ 1500 VL1_MDI_I "Cyclic";
BA_ "GenSigSendType" SG_ 1500 VL1_Memory_BF "Cyclic";
BA_ "GenSigSendType" SG_ 1500 VL1_Easy_Entry_VF "Cyclic";
BA_ "GenSigSendType" SG_ 1500 VL1_Easy_Entry_VB "Cyclic";
BA_ "GenSigSendType" SG_ 1500 VL1_Heckdeckel "Cyclic";
BA_ "GenSigSendType" SG_ 1500 VL1_Rearview "Cyclic";
BA_ "GenSigSendType" SG_ 1500 VL1_Sonderfzg_SG "Cyclic";
BA_ "GenSigSendType" SG_ 1500 VL1_Tastenmodul "Cyclic";
BA_ "GenSigSendType" SG_ 1500 VL1_Kompass "Cyclic";
BA_ "GenSigSendType" SG_ 1500 VL1_WFS_K "Cyclic";
BA_ "GenSigSendType" SG_ 1500 VL1_GSM_Pager "Cyclic";
BA_ "GenSigSendType" SG_ 1500 VL1_InfoElektronik "Cyclic";
BA_ "GenSigSendType" SG_ 1500 VL1_DSP "Cyclic";
BA_ "GenSigSendType" SG_ 1500 VL1_DAB "Cyclic";
BA_ "GenSigSendType" SG_ 1500 VL1_Telematik "Cyclic";
BA_ "GenSigSendType" SG_ 1500 VL1_Navigation "Cyclic";
BA_ "GenSigSendType" SG_ 1500 VL1_TV_Tuner "Cyclic";
BA_ "GenSigSendType" SG_ 1500 VL1_Neigungsmodul_I "Cyclic";
BA_ "GenSigSendType" SG_ 1500 VL1_Radio "Cyclic";
BA_ "GenSigSendType" SG_ 1500 VL1_Telefon "Cyclic";
BA_ "GenMsgSendType" BO_ 1936 "NoMsgSendType";
BA_ "GenSigSendType" SG_ 1936 TPDyn_ABS_1 "OnChange";
BA_ "GenMsgSendType" BO_ 512 "NoMsgSendType";
BA_ "GenSigSendType" SG_ 512 Tester_TP_Er "OnChange";
BA_ "GenMsgCycleTime" BO_ 80 20;
BA_ "GenMsgSendType" BO_ 80 "Cyclic";
BA_ "GenSigSendType" SG_ 80 AB1_Front "OnChange";
BA_ "GenSigSendType" SG_ 80 AB1_Heck "OnChange";
BA_ "GenSigSendType" SG_ 80 AB1_Fa_Seite "OnChange";
BA_ "GenSigSendType" SG_ 80 AB1_Bf_Seite "OnChange";
BA_ "GenSigSendType" SG_ 80 AB1_Rollover "OnChange";
BA_ "GenSigSendType" SG_ 80 AB1_Gurt_Fa "Cyclic";
BA_ "GenSigSendType" SG_ 80 AB1_Zaehler "Cyclic";
BA_ "GenSigSendType" SG_ 80 AB1_Checksumme "Cyclic";
BA_ "GenSigSendType" SG_ 80 AB1_Intens "OnChangeAndIfActive";
BA_ "GenSigSendType" SG_ 80 AB1_Lampe "Cyclic";
BA_ "GenSigSendType" SG_ 80 AB1_Status "Cyclic";
BA_ "GenSigSendType" SG_ 80 AB1_Beifahrer "Cyclic";
BA_ "GenSigSendType" SG_ 80 AB1_System "Cyclic";
BA_ "GenSigSendType" SG_ 80 AB1_Gurt_Bf "Cyclic";
BA_ "GenSigSendType" SG_ 80 AB1_Diagnose "Cyclic";
BA_ "GenSigSendType" SG_ 80 AB1_Stellglied "Cyclic";
BA_ "GenSigSendType" SG_ 80 AB1_BF_Warnung "Cyclic";
BA_ "GenSigSendType" SG_ 80 AB1_Fehlereintr "Cyclic";
BA_ "GenMsgCycleTime" BO_ 704 10;
BA_ "GenMsgSendType" BO_ 704 "Cyclic";
BA_ "GenSigSendType" SG_ 704 AL1_Fehler "Cyclic";
BA_ "GenSigSendType" SG_ 704 AL1_Uebertemp "Cyclic";
BA_ "GenSigSendType" SG_ 704 AL1_Sta_Kup "Cyclic";
BA_ "GenSigSendType" SG_ 704 AL1_Kup_offen "Cyclic";
BA_ "GenSigSendType" SG_ 704 AL1_Notlauf "Cyclic";
BA_ "GenSigSendType" SG_ 704 AL1_Warnlampe "Cyclic";
BA_ "GenSigSendType" SG_ 704 AL1_Einheit "Cyclic";
BA_ "GenSigSendType" SG_ 704 AL1_Ist_Nm "NoSigSendType";
BA_ "GenSigSendType" SG_ 704 AL1_Ist_Proz "NoSigSendType";
BA_ "GenSigSendType" SG_ 704 AL1_Zaehler "Cyclic";
BA_ "GenSigSendType" SG_ 704 AL1_Limiter "Cyclic";
BA_ "GenSigSendType" SG_ 704 AL1_Sta_PNG "Cyclic";
BA_ "GenSigSendType" SG_ 704 AL1_Anz_blinken "Cyclic";
BA_ "GenSigSendType" SG_ 704 AL1_Sta_Laengssp "Cyclic";
BA_ "GenSigSendType" SG_ 704 AL1_Sta_Quersp "Cyclic";
BA_ "GenSigSendType" SG_ 704 AL1_Schalten "Cyclic";
BA_ "GenSigSendType" SG_ 704 AL1_Vorwarnung "Cyclic";
BA_ "GenSigSendType" SG_ 704 AL1_Stellung_Getr "Cyclic";
BA_ "GenSigSendType" SG_ 704 AL1_AnfVerteiler "Cyclic";
BA_ "GenSigSendType" SG_ 704 AL1_Sta_VA "Cyclic";
BA_ "GenSigSendType" SG_ 704 AL1_KupSteifig_F "Cyclic";
BA_ "GenSigSendType" SG_ 704 AL1_Fehlereintr "Cyclic";
BA_ "GenSigSendType" SG_ 704 AL1_KupplTemp "Cyclic";
BA_ "GenSigSendType" SG_ 704 AL1_FaWu_Laengs "Cyclic";
BA_ "GenSigSendType" SG_ 704 AL1_FaWu_HA "Cyclic";
BA_ "GenSigSendType" SG_ 704 AL1_FaWu_VA "Cyclic";
BA_ "GenSigSendType" SG_ 704 AL1_Quersp_Sta "Cyclic";
BA_ "GenSigSendType" SG_ 704 AL1_Limit_maxkmh "Cyclic";
BA_ "GenSigSendType" SG_ 704 AL1_Diff_Verbau "Cyclic";
BA_ "GenSigSendType" SG_ 704 AL1_Diff_Lampe "Cyclic";
BA_ "GenSigSendType" SG_ 704 AL1_Diff_Gong "Cyclic";
BA_ "GenSigSendType" SG_ 704 AL1_Warnton "Cyclic";
BA_ "GenMsgCycleTime" BO_ 870 40;
BA_ "GenMsgSendType" BO_ 870 "Cyclic";
BA_ "GenSigSendType" SG_ 870 AWV_Checksumme "Cyclic";
BA_ "GenSigSendType" SG_ 870 AWV_Zaehler "Cyclic";
BA_ "GenSigSendType" SG_ 870 AWV_1_Freigabe "Cyclic";
BA_ "GenSigSendType" SG_ 870 AWV_1_Prefill "Cyclic";
BA_ "GenSigSendType" SG_ 870 AWV_1_Parameter "Cyclic";
BA_ "GenSigSendType" SG_ 870 AWV_2_Freigabe "Cyclic";
BA_ "GenSigSendType" SG_ 870 AWV_2_Ruckprofil "Cyclic";
BA_ "GenSigSendType" SG_ 870 AWV_Text "Cyclic";
BA_ "GenSigSendType" SG_ 870 AWV_CityANB_Auspraegung "Cyclic";
BA_ "GenSigSendType" SG_ 870 AWV_2_Status "Cyclic";
BA_ "GenSigSendType" SG_ 870 AWV_2_Fehler "Cyclic";
BA_ "GenSigSendType" SG_ 870 AWV_2_SU_Warnzeit "Cyclic";
BA_ "GenSigSendType" SG_ 870 AWV_2_SU_Bremsruck "Cyclic";
BA_ "GenSigSendType" SG_ 870 AWV_2_SU_Gong "Cyclic";
BA_ "GenSigSendType" SG_ 870 AWV_2_SU_Lampe "Cyclic";
BA_ "GenSigSendType" SG_ 870 AWV_2_Umfeldwarn "Cyclic";
BA_ "GenSigSendType" SG_ 870 AWV_2_Warnton "Cyclic";
BA_ "GenSigSendType" SG_ 870 AWV_2_Warnsymbol "Cyclic";
BA_ "GenSigSendType" SG_ 870 AWV_Infoton "Cyclic";
BA_ "GenSigSendType" SG_ 870 AWV_2_Gurtstraffer "Cyclic";
BA_ "GenSigSendType" SG_ 870 AWV_Konfiguration_Menueanf "Cyclic";
BA_ "GenSigSendType" SG_ 870 AWV_Konfiguration_Vorw_Menueanf "Cyclic";
BA_ "GenSigSendType" SG_ 870 AWV_Konfiguration_Status "Cyclic";
BA_ "GenSigSendType" SG_ 870 AWV_Konfiguration_Vorw_Status "Cyclic";
BA_ "GenSigSendType" SG_ 870 AWV_2_Abstandswarnung "Cyclic";
BA_ "GenSigSendType" SG_ 870 AWV_only "Cyclic";
BA_ "GenSigSendType" SG_ 870 AWV_Halten "Cyclic";
BA_ "GenSigSendType" SG_ 870 ANB_Teilbremsung_Freigabe "IfActive";
BA_ "GenSigSendType" SG_ 870 ANB_Zielbremsung_Freigabe "Cyclic";
BA_ "GenSigSendType" SG_ 870 ANB_CM_Anforderung "Cyclic";
BA_ "GenSigSendType" SG_ 870 ANB_Ziel_Teilbrems_Verz_Anf "Cyclic";
BA_ "GenMsgCycleTime" BO_ 1392 100;
BA_ "GenMsgSendType" BO_ 1392 "Cyclic";
BA_ "GenSigSendType" SG_ 1392 BSL_ZAS_Kl_15 "OnChange";
BA_ "GenSigSendType" SG_ 1392 BSL_BSG_3_alt "Cyclic";
BA_ "GenSigSendType" SG_ 1392 BSL_Starterlaubnis "OnChange";
BA_ "GenSigSendType" SG_ 1392 BSL_Parklicht "Cyclic";
BA_ "GenSigSendType" SG_ 1392 BSL_LL_Anheb2 "Cyclic";
BA_ "GenSigSendType" SG_ 1392 BSL_Kl_15_Motor "Cyclic";
BA_ "GenSigSendType" SG_ 1392 BSL_Kl_L "Cyclic";
BA_ "GenSigSendType" SG_ 1392 BSL_LL_Anheb "Cyclic";
BA_ "GenSigSendType" SG_ 1392 BSL_Sta_StBat "Cyclic";
BA_ "GenSigSendType" SG_ 1392 BSL_Fehlereintr "Cyclic";
BA_ "GenSigSendType" SG_ 1392 BSL_Sta_LWR "Cyclic";
BA_ "GenSigSendType" SG_ 1392 BSL_Motor_Haube "Cyclic";
BA_ "GenSigSendType" SG_ 1392 BSL_Hecksch "Cyclic";
BA_ "GenSigSendType" SG_ 1392 BSL_Frontsch "Cyclic";
BA_ "GenSigSendType" SG_ 1392 BSL_Aussensp "Cyclic";
BA_ "GenSigSendType" SG_ 1392 BSL_Sitzheiz "Cyclic";
BA_ "GenSigSendType" SG_ 1392 BSL_Lenkradheiz "Cyclic";
BA_ "GenSigSendType" SG_ 1392 BSL_Wasserheiz "Cyclic";
BA_ "GenSigSendType" SG_ 1392 BSL_Sitzbelueft "Cyclic";
BA_ "GenSigSendType" SG_ 1392 BSL_Clima "Cyclic";
BA_ "GenSigSendType" SG_ 1392 BSL_BSG_2_alt "Cyclic";
BA_ "GenSigSendType" SG_ 1392 BSL_Kuehlerlueft "Cyclic";
BA_ "GenSigSendType" SG_ 1392 BSL_Ab_Batterie "Cyclic";
BA_ "GenSigSendType" SG_ 1392 BSL_Weckursache_ACAN "Cyclic";
BA_ "GenSigSendType" SG_ 1392 BSL_Wake_Up_ACAN "Cyclic";
BA_ "GenSigSendType" SG_ 1392 BSL_ZAS_Kl_S "Cyclic";
BA_ "GenSigSendType" SG_ 1392 BSL_ZAS_Kl_X "OnChange";
BA_ "GenSigSendType" SG_ 1392 BSL_ZAS_Kl_50 "OnChange";
BA_ "GenSigSendType" SG_ 1392 BSL_Sta_UBat "Cyclic";
BA_ "GenSigSendType" SG_ 1392 BSL_UBat "Cyclic";
BA_ "GenMsgCycleTime" BO_ 2000 1000;
BA_ "GenMsgSendType" BO_ 2000 "Cyclic";
BA_ "GenSigSendType" SG_ 2000 DI1_VerlernZaehl "Cyclic";
BA_ "GenSigSendType" SG_ 2000 DI1_km_Stand "Cyclic";
BA_ "GenSigSendType" SG_ 2000 DI1_Jahr "Cyclic";
BA_ "GenSigSendType" SG_ 2000 DI1_Monat "Cyclic";
BA_ "GenSigSendType" SG_ 2000 DI1_Tag "Cyclic";
BA_ "GenSigSendType" SG_ 2000 DI1_Stunde "Cyclic";
BA_ "GenSigSendType" SG_ 2000 DI1_Minute "Cyclic";
BA_ "GenSigSendType" SG_ 2000 DI1_Sekunde "Cyclic";
BA_ "GenSigSendType" SG_ 2000 DI1_KM_Stand_alt "Cyclic";
BA_ "GenSigSendType" SG_ 2000 DI1_Zeit_alt "Cyclic";
BA_ "GenMsgCycleTime" BO_ 1088 10;
BA_ "GenMsgSendType" BO_ 1088 "Cyclic";
BA_ "GenSigSendType" SG_ 1088 GE1_Schaltung "Cyclic";
BA_ "GenSigSendType" SG_ 1088 GE1_Zielgang "Cyclic";
BA_ "GenSigSendType" SG_ 1088 GE1_Wahl_Pos "Cyclic";
BA_ "GenSigSendType" SG_ 1088 GE1_Mrad_Mkurb "Cyclic";
BA_ "GenSigSendType" SG_ 1088 GE1_Notlauf "Cyclic";
BA_ "GenSigSendType" SG_ 1088 GE1_Zaehler "Cyclic";
BA_ "GenSigSendType" SG_ 1088 GE1_Sta_Schutz "Cyclic";
BA_ "GenSigSendType" SG_ 1088 GE1_Klimakompr "Cyclic";
BA_ "GenSigSendType" SG_ 1088 GE1_WK "Cyclic";
BA_ "GenSigSendType" SG_ 1088 GE1_StSt_Info "Cyclic";
BA_ "GenSigSendType" SG_ 1088 GE1_EGS_Anf "Cyclic";
BA_ "GenSigSendType" SG_ 1088 GE1_Soll_Mo "Cyclic";
BA_ "GenSigSendType" SG_ 1088 GE1_Fahrwistd "Cyclic";
BA_ "GenSigSendType" SG_ 1088 GE1_Kuehlung "Cyclic";
BA_ "GenSigSendType" SG_ 1088 GE1_Sta_OBD "Cyclic";
BA_ "GenSigSendType" SG_ 1088 GE1_LaunchControl "Cyclic";
BA_ "GenSigSendType" SG_ 1088 GE1_Infobit "Cyclic";
BA_ "GenSigSendType" SG_ 1088 GE1_SleepInd "Cyclic";
BA_ "GenSigSendType" SG_ 1088 GE1_Fehlereintr "Cyclic";
BA_ "GenSigSendType" SG_ 1088 GE1_WaVerl_Mo "Cyclic";
BA_ "GenMsgCycleTime" BO_ 1490 200;
BA_ "GenMsgSendType" BO_ 1490 "Cyclic";
BA_ "GenSigSendType" SG_ 1490 IDT_Mux "Cyclic";
BA_ "GenSigSendType" SG_ 1490 IDT_VIN_13 "NoSigSendType";
BA_ "GenSigSendType" SG_ 1490 IDT_VIN_14 "NoSigSendType";
BA_ "GenSigSendType" SG_ 1490 IDT_VIN_15 "NoSigSendType";
BA_ "GenSigSendType" SG_ 1490 IDT_VIN_16 "NoSigSendType";
BA_ "GenSigSendType" SG_ 1490 IDT_VIN_17 "NoSigSendType";
BA_ "GenSigSendType" SG_ 1490 IDT_Geheimnis_1 "NoSigSendType";
BA_ "GenSigSendType" SG_ 1490 IDT_VIN_4 "NoSigSendType";
BA_ "GenSigSendType" SG_ 1490 IDT_VIN_11 "NoSigSendType";
BA_ "GenSigSendType" SG_ 1490 IDT_Geheimnis_2 "NoSigSendType";
BA_ "GenSigSendType" SG_ 1490 IDT_VIN_5 "NoSigSendType";
BA_ "GenSigSendType" SG_ 1490 IDT_VIN_12 "NoSigSendType";
BA_ "GenSigSendType" SG_ 1490 IDT_Geheimnis_3 "NoSigSendType";
BA_ "GenSigSendType" SG_ 1490 IDT_VIN_6 "NoSigSendType";
BA_ "GenSigSendType" SG_ 1490 IDT_Geheimnis_4 "NoSigSendType";
BA_ "GenSigSendType" SG_ 1490 IDT_VIN_1 "NoSigSendType";
BA_ "GenSigSendType" SG_ 1490 IDT_VIN_2 "NoSigSendType";
BA_ "GenSigSendType" SG_ 1490 IDT_VIN_9 "NoSigSendType";
BA_ "GenSigSendType" SG_ 1490 IDT_VIN_3 "NoSigSendType";
BA_ "GenSigSendType" SG_ 1490 IDT_VIN_10 "NoSigSendType";
BA_ "GenSigSendType" SG_ 1490 IDT_VIN_7 "NoSigSendType";
BA_ "GenSigSendType" SG_ 1490 IDT_VIN_8 "NoSigSendType";
BA_ "GenMsgCycleTime" BO_ 1056 200;
BA_ "GenMsgSendType" BO_ 1056 "Cyclic";
BA_ "GenSigSendType" SG_ 1056 KO2_gef_Auss_T "Cyclic";
BA_ "GenSigSendType" SG_ 1056 KO2_Verb_TOG "Cyclic";
BA_ "GenSigSendType" SG_ 1056 KO2_Oelwarn "Cyclic";
BA_ "GenSigSendType" SG_ 1056 KO2_GRA_High "Cyclic";
BA_ "GenSigSendType" SG_ 1056 KO2_Temp_Einheit "Cyclic";
BA_ "GenSigSendType" SG_ 1056 KO2_Wischwasser "Cyclic";
BA_ "GenSigSendType" SG_ 1056 KO2_PLA_Displaystatus "Cyclic";
BA_ "GenSigSendType" SG_ 1056 KO2_Fehlereintr "Cyclic";
BA_ "GenSigSendType" SG_ 1056 KO2_Aussen_T "Cyclic";
BA_ "GenSigSendType" SG_ 1056 KBI_Anzeigestatus_LIM "Cyclic";
BA_ "GenSigSendType" SG_ 1056 KO_AWV_Zustandswechsel "Cyclic";
BA_ "GenSigSendType" SG_ 1056 KO_AWV_Vorw_Zustandswechsel "Cyclic";
BA_ "GenSigSendType" SG_ 1056 KO_Aussensound_Zustandswechsel "Cyclic";
BA_ "GenSigSendType" SG_ 1056 KB2_EasyEntry "Cyclic";
BA_ "GenSigSendType" SG_ 1056 KO_Segeln_Menuestatus "Cyclic";
BA_ "GenSigSendType" SG_ 1056 KO_Segeln_Zustandswechsel "Cyclic";
BA_ "GenSigSendType" SG_ 1056 KB2_Auto_eKiSi "Cyclic";
BA_ "GenSigSendType" SG_ 1056 KO2_Bel_Displ "Cyclic";
BA_ "GenSigSendType" SG_ 1056 KO2_Sta_Displ "Cyclic";
BA_ "GenSigSendType" SG_ 1056 KO2_Bel_Schalt "Cyclic";
BA_ "GenSigSendType" SG_ 1056 KO2_Sta_Schalt "Cyclic";
BA_ "GenSigSendType" SG_ 1056 KO2_MFA_v_Einheit "Cyclic";
BA_ "GenSigSendType" SG_ 1056 KO2_Passiv_Autolock "Cyclic";
BA_ "GenSigSendType" SG_ 1056 KO2_WFS_Schl_Ort "Cyclic";
BA_ "GenSigSendType" SG_ 1056 KB2_MFA_Strecke_Einheit "Cyclic";
BA_ "GenSigSendType" SG_ 1056 KO2_OBD_Nib_Temp "Cyclic";
BA_ "GenSigSendType" SG_ 1056 KO2_Sta_Auss_T "Cyclic";
BA_ "GenSigSendType" SG_ 1056 KBI_rotes_P_verbaut "Cyclic";
BA_ "GenSigSendType" SG_ 1056 KB2_Req_IstZu_Solldruecke "Cyclic";
BA_ "GenMsgCycleTime" BO_ 1312 200;
BA_ "GenMsgSendType" BO_ 1312 "Cyclic";
BA_ "GenSigSendType" SG_ 1312 KO3_Radumfang "NoSigSendType";
BA_ "GenSigSendType" SG_ 1312 KO3_Land "NoSigSendType";
BA_ "GenSigSendType" SG_ 1312 KO3_Mp_Code "Cyclic";
BA_ "GenSigSendType" SG_ 1312 KO3_Um_AutoHold "Cyclic";
BA_ "GenSigSendType" SG_ 1312 KO3_Standzeit "Cyclic";
BA_ "GenSigSendType" SG_ 1312 KO3_Sprache "NoSigSendType";
BA_ "GenSigSendType" SG_ 1312 KO3_Derivat "NoSigSendType";
BA_ "GenSigSendType" SG_ 1312 KO3_Verbau_Mot "NoSigSendType";
BA_ "GenSigSendType" SG_ 1312 KO3_Verbau_Get "NoSigSendType";
BA_ "GenSigSendType" SG_ 1312 KO3_Verbau_Br "NoSigSendType";
BA_ "GenSigSendType" SG_ 1312 KO3_Verbau_Kl "NoSigSendType";
BA_ "GenSigSendType" SG_ 1312 KO3_Generation "NoSigSendType";
BA_ "GenSigSendType" SG_ 1312 KO3_Verbau_Air "NoSigSendType";
BA_ "GenSigSendType" SG_ 1312 KO3_Verbau_ADR "NoSigSendType";
BA_ "GenSigSendType" SG_ 1312 KO3_Verbau_BN "NoSigSendType";
BA_ "GenSigSendType" SG_ 1312 KO3_Verbau_Syn "NoSigSendType";
BA_ "GenSigSendType" SG_ 1312 KO3_Baureihe "NoSigSendType";
BA_ "GenSigSendType" SG_ 1312 KO3_Verbau_LWS "NoSigSendType";
BA_ "GenSigSendType" SG_ 1312 KO3_Verbau_DP "NoSigSendType";
BA_ "GenSigSendType" SG_ 1312 KO3_Verbau_LH "NoSigSendType";
BA_ "GenSigSendType" SG_ 1312 KO3_Marke "NoSigSendType";
BA_ "GenSigSendType" SG_ 1312 KO3_Verbau_Niveau "NoSigSendType";
BA_ "GenSigSendType" SG_ 1312 KBI_Oelwechsel_durchgefuehrt "Cyclic";
BA_ "GenSigSendType" SG_ 1312 KO3_Schluessel "Cyclic";
BA_ "GenSigSendType" SG_ 1312 KO3_Um_AFS2 "Cyclic";
BA_ "GenSigSendType" SG_ 1312 KO3_Um_Tourist "Cyclic";
BA_ "GenSigSendType" SG_ 1312 KO3_SWA_AnzFeh "Cyclic";
BA_ "GenSigSendType" SG_ 1312 KO3_Sta_Standz "Cyclic";
BA_ "GenSigSendType" SG_ 1312 KO3_Kilometer "Cyclic";
BA_ "GenMsgCycleTime" BO_ 978 50;
BA_ "GenMsgSendType" BO_ 978 "Cyclic";
BA_ "GenSigSendType" SG_ 978 LH2_Checksumme "Cyclic";
BA_ "GenSigSendType" SG_ 978 LH2_Zaehler "Cyclic";
BA_ "GenSigSendType" SG_ 978 LH2_StatEPS_PLA "Cyclic";
BA_ "GenSigSendType" SG_ 978 LH2_Geradeaus "Cyclic";
BA_ "GenSigSendType" SG_ 978 LH2_Sta_Charisma "Cyclic";
BA_ "GenSigSendType" SG_ 978 LH2_Sta_HCA "Cyclic";
BA_ "GenSigSendType" SG_ 978 LH2_Ausg_LW1 "Cyclic";
BA_ "GenSigSendType" SG_ 978 LH2_Ausg_LW1_gue "Cyclic";
BA_ "GenSigSendType" SG_ 978 LH2_aktLenkeingriff "Cyclic";
BA_ "GenSigSendType" SG_ 978 LH2_PLA_Err "Cyclic";
BA_ "GenSigSendType" SG_ 978 LH2_PLA_Abbr "Cyclic";
BA_ "GenMsgCycleTime" BO_ 208 10;
BA_ "GenMsgSendType" BO_ 208 "Cyclic";
BA_ "GenSigSendType" SG_ 208 LH3_Checksumme "Cyclic";
BA_ "GenSigSendType" SG_ 208 LH3_Zaehler "Cyclic";
BA_ "GenSigSendType" SG_ 208 LH3_LM "Cyclic";
BA_ "GenSigSendType" SG_ 208 LH3_LMSign "Cyclic";
BA_ "GenSigSendType" SG_ 208 LH3_LMValid "Cyclic";
BA_ "GenSigSendType" SG_ 208 LH3_Sta_DSR "Cyclic";
BA_ "GenSigSendType" SG_ 208 LH3_BLW "Cyclic";
BA_ "GenSigSendType" SG_ 208 LH3_BLWSign "Cyclic";
BA_ "GenSigSendType" SG_ 208 LH3_BLWValid "Cyclic";
BA_ "GenSigSendType" SG_ 208 LH3_Lenkungstyp "Cyclic";
BA_ "GenSigSendType" SG_ 208 LH3_BS_Spiegel "Cyclic";
BA_ "GenMsgCycleTime" BO_ 640 10;
BA_ "GenMsgSendType" BO_ 640 "Cyclic";
BA_ "GenSigSendType" SG_ 640 MO1_Kup_schalt "Cyclic";
BA_ "GenSigSendType" SG_ 640 MO1_TiOut_Br "Cyclic";
BA_ "GenSigSendType" SG_ 640 MO1_Sta_Bremse "Cyclic";
BA_ "GenSigSendType" SG_ 640 MO1_Sta_MotMo "Cyclic";
BA_ "GenSigSendType" SG_ 640 MO1_Mo_m_ex "Cyclic";
BA_ "GenSigSendType" SG_ 640 MO1_Drehzahl "Cyclic";
BA_ "GenSigSendType" SG_ 640 MO1_Pedalwert "Cyclic";
BA_ "GenSigSendType" SG_ 640 MO1_Verlustmo "Cyclic";
BA_ "GenSigSendType" SG_ 640 MO1_Wunschmo "Cyclic";
BA_ "GenSigSendType" SG_ 640 MO1_Leergas "Cyclic";
BA_ "GenSigSendType" SG_ 640 MO1_Sta_Pedal "Cyclic";
BA_ "GenSigSendType" SG_ 640 MO1_Kickdown "Cyclic";
BA_ "GenSigSendType" SG_ 640 MO1_Sta_Getr "Cyclic";
BA_ "GenSigSendType" SG_ 640 MO1_Mo_o_ex "Cyclic";
BA_ "GenMsgCycleTime" BO_ 648 20;
BA_ "GenMsgSendType" BO_ 648 "Cyclic";
BA_ "GenSigSendType" SG_ 648 MO2_Getr_Code "NoSigSendType";
BA_ "GenSigSendType" SG_ 648 MO2_max_Mo "NoSigSendType";
BA_ "GenSigSendType" SG_ 648 MO2_Mp_Code "Cyclic";
BA_ "GenSigSendType" SG_ 648 MO2_BLS "Cyclic";
BA_ "GenSigSendType" SG_ 648 MO2_Sta_No_Bet "Cyclic";
BA_ "GenSigSendType" SG_ 648 MO2_Sta_GRA "Cyclic";
BA_ "GenSigSendType" SG_ 648 MO2_OffRoad "Cyclic";
BA_ "GenSigSendType" SG_ 648 MO2_LL_Solldz "Cyclic";
BA_ "GenSigSendType" SG_ 648 MO2_CAN_Vers "NoSigSendType";
BA_ "GenSigSendType" SG_ 648 MO2_Kuehlm_T "Cyclic";
BA_ "GenSigSendType" SG_ 648 MO2_BTS "Cyclic";
BA_ "GenSigSendType" SG_ 648 MO2_Sta_Kuehlm "Cyclic";
BA_ "GenSigSendType" SG_ 648 MO2_Sta_Klima "Cyclic";
BA_ "GenSigSendType" SG_ 648 MO2_Status_TSK "Cyclic";
BA_ "GenSigSendType" SG_ 648 TSK_Limiter_ausgewaehlt "Cyclic";
BA_ "GenSigSendType" SG_ 648 MO2_GRAregelt "Cyclic";
BA_ "GenSigSendType" SG_ 648 MO2_Sport_Error "Cyclic";
BA_ "GenSigSendType" SG_ 648 MO2_RME_Gehalt "Cyclic";
BA_ "GenSigSendType" SG_ 648 MO2_GRA_Soll "Cyclic";
BA_ "GenSigSendType" SG_ 648 MO2_Begr_Mo "Cyclic";
BA_ "GenSigSendType" SG_ 648 MO2_Mo_ZWR "Cyclic";
BA_ "GenSigSendType" SG_ 648 MO2_Motor_Code "NoSigSendType";
BA_ "GenMsgCycleTime" BO_ 896 10;
BA_ "GenMsgSendType" BO_ 896 "Cyclic";
BA_ "GenSigSendType" SG_ 896 MO3_Pedalwert "Cyclic";
BA_ "GenSigSendType" SG_ 896 MO3_Vorgluehen "Cyclic";
BA_ "GenSigSendType" SG_ 896 MO3_Prio_Dz "Cyclic";
BA_ "GenSigSendType" SG_ 896 MO_Schalter_StartStopp "Cyclic";
BA_ "GenSigSendType" SG_ 896 MO3_Winterprg "Cyclic";
BA_ "GenSigSendType" SG_ 896 MO3_Sta_FPG "Cyclic";
BA_ "GenSigSendType" SG_ 896 MO3_Sign_FPG "NoSigSendType";
BA_ "GenSigSendType" SG_ 896 MO3_Sta_Temp "Cyclic";
BA_ "GenSigSendType" SG_ 896 MO3_Aussentemp "Cyclic";
BA_ "GenSigSendType" SG_ 896 MO3_Rad_Wu_Mo "Cyclic";
BA_ "GenSigSendType" SG_ 896 MO3_Vorz_RadWu "Cyclic";
BA_ "GenSigSendType" SG_ 896 MO3_Freigabe_Segeln "Cyclic";
BA_ "GenSigSendType" SG_ 896 MO_StartStopp_StoppVorbereitung "Cyclic";
BA_ "GenSigSendType" SG_ 896 MO3_Dz_Beeinfl "Cyclic";
BA_ "GenSigSendType" SG_ 896 MO3_WunschDz "Cyclic";
BA_ "GenSigSendType" SG_ 896 MO3_DKW "NoSigSendType";
BA_ "GenSigSendType" SG_ 896 MO3_FPGradient "NoSigSendType";
BA_ "GenSigSendType" SG_ 896 MO3_Sta_Pedal "Cyclic";
VAL_ 1494 PLS_Bremsleuchte 1 "Bremsleuchte_ein" 0 "Bremsleuchte_aus" ;
VAL_ 1494 PLS_Anf_Anz 1 "Anzeige_Anforderung" 0 "keine_Anforderung" ;
VAL_ 1494 PLS_Akustik1 1 "Akustik" 0 "keine_Akustik" ;
VAL_ 1494 PLS_PL_Exist 1 "Parkluecke" 0 "keine_Parkluecke" ;
VAL_ 1494 PLS_Akustik2 1 "Akustik" 0 "keine_Akustik" ;
VAL_ 1494 PLS_Mehrzg_Aktiv 1 "aktiv" 0 "nicht_aktiv" ;
VAL_ 1494 PLS_Pos_OK 1 "Pos_OK" 0 "Pos_NOK" ;
VAL_ 1494 PLS_PL_Seite 1 "links" 0 "rechts" ;
VAL_ 1494 PLS_Lenk_Aktiv_Hinweis 1 "Lenkeingriff_aktiv" 0 "keine_Info" ;
VAL_ 1494 PLS_Meldungen 0 "kein_Text" ;
VAL_ 1494 PLS_Fahrtrichtg_Mehrzg 1 "Rueckwaerts" 0 "Vorwaerts" ;
VAL_ 1494 PLS_Text_Multiplexer 3 "Textmeldungen_aus_3" 2 "Textmeldungen_aus_2" 1 "Textmeldungen_aus_1" 0 "Init_keine_Anzeige" ;
VAL_ 1494 PLS_Schwellpfeil_rel 15 "15_Segmente_voll" 14 "14_Segmente" 13 "13_Segmente" 12 "12_Segmente" 11 "11_Segmente" 10 "10_Segmente" 9 "9_Segmente" 8 "8_Segmente" 7 "7_Segmente" 6 "6_Segmente" 5 "5_Segmente" 4 "4_Segmente" 3 "3_Segmente" 2 "2_Segmente" 1 "1_Segment" 0 "kein_Segment_leer" ;
VAL_ 1494 PLS_Anf_Anz_Schwellpfeil 1 "Anzeige_Schwellpfeil_ein" 0 "Anzeige_Schwellpfeil_aus" ;
VAL_ 1494 PLS_Laengs_Querluecke 1 "Querluecke" 0 "Laengsluecke" ;
VAL_ 1494 PLS_Standby 1 "Anzeige_des_Standby_Symbols" 0 "keine_Anzeige" ;
VAL_ 1494 PLS_Bremssymbol 1 "Anzeige_Bremssymbol" 0 "keine_Anzeige" ;
VAL_ 1494 PLS_Kurze_Luecke 1 "Kurze_Luecke" 0 "keine_Kurze_Luecke" ;
VAL_ 1494 PLS_Schwellpfeil_abs 3 "kein_Segment" 2 "1_Segment" 1 "2_Segmente" 0 "3_Segmente__voll" ;
VAL_ 1494 PLS_Akustik 3 "Akustik_3" 2 "Akustik_2" 1 "Akustik_1" 0 "keine_Akustik" ;
VAL_ 1494 PLS_Ausparken_Aktiv 1 "Ausparkfunktion_aktiv" 0 "Ausparken_nicht_aktiv" ;
VAL_ 1494 PLS_Texte 32 "Dauertonbereich veraendert, besondere Vorsicht geboten" 31 "Park Assist beendet. Lenkung uebernehmen." 30 "Achtung! Seitliches Hindernis! (Flankenschutz)" 29 "Achtung! Bremse oeffnet" 28 "Hindernis erkannt, bitte Bremse betaetigen" 27 "Park Assist: Bremseingriff! Geschwindigkeit zu hoch (bei aktiviertem Lenkeingriff mit Bremseingriff)" 26 "Automatisches Ausparken nicht moeglich, Luecke zu klein (bei aktivem Lenkeingriff)" 25 "Bitte Lenkung uebernehmen und Fahrt fortsetzen (Ausparken beendet)" 24 "Park Assist deaktiviert, defekt, (bei aktiviertem Lenkeingriff)" 23 "Park Assist deaktiviert, Systemstoerung (bei aktiviertem Lenkeingriff)" 22 "Park Assist deaktiviert, Eingriff ASR, Lenkung uebernehmen" 21 "Park Assist deaktiviert, Geschwindigkeit zu hoch, Lenkung uebernehmen (bei aktiviertem Lenkeingriff ohne Bremseingriff)" 20 "Park Assist deaktiviert, Lenkung uebernehmen, Parkvorgang manuell beenden (wenn Fzg. noch schraeg steht)" 19 "Lenkeingriff deaktiviert, Lenkung uebernehmen" 18 "Park Assist deaktiviert, Zeitlimit ueberschritten Lenkung uebernehmen (bei aktiviertem Lenkeingriff)" 17 "Park Assist deaktiviert, ASR ausgeschaltet, Lenkung uebernehmen (bei aktiviertem Lenkeingriff)" 16 "Park Assist deaktiviert, Anhaenger (bei aktiviertem Lenkeingriff)" 15 "Park Assist deaktiviert, Lenkung uebernehmen!" 14 "Park Assist beendet. Geschwindigkeit zu hoch." 13 "Geschwindigkeit zu hoch (bei aktivem Lenkeingriff)" 12 "Automatisches Ausparken nicht moeglich, Luecke zu klein" 11 "Blinker setzen und Rueckwaertsgang einlegen (Ausparkfunktion)" 10 "Geschwindigkeit zu niedrig" 9 "Stillstandszeit nicht ausreichend" 8 "Park Assist deaktiviert, defekt ohne aktiviertem Lenkeingriff" 7 "Park Assist deaktiviert, Systemstoerung ohne aktiviertem Lenkeingriff" 6 "Park Assist deaktiviert, Zeitlimit ueberschritten" 5 "Park Assist deaktiviert, Anhaenger vorhanden ohne aktiviertem Lenkeingriff" 4 "Park Assist deaktiviert, ASR ausgeschaltet" 3 "Park Assist deaktiviert, Eingriff ASR ohne aktiviertem Lenkeingriff" 2 "Park Assist deaktiviert, Geschwindigkeit zu hoch" 1 "Park Assist deaktiviert (Funktion ohne vorherigem Lenkeingriff regulaer beendet)" 0 "keine_Meldung" ;
VAL_ 1500 VL1_Motor_SG 1 "Sollverbau" 0 "kein_Sollverbau" ;
VAL_ 1500 VL1_Getr_SG 1 "Sollverbau" 0 "kein_Sollverbau" ;
VAL_ 1500 VL1_LSM 1 "Sollverbau" 0 "kein_Sollverbau" ;
VAL_ 1500 VL1_Airbag 1 "Sollverbau" 0 "kein_Sollverbau" ;
VAL_ 1500 VL1_Allrad 1 "Sollverbau" 0 "kein_Sollverbau" ;
VAL_ 1500 VL1_ADR 1 "Sollverbau" 0 "kein_Sollverbau" ;
VAL_ 1500 VL1_Anhaenger 1 "Sollverbau" 0 "kein_Sollverbau" ;
VAL_ 1500 VL1_ABS 1 "Sollverbau" 0 "kein_Sollverbau" ;
VAL_ 1500 VL1_Kombi 1 "Sollverbau" 0 "kein_Sollverbau" ;
VAL_ 1500 VL1_Lenkhilfe 1 "Sollverbau" 0 "kein_Sollverbau" ;
VAL_ 1500 VL1_dyn_LWR 1 "Sollverbau" 0 "kein_Sollverbau" ;
VAL_ 1500 VL1_res_08 1 "Sollverbau" 0 "kein_Sollverbau" ;
VAL_ 1500 VL1_ADR_getrennt 1 "ADR_getrennt" 0 "ADR_angeschlossen" ;
VAL_ 1500 VL1_EPB 1 "Sollverbau" 0 "kein_Sollverbau" ;
VAL_ 1500 VL1_res_13 1 "Sollverbau" 0 "kein_Sollverbau" ;
VAL_ 1500 VL1_Daempfer 1 "Sollverbau" 0 "kein_Sollverbau" ;
VAL_ 1500 VL1_Quersperre 1 "Sollverbau" 0 "kein_Sollverbau" ;
VAL_ 1500 VL1_MotorSlave 1 "Sollverbau" 0 "kein_Sollverbau" ;
VAL_ 1500 VL1_SWA 1 "Sollverbau" 0 "kein_Sollverbau" ;
VAL_ 1500 VL1_HCA 1 "Sollverbau" 0 "kein_Sollverbau" ;
VAL_ 1500 VL1_RKA_Plus 1 "Sollverbau" 0 "kein_Sollverbau" ;
VAL_ 1500 VL1_PLA 1 "Sollverbau" 0 "kein_Sollverbau" ;
VAL_ 1500 VL1_WFS_KBI 1 "Sollverbau" 0 "kein_Sollverbau" ;
VAL_ 1500 VL1_Kombi_KBI 1 "Sollverbau" 0 "kein_Sollverbau" ;
VAL_ 1500 VL1_Soll_eq_Ist 1 "Sollverbau_gleich_Istverbau" 0 "Sollverbau_ungleich_Istverbau" ;
VAL_ 1500 VL1_BSG_Komf 1 "Sollverbau" 0 "kein_Sollverbau" ;
VAL_ 1500 VL1_ZKE 1 "Sollverbau" 0 "kein_Sollverbau" ;
VAL_ 1500 VL1_TSG_FT 1 "Sollverbau" 0 "kein_Sollverbau" ;
VAL_ 1500 VL1_TSG_BT 1 "Sollverbau" 0 "kein_Sollverbau" ;
VAL_ 1500 VL1_TSG_HL 1 "Sollverbau" 0 "kein_Sollverbau" ;
VAL_ 1500 VL1_TSG_HR 1 "Sollverbau" 0 "kein_Sollverbau" ;
VAL_ 1500 VL1_Memory 1 "Sollverbau" 0 "kein_Sollverbau" ;
VAL_ 1500 VL1_Dachmodul_K 1 "Sollverbau" 0 "kein_Sollverbau" ;
VAL_ 1500 VL1_Zentralelektrik_II 1 "Sollverbau" 0 "kein_Sollverbau" ;
VAL_ 1500 VL1_RDK 1 "Sollverbau" 0 "kein_Sollverbau" ;
VAL_ 1500 VL1_Lenksaeule 1 "Sollverbau" 0 "kein_Sollverbau" ;
VAL_ 1500 VL1_Gateway 1 "Sollverbau" 0 "kein_Sollverbau" ;
VAL_ 1500 VL1_Clima_Komf 1 "Sollverbau" 0 "kein_Sollverbau" ;
VAL_ 1500 VL1_Einparkhilfe 1 "Sollverbau" 0 "kein_Sollverbau" ;
VAL_ 1500 VL1_PTC_Heizung 1 "Sollverbau" 0 "kein_Sollverbau" ;
VAL_ 1500 VL1_Standheiz 1 "Sollverbau" 0 "kein_Sollverbau" ;
VAL_ 1500 VL1_Verdeck 1 "Sollverbau" 0 "kein_Sollverbau" ;
VAL_ 1500 VL1_RSE_I 1 "Sollverbau" 0 "kein_Sollverbau" ;
VAL_ 1500 VL1_res_42 1 "Sollverbau" 0 "kein_Sollverbau" ;
VAL_ 1500 VL1_MDI_I 1 "Sollverbau" 0 "kein_Sollverbau" ;
VAL_ 1500 VL1_Memory_BF 1 "Sollverbau" 0 "kein_Sollverbau" ;
VAL_ 1500 VL1_Easy_Entry_VF 1 "Sollverbau" 0 "kein_Sollverbau" ;
VAL_ 1500 VL1_Easy_Entry_VB 1 "Sollverbau" 0 "kein_Sollverbau" ;
VAL_ 1500 VL1_Heckdeckel 1 "Sollverbau" 0 "kein_Sollverbau" ;
VAL_ 1500 VL1_Rearview 1 "Sollverbau" 0 "kein_Sollverbau" ;
VAL_ 1500 VL1_Sonderfzg_SG 1 "Sollverbau" 0 "kein_Sollverbau" ;
VAL_ 1500 VL1_Tastenmodul 1 "Sollverbau" 0 "kein_Sollverbau" ;
VAL_ 1500 VL1_Kompass 1 "Sollverbau" 0 "kein_Sollverbau" ;
VAL_ 1500 VL1_WFS_K 1 "Sollverbau" 0 "kein_Sollverbau" ;
VAL_ 1500 VL1_GSM_Pager 1 "Sollverbau" 0 "kein_Sollverbau" ;
VAL_ 1500 VL1_InfoElektronik 1 "Sollverbau" 0 "kein_Sollverbau" ;
VAL_ 1500 VL1_DSP 1 "Sollverbau" 0 "kein_Sollverbau" ;
VAL_ 1500 VL1_DAB 1 "Sollverbau" 0 "kein_Sollverbau" ;
VAL_ 1500 VL1_Telematik 1 "Sollverbau" 0 "kein_Sollverbau" ;
VAL_ 1500 VL1_Navigation 1 "Sollverbau" 0 "kein_Sollverbau" ;
VAL_ 1500 VL1_TV_Tuner 1 "Sollverbau" 0 "kein_Sollverbau" ;
VAL_ 1500 VL1_Neigungsmodul_I 1 "Sollverbau" 0 "kein_Sollverbau" ;
VAL_ 1500 VL1_Radio 1 "Sollverbau" 0 "kein_Sollverbau" ;
VAL_ 1500 VL1_Telefon 1 "Sollverbau" 0 "kein_Sollverbau" ;
VAL_ 80 AB1_Front 1 "Front_Crash" 0 "kein_Front_Crash" ;
VAL_ 80 AB1_Heck 1 "Heck_Crash" 0 "kein_Heck_Crash" ;
VAL_ 80 AB1_Fa_Seite 1 "Seiten_Crash_Fahrer" 0 "kein_Seiten_Crash_Fahrer" ;
VAL_ 80 AB1_Bf_Seite 1 "Seiten_Crash_Beifahrer" 0 "kein_Seiten_Crash_Beifahrer" ;
VAL_ 80 AB1_Rollover 1 "Rollover" 0 "kein_Rollover" ;
VAL_ 80 AB1_Gurt_Fa 3 "Gurt_gesteckt" 2 "Gurt_nicht_gesteckt" 1 "Fehler" 0 "nicht_verfuegbar" ;
VAL_ 80 AB1_Intens 7 "RDW_Schw_ueberschritten" 6 "RDW_Schw_ueberschritten" 5 "RDW_Schw_ueberschritten" 4 "RDW_Schw_ueberschritten" 3 "US_Schw_ueberschritten" 2 "US_Schw_ueberschritten" 1 "Gurtstraffer_Schw_ueberschritten" 0 "kein_Crash" ;
VAL_ 80 AB1_Lampe 1 "Lampe_ein" 0 "Lampe_aus" ;
VAL_ 80 AB1_Status 1 "deaktiviert" 0 "aktiv" ;
VAL_ 80 AB1_Beifahrer 1 "deaktiviert" 0 "aktiv" ;
VAL_ 80 AB1_System 1 "Systemfehler" 0 "kein_Fehler" ;
VAL_ 80 AB1_Gurt_Bf 3 "Gurt_gesteckt" 2 "Gurt_nicht_gesteckt" 1 "Fehler" 0 "nicht_verfuegbar" ;
VAL_ 80 AB1_Diagnose 1 "in_Diagnose" 0 "nicht_in_Diagnose" ;
VAL_ 80 AB1_Stellglied 1 "im_Stellgliedtest" 0 "nicht_im_Stellgliedtest" ;
VAL_ 80 AB1_BF_Warnung 1 "Gurtwarnung_ausloesen" 0 "keine_Warnung" ;
VAL_ 80 AB1_Fehlereintr 1 "Fehlerspeichereintrag" 0 "kein_Fehlerspeichereintrag" ;
VAL_ 704 AL1_Fehler 1 "Fehler" 0 "kein_Fehler" ;
VAL_ 704 AL1_Uebertemp 1 "Uebertemperatur" 0 "keine_Uebertemperatur" ;
VAL_ 704 AL1_Sta_Kup 1 "dynamisch_nicht_erfuellbar" 0 "erfuellbar" ;
VAL_ 704 AL1_Kup_offen 1 "Kupplung_komplett_offen" 0 "Kupplung_nicht_komplett_offen" ;
VAL_ 704 AL1_Notlauf 1 "Notlaufbetrieb" 0 "alles_i_O" ;
VAL_ 704 AL1_Warnlampe 1 "Lampe_ein" 0 "Lampe_aus" ;
VAL_ 704 AL1_Einheit 1 "Prozente" 0 "Nm" ;
VAL_ 704 AL1_Ist_Nm 255 "Fehler" 254 "Kupplung_ganz_geschl" 127 "Kupplung_schnell_offen" ;
VAL_ 704 AL1_Ist_Proz 255 "Fehler" 254 "Kupplung_geschl_100_Prozent" 128 "Kupplung_offen_0_Prozent" 127 "Kupplung_schnell_offen" ;
VAL_ 704 AL1_Limiter 1 "Geschwindigkeitsbegrenzung" 0 "keine_Begrenzung" ;
VAL_ 704 AL1_Sta_PNG 7 "PNG_Fehlersignal" 6 "Low_Lock" 5 "High_Lock" 4 "Neutral" 3 "frei" 2 "Low_Unlock_PNG_in_LOW_Stellung" 1 "High_Unlock_Normal" 0 "Init" ;
VAL_ 704 AL1_Anz_blinken 1 "Blinken_der_PNG_Anzeige" 0 "kein_Blinken_der_PNG_Anzeige" ;
VAL_ 704 AL1_Sta_Laengssp 3 "Fehler_Verteilergetriebe" 2 "Fehler_Sperre" 1 "Sperre_vom_Fahrer_aktiviert" 0 "Sperre_im_Regelmodus" ;
VAL_ 704 AL1_Sta_Quersp 3 "Fehler_Verteilergetriebe" 2 "Fehler_Sperre" 1 "Sperre_vom_Fahrer_aktiviert" 0 "Sperre_im_Regelmodus" ;
VAL_ 704 AL1_Schalten 1 "Schaltung_laeuft" 0 "keine_Schaltung" ;
VAL_ 704 AL1_Vorwarnung 1 "Schaltung_wird_durchgefuehrt" 0 "keine_Schaltung" ;
VAL_ 704 AL1_Stellung_Getr 1 "Schaltgetriebe_in_Neutralstlg" 0 "Schaltgetrieb_nicht_in_Neutrstlg" ;
VAL_ 704 AL1_AnfVerteiler 1 "Verteiler_Anforderung" 0 "keine_Anforderung" ;
VAL_ 704 AL1_Sta_VA 3 "Notlauf_VA_Sperre" 2 "Fehler_Sperre" 1 "Sperre_vom_Fahrer_aktiviert" 0 "Sperre_im_Regelmodus" ;
VAL_ 704 AL1_KupSteifig_F 1 "Kupplungssteifigkeit_0_Prozent" 0 "Kupplungssteifigkeit_unbekannt" ;
VAL_ 704 AL1_Fehlereintr 1 "Fehlerspeichereintrag" 0 "kein_Fehlerspeichereintrag" ;
VAL_ 704 AL1_KupplTemp 255 "Fehler" 254 "INIT" ;
VAL_ 704 AL1_FaWu_Laengs 3 "Fehler_Fahrwerksschalter" 1 "Lockwunsch_Fahrer" 0 "Kein_Fahrerwunsch" ;
VAL_ 704 AL1_FaWu_HA 3 "Fehler_Fahrwerksschalter" 1 "Lockwunsch_Fahrer" 0 "Kein_Fahrerwunsch" ;
VAL_ 704 AL1_FaWu_VA 3 "Fehler_Fahrwerksschalter" 1 "Lockwunsch_Fahrer" 0 "Kein_Fahrerwunsch" ;
VAL_ 704 AL1_Quersp_Sta 3 "Diffsperre_verfaehrt" 2 "Diffsperre_offen" 1 "Diffsperre_geschl" 0 "Fehler" ;
VAL_ 704 AL1_Limit_maxkmh 255 "Fehler" ;
VAL_ 704 AL1_Diff_Verbau 1 "Diffsperre_verbaut" 0 "Diffsperre_nicht_verbaut" ;
VAL_ 704 AL1_Diff_Lampe 1 "Lampe_ein" 0 "Lampe_aus" ;
VAL_ 704 AL1_Diff_Gong 1 "Gong_ein" 0 "Gong_aus" ;
VAL_ 704 AL1_Warnton 1 "Warnton" 0 "kein_Warnton" ;
VAL_ 870 AWV_1_Freigabe 1 "freigegeben" 0 "nicht_freigegeben" ;
VAL_ 870 AWV_1_Prefill 1 "Prefill_Anf" 0 "keine_Prefill_Anf" ;
VAL_ 870 AWV_1_Parameter 3 "Par_hoechster_Empf" 2 "Par_erh_Empf" 1 "Par_leicht_erh_Empf" 0 "Defaultparametersatz" ;
VAL_ 870 AWV_2_Freigabe 1 "Ruckfreigabe" 0 "keine_Ruckfreigabe" ;
VAL_ 870 AWV_2_Ruckprofil 7 "nicht_erlaubt" 6 "nicht_erlaubt" 5 "Ruckprofil_5" 4 "Ruckprofil_4" 3 "Ruckprofil_3" 2 "Ruckprofil_2" 1 "Ruckprofil_1" 0 "kein_Ruck" ;
VAL_ 870 AWV_Text 14 "FrontAssist_zur_Zeit_nicht_verfuegbar__rev_Fehler" 13 "Funktion_vom_Fahrer_aktiviert" 12 "Funktion_vom_Fahrer_deaktiviert" 11 "Service_notwendig_Fehler" 10 "Sensor_reinigen" 9 "Sensor_nicht_verfuegbar" 8 "Bremsung_wird_gerade_durchgefuehrt" 7 "Vorhalt" 6 "FrontAssist_Demo" 5 "FrontAssist_Fehler" 4 "FrontAssist_Sens_reinig" 3 "FrontAssist_Warnung" 2 "FrontAssist_startet" 1 "FrontAssist_aus" 0 "kein_Text" ;
VAL_ 870 AWV_CityANB_Auspraegung 1 "autom_Bremsung_im_def_vBereich" 0 "autom_Bremsung_im_ges_vBereich" ;
VAL_ 870 AWV_2_Status 1 "Lampe_ein" 0 "Lampe_aus" ;
VAL_ 870 AWV_2_Fehler 1 "Lampe_ein" 0 "Lampe_aus" ;
VAL_ 870 AWV_2_SU_Warnzeit 3 "adaptiv" 2 "spaet" 1 "normal" 0 "frueh" ;
VAL_ 870 AWV_2_SU_Bremsruck 1 "Bremsruck_aktiviert" 0 "Bremsruck_deaktiviert" ;
VAL_ 870 AWV_2_SU_Gong 1 "Gong_aktiviert" 0 "Gong_deaktiviert" ;
VAL_ 870 AWV_2_SU_Lampe 1 "Lampe_aktiviert" 0 "Lampe_deaktiviert" ;
VAL_ 870 AWV_2_Umfeldwarn 1 "Warnung" 0 "keine_Warnung" ;
VAL_ 870 AWV_2_Warnton 1 "Ein" 0 "Aus" ;
VAL_ 870 AWV_2_Warnsymbol 1 "Ein" 0 "Aus" ;
VAL_ 870 AWV_Infoton 1 "Ein" 0 "Aus" ;
VAL_ 870 AWV_2_Gurtstraffer 1 "Gurt_straffen" 0 "Gurt_nicht_straffen" ;
VAL_ 870 AWV_Konfiguration_Menueanf 1 "Menue_aktivieren" 0 "Menue_deaktivieren" ;
VAL_ 870 AWV_Konfiguration_Vorw_Menueanf 1 "Menue_aktivieren" 0 "Menue_deaktivieren" ;
VAL_ 870 AWV_Konfiguration_Status 1 "AWV_aktiv" 0 "AWV_inaktiv" ;
VAL_ 870 AWV_Konfiguration_Vorw_Status 1 "AWV_Vorwarnung_aktiv" 0 "AWV_Vorwarnung_inaktiv" ;
VAL_ 870 AWV_2_Abstandswarnung 1 "Warnhinweis" 0 "kein_Warnhinweis" ;
VAL_ 870 AWV_only 1 "AWV_ohne_ACC_verbaut" 0 "ACC_und_AWV_verbaut" ;
VAL_ 870 AWV_Halten 1 "Anforderung_das_Fzg_im_Stillstand_zu_halten" 0 "keine_Anforderung" ;
VAL_ 870 ANB_Teilbremsung_Freigabe 1 "Teilbremsung_freigegeben" 0 "Teilbremsung_nicht_freigegeben" ;
VAL_ 870 ANB_Zielbremsung_Freigabe 1 "Zielbremsung_freigegeben" 0 "Zielbremsung_nicht_freigegeben" ;
VAL_ 870 ANB_CM_Anforderung 1 "Anforderung_aktiv" 0 "keine_Anforderung" ;
VAL_ 1392 BSL_ZAS_Kl_15 1 "Klemme_15_aktiv" 0 "Grundzustand" ;
VAL_ 1392 BSL_BSG_3_alt 1 "veraltet" 0 "aktuell_empfangen" ;
VAL_ 1392 BSL_Starterlaubnis 1 "Start_erlaubt" 0 "Start_nicht_erlaubt" ;
VAL_ 1392 BSL_Parklicht 1 "Klemme_P_aktiv" 0 "Grundzustand" ;
VAL_ 1392 BSL_LL_Anheb2 1 "Drehzahlanheb_Stufe2_gefordert" 0 "Grundzustand" ;
VAL_ 1392 BSL_Kl_15_Motor 1 "Klemme_14_aktiv" 0 "Grundzustand" ;
VAL_ 1392 BSL_Kl_L 1 "Klemme_L_aktiv" 0 "Grundzustand" ;
VAL_ 1392 BSL_LL_Anheb 1 "Drehzahlanheb_Stufe1_gefordert" 0 "Grundzustand" ;
VAL_ 1392 BSL_Sta_StBat 3 "Fehler" 2 "entladen" 1 "kritisch" 0 "iO" ;
VAL_ 1392 BSL_Fehlereintr 1 "Fehlerspeichereintrag" 0 "kein_Fehlerspeichereintrag" ;
VAL_ 1392 BSL_Sta_LWR 1 "LWR_Fehler" 0 "LWR_i_O" ;
VAL_ 1392 BSL_Motor_Haube 1 "Haube_offen" 0 "Haube_geschlossen" ;
VAL_ 1392 BSL_Hecksch 1 "Verbraucher_abschalten" 0 "Grundzustand" ;
VAL_ 1392 BSL_Frontsch 1 "Verbraucher_abschalten" 0 "Grundzustand" ;
VAL_ 1392 BSL_Aussensp 1 "Verbraucher_abschalten" 0 "Grundzustand" ;
VAL_ 1392 BSL_Sitzheiz 1 "Verbraucher_abschalten" 0 "Grundzustand" ;
VAL_ 1392 BSL_Lenkradheiz 1 "Verbraucher_abschalten" 0 "Grundzustand" ;
VAL_ 1392 BSL_Wasserheiz 1 "Verbraucher_abschalten" 0 "Grundzustand" ;
VAL_ 1392 BSL_Sitzbelueft 1 "Verbraucher_abschalten" 0 "Grundzustand" ;
VAL_ 1392 BSL_Clima 1 "Verbraucher_abschalten" 0 "Grundzustand" ;
VAL_ 1392 BSL_BSG_2_alt 1 "veraltet" 0 "aktuell_empfangen" ;
VAL_ 1392 BSL_Kuehlerlueft 1 "einschalten" 0 "keine_Anforderung" ;
VAL_ 1392 BSL_Ab_Batterie 1 "Batterie_ab" 0 "Batterie_am_Bordnetz" ;
VAL_ 1392 BSL_Weckursache_ACAN 3 "Weckursache_Tuerkontakt" 2 "Weckursache_StHzg" 1 "Weckursache_Tanken" 0 "keine_Weckursache" ;
VAL_ 1392 BSL_Wake_Up_ACAN 1 "Wecken_ACAN" 0 "kein_Wecken_ACAN" ;
VAL_ 1392 BSL_ZAS_Kl_S 1 "S_Kontakt_aktiv" 0 "Grundzustand" ;
VAL_ 1392 BSL_ZAS_Kl_X 1 "Klemme_X_aktiv" 0 "Grundzustand" ;
VAL_ 1392 BSL_ZAS_Kl_50 1 "Klemme_50_aktiv" 0 "Grundzustand" ;
VAL_ 1392 BSL_Sta_UBat 3 "Fehler" 2 "entladen" 1 "kritisch" 0 "iO" ;
VAL_ 1392 BSL_UBat 255 "Fehler" ;
VAL_ 2000 DI1_VerlernZaehl 255 "Fehler" ;
VAL_ 2000 DI1_Monat 15 "Spezialfall" 14 "relatives_Datum" 13 "ungueltig" 0 "ungueltig" ;
VAL_ 2000 DI1_Stunde 31 "ungueltig" 30 "ungueltig" 29 "ungueltig" 28 "ungueltig" 27 "ungueltig" 26 "ungueltig" 25 "ungueltig" 24 "ungueltig" ;
VAL_ 2000 DI1_Minute 63 "ungueltig" 62 "ungueltig" 61 "ungueltig" 60 "ungueltig" ;
VAL_ 2000 DI1_Sekunde 63 "ungueltig" 62 "ungueltig" 61 "ungueltig" 60 "ungueltig" ;
VAL_ 2000 DI1_KM_Stand_alt 1 "veraltet" 0 "aktuell_empfangen" ;
VAL_ 2000 DI1_Zeit_alt 1 "veraltet" 0 "aktuell_empfangen" ;
VAL_ 1088 GE1_Schaltung 1 "Schaltung_laeuft" 0 "keine_Schaltung" ;
VAL_ 1088 GE1_Zielgang 15 "Fehler" 14 "Istgang_nicht_definiert" 10 "Gang_8" 9 "Gang_7" 8 "Gang_6" 7 "Gang_R" 6 "_1m_Gang" 5 "Gang_5" 4 "Gang_4" 3 "Gang_3" 2 "Gang_2" 1 "Gang_1" 0 "Gang_P_N_ausgekuppelt" ;
VAL_ 1088 GE1_Wahl_Pos 15 "Fehler" 14 "Tipp_Gasse_oder_Manual_Selespeed" 13 "Pos_L" 12 "Pos_S_oder_Automatic_Sport_Selespeed" 11 "Pos_Z2" 10 "Pos_Z1" 9 "Pos_RSP_oder_Manual_Sport_Selespeed" 8 "Pos_P_oder_Key_Lock_Release_Selespeed" 7 "Pos_R" 6 "Pos_N" 5 "Pos_D_oder_Automatic_Selespeed" 4 "Pos_4" 3 "Pos_3" 2 "Pos_2" 1 "Pos_1" 0 "Zwischenstellung" ;
VAL_ 1088 GE1_Mrad_Mkurb 255 "Fehler" ;
VAL_ 1088 GE1_Notlauf 15 "Totalausfall" 7 "kein_Notlauf" 6 "kein_Notlauf" 5 "kein_Notlauf" 4 "Fahren_ohne_UEK" 3 "Schalten_50_Prozent" 2 "Schalten_nach_n" 1 "kein_Schalten" ;
VAL_ 1088 GE1_Sta_Schutz 1 "Schutz_angefordert" 0 "kein_Schutz" ;
VAL_ 1088 GE1_Klimakompr 1 "Kompressor_aus" 0 "keine_Anforderung" ;
VAL_ 1088 GE1_WK 3 "Fehler" 2 "WK_geschlossen" 1 "WK_geregelt" 0 "WK_geoeffnet" ;
VAL_ 1088 GE1_StSt_Info 3 "Systemfehler" 2 "Motoranlauf_zwingend_notwendig_(Startanforderung)" 1 "Motoranlauf_nicht_zwingend_notwendig_(Stoppverbot,keine_Startanforderung)" 0 "Motorlauf_nicht_notwendig_(Stoppfreigabe)" ;
VAL_ 1088 GE1_EGS_Anf 1 "EGS_Anforderung" 0 "keine_Anforderung" ;
VAL_ 1088 GE1_Soll_Mo 255 "Fehler" ;
VAL_ 1088 GE1_Fahrwistd 255 "Fehler" ;
VAL_ 1088 GE1_Kuehlung 3 "Stufe_3" 2 "Stufe_2" 1 "Stufe_1" 0 "OFF" ;
VAL_ 1088 GE1_Sta_OBD 1 "MIL_ein" 0 "MIL_aus" ;
VAL_ 1088 GE1_LaunchControl 1 "aktiv" 0 "nicht_aktiv" ;
VAL_ 1088 GE1_Infobit 1 "CVT" 0 "Stufenautomat" ;
VAL_ 1088 GE1_SleepInd 1 "Sleep_bereit" 0 "CAN_wird_benoetigt" ;
VAL_ 1088 GE1_Fehlereintr 1 "Fehlerspeichereintrag" 0 "kein_Fehlerspeichereintrag" ;
VAL_ 1088 GE1_WaVerl_Mo 255 "Fehler" ;
VAL_ 1056 KO2_gef_Auss_T 255 "Fehler" ;
VAL_ 1056 KO2_Verb_TOG 1 "TOG_nicht_verbaut" 0 "TOG_verbaut" ;
VAL_ 1056 KO2_Oelwarn 1 "Schwelle_ueberschritten" 0 "Schwelle_nicht_ueberschritten" ;
VAL_ 1056 KO2_GRA_High 1 "ja" 0 "nein" ;
VAL_ 1056 KO2_Temp_Einheit 1 "Fahrenheit" 0 "Celsius" ;
VAL_ 1056 KO2_Wischwasser 1 "Wischwasserwarnung_aktiv" 0 "keine_Warnung" ;
VAL_ 1056 KO2_PLA_Displaystatus 1 "dargestellt" 0 "nicht_dargestellt" ;
VAL_ 1056 KO2_Fehlereintr 1 "Fehlerspeichereintrag" 0 "kein_Fehlerspeichereintrag" ;
VAL_ 1056 KO2_Aussen_T 255 "Fehler" ;
VAL_ 1056 KBI_Anzeigestatus_LIM 3 "Fehler" 2 "reserviert" 1 "Anzeigemoeglichkeit_vorhanden" 0 "nicht_vorhanden" ;
VAL_ 1056 KO_AWV_Zustandswechsel 1 "Zustandswechsel_gewuenscht" 0 "kein_Zustandswechsel" ;
VAL_ 1056 KO_AWV_Vorw_Zustandswechsel 1 "Zustandswechsel_gewuenscht" 0 "kein_Zustandswechsel" ;
VAL_ 1056 KO_Aussensound_Zustandswechsel 1 "Zustandswechsel_gewuenscht" 0 "kein_Zustandswechsel" ;
VAL_ 1056 KB2_EasyEntry 1 "aktiv" 0 "inaktiv" ;
VAL_ 1056 KO_Segeln_Menuestatus 1 "Menue_verfuegbar" 0 "kein_Menue" ;
VAL_ 1056 KO_Segeln_Zustandswechsel 1 "Zustandswechsel_gewuenscht" 0 "kein_Zustandswechsel" ;
VAL_ 1056 KB2_Auto_eKiSi 1 "aktiv" 0 "inaktiv" ;
VAL_ 1056 KO2_Bel_Displ 127 "kein_Ersatzwert" 0 "Init" ;
VAL_ 1056 KO2_Sta_Displ 1 "Kl_58d_n_iO" 0 "Kl_58d_iO" ;
VAL_ 1056 KO2_Bel_Schalt 127 "kein_Ersatzwert" ;
VAL_ 1056 KO2_Sta_Schalt 1 "Kl_58s_n_iO" 0 "Kl_58s_iO" ;
VAL_ 1056 KO2_MFA_v_Einheit 1 "mph" 0 "kmh" ;
VAL_ 1056 KO2_Passiv_Autolock 1 "aktiv" 0 "inaktiv" ;
VAL_ 1056 KO2_WFS_Schl_Ort 1 "Lesespule" 0 "keyless" ;
VAL_ 1056 KB2_MFA_Strecke_Einheit 1 "miles" 0 "km" ;
VAL_ 1056 KO2_OBD_Nib_Temp 15 "frei" 14 "frei" 13 "frei" 12 "frei" 11 "KS_MP_OC" 10 "KS_MP" 9 "KS_M_OC" 8 "KS_P_OC" 7 "RC_M" 6 "RC_P" 5 "OOR_M" 4 "OOR_P" 3 "OC" 2 "KS_P" 1 "KS_M" 0 "kein_Fehler" ;
VAL_ 1056 KO2_Sta_Auss_T 1 "n_iO" 0 "iO" ;
VAL_ 1056 KBI_rotes_P_verbaut 1 "verbaut" 0 "nicht_verbaut" ;
VAL_ 1056 KB2_Req_IstZu_Solldruecke 1 "Anforderung_Soll_gleich_Istdruck" 0 "keine_Anforderung" ;
VAL_ 1312 KO3_Land 7 "Australien" 6 "Saudi_Arabien" 5 "Japan" 4 "Grossbritannien" 3 "Kanada" 2 "USA" 1 "Europa" 0 "Deutschland" ;
VAL_ 1312 KO3_Mp_Code 3 "Verbauliste" 2 "Radumfang" 1 "Plattform" 0 "Land_Sprache" ;
VAL_ 1312 KO3_Um_AutoHold 1 "Taster_gedrueckt" 0 "Taster_nicht_gedrueckt" ;
VAL_ 1312 KO3_Sprache 39 "Ukrainisch" 38 "Litauisch" 37 "Estlaendisch" 36 "Lettisch" 35 "Bulgarisch" 34 "Finnisch" 33 "Serbisch" 32 "Slowenisch" 31 "Slowakisch" 30 "Rumaenisch" 29 "Ungarisch" 28 "Kroatisch" 27 "Griechisch" 26 "Daenisch" 25 "Bosnisch" 24 "Kantonesisch" 23 "Taiwanesisch" 22 "Arabisch" 21 "Portugiesisch_Brazil" 20 "Norwegisch" 19 "US_Spanisch" 18 "Tuerkisch" 17 "Polnisch" 16 "Schwedisch" 15 "Franko_Kanadisch" 14 "Koreanisch" 13 "Russisch" 12 "Japanisch" 11 "Niederlaendisch" 10 "US_Englisch" 9 "Chinesisch" 8 "Tschechisch" 6 "Portugiesisch" 5 "Spanisch" 4 "Italienisch" 3 "Franzoesisch" 2 "Englisch" 1 "Deutsch" 0 "keine_Sprachvar" ;
VAL_ 1312 KO3_Derivat 9 "Sonstige" 8 "MPV" 7 "City_Van_Pickup" 6 "Offroad" 5 "Cabrio_Roadster_Spider" 4 "Coupe_Sportwagen" 3 "Fliessheck" 2 "Variant" 1 "Stufenheck_Nutz" 0 "Kurzheck_Multivan" ;
VAL_ 1312 KO3_Verbau_Mot 1 "mit_CAN" 0 "ohne_CAN" ;
VAL_ 1312 KO3_Verbau_Get 1 "mit_CAN" 0 "ohne_CAN" ;
VAL_ 1312 KO3_Verbau_Br 1 "mit_CAN" 0 "ohne_CAN" ;
VAL_ 1312 KO3_Verbau_Kl 1 "mit_CAN" 0 "ohne_CAN" ;
VAL_ 1312 KO3_Verbau_Air 1 "mit_CAN" 0 "ohne_CAN" ;
VAL_ 1312 KO3_Verbau_ADR 1 "mit_CAN" 0 "ohne_CAN" ;
VAL_ 1312 KO3_Verbau_BN 1 "mit_CAN" 0 "ohne_CAN" ;
VAL_ 1312 KO3_Verbau_Syn 1 "mit_CAN" 0 "ohne_CAN" ;
VAL_ 1312 KO3_Baureihe 7 "T_Klasse" 6 "D_Klasse" 5 "C_Klasse" 4 "B_Klasse" 3 "A_Klasse" 2 "A0_Klasse" 1 "A00_Klasse" 0 "LT_Klasse" ;
VAL_ 1312 KO3_Verbau_LWS 1 "mit_CAN" 0 "ohne_CAN" ;
VAL_ 1312 KO3_Verbau_DP 1 "mit_CAN" 0 "ohne_CAN" ;
VAL_ 1312 KO3_Verbau_LH 1 "mit_CAN" 0 "ohne_CAN" ;
VAL_ 1312 KO3_Marke 7 "Ford_Porsche" 6 "Bentley_RollsRoyce" 5 "Bugatti_Lamborghini" 4 "VW_Nutzf" 3 "Skoda" 2 "Seat" 1 "Audi" 0 "VW" ;
VAL_ 1312 KO3_Verbau_Niveau 1 "mit_CAN" 0 "ohne_CAN" ;
VAL_ 1312 KBI_Oelwechsel_durchgefuehrt 1 "Oelwechsel_durchgefuehrt" 0 "Oelwechseln_nicht_durchgefuehrt" ;
VAL_ 1312 KO3_Schluessel 0 "ungueltig" ;
VAL_ 1312 KO3_Um_AFS2 1 "Taster_gedrueckt" 0 "Taster_nicht_gedrueckt" ;
VAL_ 1312 KO3_Um_Tourist 1 "Taster_gedrueckt" 0 "Taster_nicht_gedrueckt" ;
VAL_ 1312 KO3_SWA_AnzFeh 1 "Fehler" 0 "iO" ;
VAL_ 1312 KO3_Sta_Standz 1 "Kl_30_war_weg" 0 "Standzeit_iO" ;
VAL_ 978 LH2_Geradeaus 1 "Geradeausfahrt" 0 "Keine_Geradeausfahrt" ;
VAL_ 978 LH2_Sta_Charisma 3 "Sport" 2 "Normal" 1 "Komfort" 0 "deaktiv" ;
VAL_ 978 LH2_Sta_HCA 7 "Eingriff_aktiv_ohne_Act_Ret" 5 "Eingriff_aktiv_mit_Act_Ret" 4 "Anf_abgewiesen" 3 "bereit" 2 "Anf_nicht_ausf_mit_FSP" 1 "Anf_nicht_ausf_kein_FSP" 0 "deaktiv" ;
VAL_ 978 LH2_Ausg_LW1 1 "aktiviert" 0 "nicht_aktiv" ;
VAL_ 978 LH2_Ausg_LW1_gue 1 "gueltig" 0 "ungueltig" ;
VAL_ 978 LH2_aktLenkeingriff 64 "PLA" 32 "Torque_Steer" 8 "HCA" 2 "DSR" 1 "kein_Eingriff" 0 "Init" ;
VAL_ 208 LH3_LMSign 1 "negatives_Vorzeichen" 0 "positives_Vorzeichen" ;
VAL_ 208 LH3_LMValid 1 "gueltig" 0 "ungueltig" ;
VAL_ 208 LH3_Sta_DSR 7 "ext_MomLWeingriff_aktiv" 6 "ext_LWeingriff_aktiv" 5 "ext_Momeingriff_aktiv" 4 "DSR_Anf_abgew" 3 "EPS_funktionsbereit" 2 "Kom_ESP_gestoert" 1 "DSR_Anf_nicht_ausfuehrbar" 0 "DSR_deaktiviert" ;
VAL_ 208 LH3_BLWSign 1 "negatives_Vorzeichen" 0 "positives_Vorzeichen" ;
VAL_ 208 LH3_BLWValid 1 "gueltig" 0 "ungueltig" ;
VAL_ 208 LH3_Lenkungstyp 3 "EPS_DSR2" 2 "ADS_Audi_oder_CEPS_VW120" 1 "APA" 0 "EPS_DSR1" ;
VAL_ 640 MO1_Kup_schalt 1 "Schalter_sagt_eingekuppelt" 0 "Schalter_sagt_ausgekuppelt" ;
VAL_ 640 MO1_TiOut_Br 1 "Time_Out" 0 "Empfang_iO" ;
VAL_ 640 MO1_Sta_Bremse 1 "statisch_nicht_erfuellbar" 0 "erfuellbar" ;
VAL_ 640 MO1_Sta_MotMo 1 "ja" 0 "nein_Werte_iO" ;
VAL_ 640 MO1_Mo_m_ex 255 "Fehler" ;
VAL_ 640 MO1_Drehzahl 65280 "Fehler" ;
VAL_ 640 MO1_Pedalwert 255 "Fehler" ;
VAL_ 640 MO1_Verlustmo 255 "Fehler" ;
VAL_ 640 MO1_Wunschmo 255 "Fehler" ;
VAL_ 640 MO1_Leergas 1 "Leergas" 0 "kein_Leergas" ;
VAL_ 640 MO1_Sta_Pedal 1 "Ersatzwert" 0 "Fahrpedal_iO" ;
VAL_ 640 MO1_Kickdown 1 "Kickdown" 0 "kein_Kickdown" ;
VAL_ 640 MO1_Sta_Getr 1 "dynamisch_nicht_erfuellbar" 0 "erfuellbar" ;
VAL_ 640 MO1_Mo_o_ex 255 "Fehler" ;
VAL_ 648 MO2_Getr_Code 17 "E_Fahrzeug__Single_Gear" 16 "DL800" 15 "Handschalter_konv" 14 "AL1000_AL551_AL951_ZF8HPx" 12 "SQ100_SQ200" 11 "DQ500_DQ250_DQ200" 10 "AG6_Jatco_ZF_6HP_AISIN" 9 "autom_Kupplung_mit_ASG" 8 "autom_Kupplung" 7 "AG5_Jatco" 6 "AG4_Jatco" 5 "VQ35" 4 "VQ250" 3 "VL300" 2 "AG4" 1 "_5HP24" 0 "_5HP19" ;
VAL_ 648 MO2_Mp_Code 3 "MDI_Max" 2 "Getriebe_Kod" 1 "Motor_Kod" 0 "CAN_Stand" ;
VAL_ 648 MO2_BLS 1 "Bremse_betaetigt" 0 "kein_Bremsen" ;
VAL_ 648 MO2_Sta_No_Bet 1 "Normalbetrieb" 0 "kein_Normalbetrieb" ;
VAL_ 648 MO2_Sta_GRA 3 "ADR_nicht_freigegeben" 2 "uebersteuert_Lampe_an" 1 "aktiviert_Lampe_an" 0 "ADR_GRA_aus" ;
VAL_ 648 MO2_OffRoad 1 "aktiv" 0 "nicht_aktiv" ;
VAL_ 648 MO2_LL_Solldz 255 "Fehler" ;
VAL_ 648 MO2_CAN_Vers 54 "V516a_526_536_546_556_566_576_586_596" 53 "V514a_524_534_544" 50 "V496a_506" 48 "V494a_504" 47 "V493" 44 "V476c" 41 "V473a" 39 "V466a" 37 "V456" 27 "V503c_513" 26 "V436" 22 "V424e" 21 "V423d" 19 "V424b" 18 "V423a" 17 "V411c_421b_521_531_541_551_561_571_581_591" ;
VAL_ 648 MO2_Kuehlm_T 255 "Fehler" 0 "Init" ;
VAL_ 648 MO2_BTS 1 "Bremse_betaetigt" 0 "kein_Bremsen" ;
VAL_ 648 MO2_Sta_Kuehlm 1 "Temperatur_n_iO" 0 "Temperatur_iO" ;
VAL_ 648 MO2_Sta_Klima 1 "Klima_ein" 0 "Klima_aus" ;
VAL_ 648 MO2_Status_TSK 1 "TSK_verfuegbar" 0 "TSK_nicht_verfuegbar" ;
VAL_ 648 TSK_Limiter_ausgewaehlt 1 "Limiter_ausgewaehlt" 0 "kein_Limiter_ausgewaehlt" ;
VAL_ 648 MO2_GRAregelt 1 "ja" 0 "nein" ;
VAL_ 648 MO2_Sport_Error 1 "Fehler" 0 "kein_Fehler" ;
VAL_ 648 MO2_RME_Gehalt 7 "Fehler" ;
VAL_ 648 MO2_GRA_Soll 255 "Fehler" ;
VAL_ 648 MO2_Begr_Mo 255 "Fehler" ;
VAL_ 648 MO2_Mo_ZWR 255 "Fehler" ;
VAL_ 896 MO3_Pedalwert 255 "Fehler" ;
VAL_ 896 MO3_Vorgluehen 1 "Vorgluehen_aktiv" 0 "kein_Vorgluehen" ;
VAL_ 896 MO3_Prio_Dz 1 "Zwang" 0 "Wunsch" ;
VAL_ 896 MO_Schalter_StartStopp 1 "StartStopp_ueber_Hauptschalter_aktiviert__LED_aus" 0 "StartStopp_ueber_Hauptschalter_deaktiviert__LED_an" ;
VAL_ 896 MO3_Winterprg 1 "aktiv" 0 "nicht_aktiv" ;
VAL_ 896 MO3_Sta_FPG 1 "Gradient_bed" 0 "Gradient_nicht_bed" ;
VAL_ 896 MO3_Sign_FPG 1 "negatives_Vorzeichen" 0 "positives_Vorzeichen" ;
VAL_ 896 MO3_Sta_Temp 1 "Ersatzwert" 0 "Geber_iO" ;
VAL_ 896 MO3_Aussentemp 255 "Fehler" ;
VAL_ 896 MO3_Rad_Wu_Mo 4095 "Fehler" ;
VAL_ 896 MO3_Vorz_RadWu 1 "negatives_Vorzeichen" 0 "positives_Vorzeichen" ;
VAL_ 896 MO3_Freigabe_Segeln 1 "Segelbetrieb_freigegeben" 0 "Segelbetrieb_nicht_freigegeben" ;
VAL_ 896 MO_StartStopp_StoppVorbereitung 1 "Motorstopp_in_Vorbereitung" 0 "Motorstopp_nicht_in_Vorbereitung" ;
VAL_ 896 MO3_WunschDz 255 "Fehler" ;
VAL_ 896 MO3_DKW 255 "Fehler" ;
VAL_ 896 MO3_FPGradient 255 "Fehler" ;
VAL_ 896 MO3_Sta_Pedal 1 "Ersatzwert" 0 "Fahrpedal_iO" ;
